VERSION "dbc-export 1 2026.26.6.5"

NS_ :

BS_:

BU_: ADSP APB APP APS APSB BB BMS CC CMP CMPD CP DAS DI DIF DIR DPB EPAS3P EPAS3S EPASTP EPASTS EPBL EPBR ESP EVSE FC GTW HCML HCMR HVP IBST ICR IDB LS OCS1P PARK PCS PCS2 PM PMF PMR PNCD PTC RADC RCM RCM2 RCM3 RCU SCCM SCM SCS SDCR TAS TCU TCU2 TPMS TRCM UI UIS UMC USM V2G VC VCBATT VCBATT0 VCBATT1 VCBATT2 VCCC VCFRONT VCFRONT1 VCFRONT2 VCLEFT VCRIGHT VCSEAT2L VCSEAT2R VCSEC VEH

BO_ 832 VCFRONT_alertMatrix: 8 VCFRONT
 SG_ VCFRONT_matrixIndex M : 0|4@1+ (1,0) [0|15] "" Vector__XXX
 SG_ VCFRONT_a001_WatchdogReset m0 : 4|1@1+ (1,0) [0|1] "" Vector__XXX
 SG_ VCFRONT_a002_PowerLossReset m0 : 5|1@1+ (1,0) [0|1] "" Vector__XXX
 SG_ VCFRONT_a003_SWAssertion m0 : 6|1@1+ (1,0) [0|1] "" Vector__XXX
 SG_ VCFRONT_a004_adaptiveHeadlightsU m0 : 7|1@1+ (1,0) [0|1] "" Vector__XXX
 SG_ VCFRONT_a005_CANTXError m0 : 8|1@1+ (1,0) [0|1] "" Vector__XXX
 SG_ VCFRONT_a006_CANTX_cyclicError m0 : 9|1@1+ (1,0) [0|1] "" Vector__XXX
 SG_ VCFRONT_a008_adaptiveHeadlightsU m0 : 11|1@1+ (1,0) [0|1] "" Vector__XXX
 SG_ VCFRONT_a009_LCCPurgeAttempted m0 : 12|1@1+ (1,0) [0|1] "" Vector__XXX
 SG_ VCFRONT_a010_ExtSupplyVoltError m0 : 13|1@1+ (1,0) [0|1] "" Vector__XXX
 SG_ VCFRONT_a012_CPUReset m0 : 15|1@1+ (1,0) [0|1] "" Vector__XXX
 SG_ VCFRONT_a013_AlertManagerFault m0 : 16|1@1+ (1,0) [0|1] "" Vector__XXX
 SG_ VCFRONT_a015_NVMMError m0 : 18|1@1+ (1,0) [0|1] "" Vector__XXX
 SG_ VCFRONT_a016_NVMMRecordError m0 : 19|1@1+ (1,0) [0|1] "" Vector__XXX
 SG_ VCFRONT_a017_NVMMStatusDbg m0 : 20|1@1+ (1,0) [0|1] "" Vector__XXX
 SG_ VCFRONT_a021_TaskSchedulerError m0 : 24|1@1+ (1,0) [0|1] "" Vector__XXX
 SG_ VCFRONT_a022_TaskInitError m0 : 25|1@1+ (1,0) [0|1] "" Vector__XXX
 SG_ VCFRONT_a029_CoreDump m0 : 32|1@1+ (1,0) [0|1] "" Vector__XXX
 SG_ VCFRONT_a030_ECULogUploadRequest m0 : 33|1@1+ (1,0) [0|1] "" Vector__XXX
 SG_ VCFRONT_a031_UDSActive m0 : 34|1@1+ (1,0) [0|1] "" Vector__XXX
 SG_ VCFRONT_a032_ipcWatchdogExpired m0 : 35|1@1+ (1,0) [0|1] "" Vector__XXX
 SG_ VCFRONT_a033_eccNonCorrectableEr m0 : 36|1@1+ (1,0) [0|1] "" Vector__XXX
 SG_ VCFRONT_a038_ProtFaultInfo m0 : 41|1@1+ (1,0) [0|1] "" Vector__XXX
 SG_ VCFRONT_a039_ProtFaultAddress m0 : 42|1@1+ (1,0) [0|1] "" Vector__XXX
 SG_ VCFRONT_a040_Backtrace m0 : 43|1@1+ (1,0) [0|1] "" Vector__XXX
 SG_ VCFRONT_a041_HighCPULoad m0 : 44|1@1+ (1,0) [0|1] "" Vector__XXX
 SG_ VCFRONT_a042_HighStackUsage m0 : 45|1@1+ (1,0) [0|1] "" Vector__XXX
 SG_ VCFRONT_a043_Task1msError m0 : 46|1@1+ (1,0) [0|1] "" Vector__XXX
 SG_ VCFRONT_a044_Task10msError m0 : 47|1@1+ (1,0) [0|1] "" Vector__XXX
 SG_ VCFRONT_a045_Task100msError m0 : 48|1@1+ (1,0) [0|1] "" Vector__XXX
 SG_ VCFRONT_a046_Task1000msError m0 : 49|1@1+ (1,0) [0|1] "" Vector__XXX
 SG_ VCFRONT_a047_resetReason m0 : 50|1@1+ (1,0) [0|1] "" Vector__XXX
 SG_ VCFRONT_a053_wiperCommErrorUser m0 : 56|1@1+ (1,0) [0|1] "" Vector__XXX
 SG_ VCFRONT_a054_compressorLowFlowUs m0 : 57|1@1+ (1,0) [0|1] "" Vector__XXX
 SG_ VCFRONT_a057_HVP_MIA m0 : 60|1@1+ (1,0) [0|1] "" Vector__XXX
 SG_ VCFRONT_a058_inputRHighSyncDebug m0 : 61|1@1+ (1,0) [0|1] "" Vector__XXX
 SG_ VCFRONT_a059_inputResistanceHigh m0 : 62|1@1+ (1,0) [0|1] "" Vector__XXX
 SG_ VCFRONT_a060_engineeringBuild m0 : 63|1@1+ (1,0) [0|1] "" Vector__XXX
 SG_ VCFRONT_a061_XCPConnected m1 : 4|1@1+ (1,0) [0|1] "" Vector__XXX
 SG_ VCFRONT_a062_XCPWasConnected m1 : 5|1@1+ (1,0) [0|1] "" Vector__XXX
 SG_ VCFRONT_a063_SwitchFault m1 : 6|1@1+ (1,0) [0|1] "" Vector__XXX
 SG_ VCFRONT_a064_busSleepReqTimeout m1 : 7|1@1+ (1,0) [0|1] "" Vector__XXX
 SG_ VCFRONT_a082_VCRIGHT_IPC_MIA m1 : 25|1@1+ (1,0) [0|1] "" Vector__XXX
 SG_ VCFRONT_a083_VCLEFT_IPC_MIA m1 : 26|1@1+ (1,0) [0|1] "" Vector__XXX
 SG_ VCFRONT_a084_TPMS_MIA m1 : 27|1@1+ (1,0) [0|1] "" Vector__XXX
 SG_ VCFRONT_a085_CCCM_MIA m1 : 28|1@1+ (1,0) [0|1] "" Vector__XXX
 SG_ VCFRONT_a086_VCBATT_MIA m1 : 29|1@1+ (1,0) [0|1] "" Vector__XXX
 SG_ VCFRONT_a087_DIREL_MIA m1 : 30|1@1+ (1,0) [0|1] "" Vector__XXX
 SG_ VCFRONT_a088_DIRER_MIA m1 : 31|1@1+ (1,0) [0|1] "" Vector__XXX
 SG_ VCFRONT_a089_IBST_MIA m1 : 32|1@1+ (1,0) [0|1] "" Vector__XXX
 SG_ VCFRONT_a090_APS_MIA m1 : 33|1@1+ (1,0) [0|1] "" Vector__XXX
 SG_ VCFRONT_a091_CMPD_MIA m1 : 34|1@1+ (1,0) [0|1] "" Vector__XXX
 SG_ VCFRONT_a092_VCSEATD_MIA m1 : 35|1@1+ (1,0) [0|1] "" Vector__XXX
 SG_ VCFRONT_a093_VCSEATP_MIA m1 : 36|1@1+ (1,0) [0|1] "" Vector__XXX
 SG_ VCFRONT_a094_EPAS3P_MIA m1 : 37|1@1+ (1,0) [0|1] "" Vector__XXX
 SG_ VCFRONT_a095_CHG_MIA m1 : 38|1@1+ (1,0) [0|1] "" Vector__XXX
 SG_ VCFRONT_a096_OCS1P_MIA m1 : 39|1@1+ (1,0) [0|1] "" Vector__XXX
 SG_ VCFRONT_a097_CMP_MIA m1 : 40|1@1+ (1,0) [0|1] "" Vector__XXX
 SG_ VCFRONT_a098_DIR_MIA m1 : 41|1@1+ (1,0) [0|1] "" Vector__XXX
 SG_ VCFRONT_a099_PARK_MIA m1 : 42|1@1+ (1,0) [0|1] "" Vector__XXX
 SG_ VCFRONT_a100_CANbus_MIA m1 : 43|1@1+ (1,0) [0|1] "" Vector__XXX
 SG_ VCFRONT_a101_PM_MIA m1 : 44|1@1+ (1,0) [0|1] "" Vector__XXX
 SG_ VCFRONT_a102_PTC_MIA m1 : 45|1@1+ (1,0) [0|1] "" Vector__XXX
 SG_ VCFRONT_a103_CP_MIA m1 : 46|1@1+ (1,0) [0|1] "" Vector__XXX
 SG_ VCFRONT_a104_DAS_MIA m1 : 47|1@1+ (1,0) [0|1] "" Vector__XXX
 SG_ VCFRONT_a105_TAS_MIA m1 : 48|1@1+ (1,0) [0|1] "" Vector__XXX
 SG_ VCFRONT_a106_PCS_MIA m1 : 49|1@1+ (1,0) [0|1] "" Vector__XXX
 SG_ VCFRONT_a107_BMS_MIA m1 : 50|1@1+ (1,0) [0|1] "" Vector__XXX
 SG_ VCFRONT_a108_DIF_MIA m1 : 51|1@1+ (1,0) [0|1] "" Vector__XXX
 SG_ VCFRONT_a109_RCM_MIA m1 : 52|1@1+ (1,0) [0|1] "" Vector__XXX
 SG_ VCFRONT_a110_GTW_MIA m1 : 53|1@1+ (1,0) [0|1] "" Vector__XXX
 SG_ VCFRONT_a111_EPBR_MIA m1 : 54|1@1+ (1,0) [0|1] "" Vector__XXX
 SG_ VCFRONT_a112_EPBL_MIA m1 : 55|1@1+ (1,0) [0|1] "" Vector__XXX
 SG_ VCFRONT_a113_UI_MIA m1 : 56|1@1+ (1,0) [0|1] "" Vector__XXX
 SG_ VCFRONT_a114_ESP_MIA m1 : 57|1@1+ (1,0) [0|1] "" Vector__XXX
 SG_ VCFRONT_a115_VCSEC_MIA m1 : 58|1@1+ (1,0) [0|1] "" Vector__XXX
 SG_ VCFRONT_a116_VCRIGHT_MIA m1 : 59|1@1+ (1,0) [0|1] "" Vector__XXX
 SG_ VCFRONT_a117_VCLEFT_MIA m1 : 60|1@1+ (1,0) [0|1] "" Vector__XXX
 SG_ VCFRONT_a118_VCFRONT_MIA m1 : 61|1@1+ (1,0) [0|1] "" Vector__XXX
 SG_ VCFRONT_a119_SCCM_MIA m1 : 62|1@1+ (1,0) [0|1] "" Vector__XXX
 SG_ VCFRONT_a120_DI_DRIVE_MIA m1 : 63|1@1+ (1,0) [0|1] "" Vector__XXX
 SG_ VCFRONT_a121_pumpBatICLatchFault m2 : 4|1@1+ (1,0) [0|1] "" Vector__XXX
 SG_ VCFRONT_a122_pumpBatICWarning m2 : 5|1@1+ (1,0) [0|1] "" Vector__XXX
 SG_ VCFRONT_a123_pumpPtICLatchFault m2 : 6|1@1+ (1,0) [0|1] "" Vector__XXX
 SG_ VCFRONT_a124_pumpPtICWarning m2 : 7|1@1+ (1,0) [0|1] "" Vector__XXX
 SG_ VCFRONT_a125_thmlFanICLatchFault m2 : 8|1@1+ (1,0) [0|1] "" Vector__XXX
 SG_ VCFRONT_a126_thmlFanICWarning m2 : 9|1@1+ (1,0) [0|1] "" Vector__XXX
 SG_ VCFRONT_a127_vcleftEFuseTrip m2 : 10|1@1+ (1,0) [0|1] "" Vector__XXX
 SG_ VCFRONT_a128_vcrightEFuseTrip m2 : 11|1@1+ (1,0) [0|1] "" Vector__XXX
 SG_ VCFRONT_a129_pcsEFuseTrip m2 : 12|1@1+ (1,0) [0|1] "" Vector__XXX
 SG_ VCFRONT_a130_epas3pEFuseTrip m2 : 13|1@1+ (1,0) [0|1] "" Vector__XXX
 SG_ VCFRONT_a131_epas3sEFuseTrip m2 : 14|1@1+ (1,0) [0|1] "" Vector__XXX
 SG_ VCFRONT_a132_iBoosterEFuseTrip m2 : 15|1@1+ (1,0) [0|1] "" Vector__XXX
 SG_ VCFRONT_a133_espEFuseTrip m2 : 16|1@1+ (1,0) [0|1] "" Vector__XXX
 SG_ VCFRONT_a134_fusedHighEFuseTrip m2 : 17|1@1+ (1,0) [0|1] "" Vector__XXX
 SG_ VCFRONT_a135_coolantLevelLow m2 : 18|1@1+ (1,0) [0|1] "" Vector__XXX
 SG_ VCFRONT_a136_refrigDischTempSns m2 : 19|1@1+ (1,0) [0|1] "" Vector__XXX
 SG_ VCFRONT_a137_refrigDischPresSns m2 : 20|1@1+ (1,0) [0|1] "" Vector__XXX
 SG_ VCFRONT_a138_refrigSuctTempSns m2 : 21|1@1+ (1,0) [0|1] "" Vector__XXX
 SG_ VCFRONT_a139_refrigSuctPresSns m2 : 22|1@1+ (1,0) [0|1] "" Vector__XXX
 SG_ VCFRONT_a140_coolantTempPtSns m2 : 23|1@1+ (1,0) [0|1] "" Vector__XXX
 SG_ VCFRONT_a141_coolantTempBatSns m2 : 24|1@1+ (1,0) [0|1] "" Vector__XXX
 SG_ VCFRONT_a142_exvMotorFault m2 : 25|1@1+ (1,0) [0|1] "" Vector__XXX
 SG_ VCFRONT_a143_pumpBatICTransFault m2 : 26|1@1+ (1,0) [0|1] "" Vector__XXX
 SG_ VCFRONT_a144_pumpPtICTransFault m2 : 27|1@1+ (1,0) [0|1] "" Vector__XXX
 SG_ VCFRONT_a145_thmlFanICTransFault m2 : 28|1@1+ (1,0) [0|1] "" Vector__XXX
 SG_ VCFRONT_a146_pumpBatSoftStall m2 : 29|1@1+ (1,0) [0|1] "" Vector__XXX
 SG_ VCFRONT_a147_pumpPtSoftStall m2 : 30|1@1+ (1,0) [0|1] "" Vector__XXX
 SG_ VCFRONT_a148_thmlFanSoftStall m2 : 31|1@1+ (1,0) [0|1] "" Vector__XXX
 SG_ VCFRONT_a149_BLEFrontPowerCycled m2 : 32|1@1+ (1,0) [0|1] "" Vector__XXX
 SG_ VCFRONT_a150_pumpBatLowRPMCBang m2 : 33|1@1+ (1,0) [0|1] "" Vector__XXX
 SG_ VCFRONT_a151_pumpPtLowRPMCBang m2 : 34|1@1+ (1,0) [0|1] "" Vector__XXX
 SG_ VCFRONT_a152_thmlFanLowRPMCBang m2 : 35|1@1+ (1,0) [0|1] "" Vector__XXX
 SG_ VCFRONT_a153_userPresenceDisplay m2 : 36|1@1+ (1,0) [0|1] "" Vector__XXX
 SG_ VCFRONT_a154_prechargeDCRData1 m2 : 37|1@1+ (1,0) [0|1] "" Vector__XXX
 SG_ VCFRONT_a155_prechargeDCRData2 m2 : 38|1@1+ (1,0) [0|1] "" Vector__XXX
 SG_ VCFRONT_a156_louverBlockage m2 : 39|1@1+ (1,0) [0|1] "" Vector__XXX
 SG_ VCFRONT_a157_louverBreakage m2 : 40|1@1+ (1,0) [0|1] "" Vector__XXX
 SG_ VCFRONT_a158_louverDisconnected m2 : 41|1@1+ (1,0) [0|1] "" Vector__XXX
 SG_ VCFRONT_a159_coolantValveFault m2 : 42|1@1+ (1,0) [0|1] "" Vector__XXX
 SG_ VCFRONT_a160_compressorInhibited m2 : 43|1@1+ (1,0) [0|1] "" Vector__XXX
 SG_ VCFRONT_a161_compressorSelfFault m2 : 44|1@1+ (1,0) [0|1] "" Vector__XXX
 SG_ VCFRONT_a162_compressorInhibited m2 : 45|1@1+ (1,0) [0|1] "" Vector__XXX
 SG_ VCFRONT_a163_compressorDisabledF m2 : 46|1@1+ (1,0) [0|1] "" Vector__XXX
 SG_ VCFRONT_a164_eFuseLckoutMissing m2 : 47|1@1+ (1,0) [0|1] "" Vector__XXX
 SG_ VCFRONT_a165_unxpctdEFuseLckout m2 : 48|1@1+ (1,0) [0|1] "" Vector__XXX
 SG_ VCFRONT_a166_rightHCMMIA m2 : 49|1@1+ (1,0) [0|1] "" Vector__XXX
 SG_ VCFRONT_a167_leftHCMMIA m2 : 50|1@1+ (1,0) [0|1] "" Vector__XXX
 SG_ VCFRONT_a168_hcmShortToVBAT m2 : 51|1@1+ (1,0) [0|1] "" Vector__XXX
 SG_ VCFRONT_a169_hcmPhaseEnableFail m2 : 52|1@1+ (1,0) [0|1] "" Vector__XXX
 SG_ VCFRONT_a170_hcmUnderVoltage m2 : 53|1@1+ (1,0) [0|1] "" Vector__XXX
 SG_ VCFRONT_a171_driveBlckdByMsmtch m2 : 54|1@1+ (1,0) [0|1] "" Vector__XXX
 SG_ VCFRONT_a172_wsteHtBlckdByMsmtch m2 : 55|1@1+ (1,0) [0|1] "" Vector__XXX
 SG_ VCFRONT_a173_HVBlckdByMsmtch m2 : 56|1@1+ (1,0) [0|1] "" Vector__XXX
 SG_ VCFRONT_a174_driveNotAuthed m2 : 57|1@1+ (1,0) [0|1] "" Vector__XXX
 SG_ VCFRONT_a175_ambientTempSns m2 : 58|1@1+ (1,0) [0|1] "" Vector__XXX
 SG_ VCFRONT_a176_vehicleInSelfTest m2 : 59|1@1+ (1,0) [0|1] "" Vector__XXX
 SG_ VCFRONT_a177_mcuAudioEFuseFault m2 : 60|1@1+ (1,0) [0|1] "" Vector__XXX
 SG_ VCFRONT_a178_compLiquidPumpOut m2 : 61|1@1+ (1,0) [0|1] "" Vector__XXX
 SG_ VCFRONT_a179_highLVAmpsIntoPCS m2 : 62|1@1+ (1,0) [0|1] "" Vector__XXX
 SG_ VCFRONT_a180_DCDCNotSupportingLV m2 : 63|1@1+ (1,0) [0|1] "" Vector__XXX
 SG_ VCFRONT_a181_homelinkMIA m3 : 4|1@1+ (1,0) [0|1] "" Vector__XXX
 SG_ VCFRONT_a182_replaceLVBattery m3 : 5|1@1+ (1,0) [0|1] "" Vector__XXX
 SG_ VCFRONT_a183_replaceLVBattery2 m3 : 6|1@1+ (1,0) [0|1] "" Vector__XXX
 SG_ VCFRONT_a184_cabinCoolingPerform m3 : 7|1@1+ (1,0) [0|1] "" Vector__XXX
 SG_ VCFRONT_a185_washerFluidLow m3 : 8|1@1+ (1,0) [0|1] "" Vector__XXX
 SG_ VCFRONT_a186_noDriveChgCableCon m3 : 9|1@1+ (1,0) [0|1] "" Vector__XXX
 SG_ VCFRONT_a187_busesNotSleeping m3 : 10|1@1+ (1,0) [0|1] "" Vector__XXX
 SG_ VCFRONT_a188_sleepFailed m3 : 11|1@1+ (1,0) [0|1] "" Vector__XXX
 SG_ VCFRONT_a189_IBSMIA m3 : 12|1@1+ (1,0) [0|1] "" Vector__XXX
 SG_ VCFRONT_a190_linSchedulingInfo m3 : 13|1@1+ (1,0) [0|1] "" Vector__XXX
 SG_ VCFRONT_a191_exitDriveLowLVBusVo m3 : 14|1@1+ (1,0) [0|1] "" Vector__XXX
 SG_ VCFRONT_a192_vehicleLoadShed m3 : 15|1@1+ (1,0) [0|1] "" Vector__XXX
 SG_ VCFRONT_a193_mcuAudioRetry m3 : 16|1@1+ (1,0) [0|1] "" Vector__XXX
 SG_ VCFRONT_a194_iBoosterRetry m3 : 17|1@1+ (1,0) [0|1] "" Vector__XXX
 SG_ VCFRONT_a195_drveBlckdVltgeTooHg m3 : 18|1@1+ (1,0) [0|1] "" Vector__XXX
 SG_ VCFRONT_a196_discnctdLVBattery m3 : 19|1@1+ (1,0) [0|1] "" Vector__XXX
 SG_ VCFRONT_a197_prechargeDCRData3 m3 : 20|1@1+ (1,0) [0|1] "" Vector__XXX
 SG_ VCFRONT_a198_PRVCANOverterminate m3 : 21|1@1+ (1,0) [0|1] "" Vector__XXX
 SG_ VCFRONT_a199_PRVCANUndertrminate m3 : 22|1@1+ (1,0) [0|1] "" Vector__XXX
 SG_ VCFRONT_a200_vcleftSelfTestFail m3 : 23|1@1+ (1,0) [0|1] "" Vector__XXX
 SG_ VCFRONT_a201_vcrightSelfTestFail m3 : 24|1@1+ (1,0) [0|1] "" Vector__XXX
 SG_ VCFRONT_a202_pcsSelfTestFail m3 : 25|1@1+ (1,0) [0|1] "" Vector__XXX
 SG_ VCFRONT_a203_epas3pSelfTestFail m3 : 26|1@1+ (1,0) [0|1] "" Vector__XXX
 SG_ VCFRONT_a204_epas3sSelfTestFail m3 : 27|1@1+ (1,0) [0|1] "" Vector__XXX
 SG_ VCFRONT_a205_iBoosterSelfTestFai m3 : 28|1@1+ (1,0) [0|1] "" Vector__XXX
 SG_ VCFRONT_a206_espSelfTestFail m3 : 29|1@1+ (1,0) [0|1] "" Vector__XXX
 SG_ VCFRONT_a207_vbatFusdSelfTestFai m3 : 30|1@1+ (1,0) [0|1] "" Vector__XXX
 SG_ VCFRONT_a208_brakeFluidLow m3 : 31|1@1+ (1,0) [0|1] "" Vector__XXX
 SG_ VCFRONT_a209_brakeFluidSNA m3 : 32|1@1+ (1,0) [0|1] "" Vector__XXX
 SG_ VCFRONT_a210_coolantValveCalib m3 : 33|1@1+ (1,0) [0|1] "" Vector__XXX
 SG_ VCFRONT_a211_I2CFault m3 : 34|1@1+ (1,0) [0|1] "" Vector__XXX
 SG_ VCFRONT_a212_IBSOverTemp m3 : 35|1@1+ (1,0) [0|1] "" Vector__XXX
 SG_ VCFRONT_a213_LVOvercharge m3 : 36|1@1+ (1,0) [0|1] "" Vector__XXX
 SG_ VCFRONT_a214_ptPumpCompromised m3 : 37|1@1+ (1,0) [0|1] "" Vector__XXX
 SG_ VCFRONT_a215_ptPumpMIA m3 : 38|1@1+ (1,0) [0|1] "" Vector__XXX
 SG_ VCFRONT_a216_powerCutoffImminent m3 : 39|1@1+ (1,0) [0|1] "" Vector__XXX
 SG_ VCFRONT_a217_battPumpCompromised m3 : 40|1@1+ (1,0) [0|1] "" Vector__XXX
 SG_ VCFRONT_a218_socMonitorDetectedT m3 : 41|1@1+ (1,0) [0|1] "" Vector__XXX
 SG_ VCFRONT_a219_LVVoltFloorRchd m3 : 42|1@1+ (1,0) [0|1] "" Vector__XXX
 SG_ VCFRONT_a220_reverseBatteryFault m3 : 43|1@1+ (1,0) [0|1] "" Vector__XXX
 SG_ VCFRONT_a221_leftTurnLightFault m3 : 44|1@1+ (1,0) [0|1] "" Vector__XXX
 SG_ VCFRONT_a222_rightTurnLightFault m3 : 45|1@1+ (1,0) [0|1] "" Vector__XXX
 SG_ VCFRONT_a223_12VTempSensDiscnect m3 : 46|1@1+ (1,0) [0|1] "" Vector__XXX
 SG_ VCFRONT_a224_revBatChrgPmpFault m3 : 47|1@1+ (1,0) [0|1] "" Vector__XXX
 SG_ VCFRONT_a225_driveBlckdByShowroo m3 : 48|1@1+ (1,0) [0|1] "" Vector__XXX
 SG_ VCFRONT_a226_battPumpMIA m3 : 49|1@1+ (1,0) [0|1] "" Vector__XXX
 SG_ VCFRONT_a227_radFanCompromised m3 : 50|1@1+ (1,0) [0|1] "" Vector__XXX
 SG_ VCFRONT_a228_pumpBatFbkSanity m3 : 51|1@1+ (1,0) [0|1] "" Vector__XXX
 SG_ VCFRONT_a229_pumpPtFbkSanity m3 : 52|1@1+ (1,0) [0|1] "" Vector__XXX
 SG_ VCFRONT_a230_thmlFanFbkSanity m3 : 53|1@1+ (1,0) [0|1] "" Vector__XXX
 SG_ VCFRONT_a231_12VTempSensShort m3 : 54|1@1+ (1,0) [0|1] "" Vector__XXX
 SG_ VCFRONT_a232_lowSideControllerHi m3 : 55|1@1+ (1,0) [0|1] "" Vector__XXX
 SG_ VCFRONT_a233_autopilot1EFuseFaul m3 : 56|1@1+ (1,0) [0|1] "" Vector__XXX
 SG_ VCFRONT_a234_autopilot2EFuseFaul m3 : 57|1@1+ (1,0) [0|1] "" Vector__XXX
 SG_ VCFRONT_a235_ptTempSnsIrrational m3 : 58|1@1+ (1,0) [0|1] "" Vector__XXX
 SG_ VCFRONT_a236_batTempSnsIrrationa m3 : 59|1@1+ (1,0) [0|1] "" Vector__XXX
 SG_ VCFRONT_a237_pumpBatChipComms m3 : 60|1@1+ (1,0) [0|1] "" Vector__XXX
 SG_ VCFRONT_a238_pumpPtChipComms m3 : 61|1@1+ (1,0) [0|1] "" Vector__XXX
 SG_ VCFRONT_a239_thmlFanChipComms m3 : 62|1@1+ (1,0) [0|1] "" Vector__XXX
 SG_ VCFRONT_a240_lowSideCompromised m3 : 63|1@1+ (1,0) [0|1] "" Vector__XXX
 SG_ VCFRONT_a241_radFanMIA m4 : 4|1@1+ (1,0) [0|1] "" Vector__XXX
 SG_ VCFRONT_a242_drveBlckdVltgeTooLo m4 : 5|1@1+ (1,0) [0|1] "" Vector__XXX
 SG_ VCFRONT_a243_LVOverchargeInstc m4 : 6|1@1+ (1,0) [0|1] "" Vector__XXX
 SG_ VCFRONT_a244_sleepBypassFault m4 : 7|1@1+ (1,0) [0|1] "" Vector__XXX
 SG_ VCFRONT_a245_pump1EFuseFault m4 : 8|1@1+ (1,0) [0|1] "" Vector__XXX
 SG_ VCFRONT_a246_pump2EFuseFault m4 : 9|1@1+ (1,0) [0|1] "" Vector__XXX
 SG_ VCFRONT_a247_evapSolenoidFault m4 : 10|1@1+ (1,0) [0|1] "" Vector__XXX
 SG_ VCFRONT_a248_voltageOutOfSpec m4 : 11|1@1+ (1,0) [0|1] "" Vector__XXX
 SG_ VCFRONT_a249_coolantValveBadMode m4 : 12|1@1+ (1,0) [0|1] "" Vector__XXX
 SG_ VCFRONT_a250_headlampsNotAimed m4 : 13|1@1+ (1,0) [0|1] "" Vector__XXX
 SG_ VCFRONT_a251_UIWakeupTrigger m4 : 14|1@1+ (1,0) [0|1] "" Vector__XXX
 SG_ VCFRONT_a252_controllerWakeup m4 : 15|1@1+ (1,0) [0|1] "" Vector__XXX
 SG_ VCFRONT_a253_maxChrgeSssionTmeou m4 : 16|1@1+ (1,0) [0|1] "" Vector__XXX
 SG_ VCFRONT_a254_pumpBatStopped m4 : 17|1@1+ (1,0) [0|1] "" Vector__XXX
 SG_ VCFRONT_a255_pumpPtStopped m4 : 18|1@1+ (1,0) [0|1] "" Vector__XXX
 SG_ VCFRONT_a256_compTornShaftSeal m4 : 19|1@1+ (1,0) [0|1] "" Vector__XXX
 SG_ VCFRONT_a257_portExpanderVOR m4 : 20|1@1+ (1,0) [0|1] "" Vector__XXX
 SG_ VCFRONT_a258_resistanceEstimatio m4 : 21|1@1+ (1,0) [0|1] "" Vector__XXX
 SG_ VCFRONT_a259_LVVoltageDropOnHigh m4 : 22|1@1+ (1,0) [0|1] "" Vector__XXX
 SG_ VCFRONT_a260_deadLVBattery m4 : 23|1@1+ (1,0) [0|1] "" Vector__XXX
 SG_ VCFRONT_a261_vcleftVoltageMismat m4 : 24|1@1+ (1,0) [0|1] "" Vector__XXX
 SG_ VCFRONT_a262_vcrightVoltageMisma m4 : 25|1@1+ (1,0) [0|1] "" Vector__XXX
 SG_ VCFRONT_a263_pcsVoltageMismatch m4 : 26|1@1+ (1,0) [0|1] "" Vector__XXX
 SG_ VCFRONT_a264_iBoosterVoltageMism m4 : 27|1@1+ (1,0) [0|1] "" Vector__XXX
 SG_ VCFRONT_a265_ESPVoltageMismatch m4 : 28|1@1+ (1,0) [0|1] "" Vector__XXX
 SG_ VCFRONT_a266_EPAS3pVoltageMismat m4 : 29|1@1+ (1,0) [0|1] "" Vector__XXX
 SG_ VCFRONT_a267_EPAS3sVoltageMismat m4 : 30|1@1+ (1,0) [0|1] "" Vector__XXX
 SG_ VCFRONT_a268_vbatFusedVoltageMis m4 : 31|1@1+ (1,0) [0|1] "" Vector__XXX
 SG_ VCFRONT_a269_drveBlckdVltgeTooLo m4 : 32|1@1+ (1,0) [0|1] "" Vector__XXX
 SG_ VCFRONT_a270_prechargeFailed m4 : 33|1@1+ (1,0) [0|1] "" Vector__XXX
 SG_ VCFRONT_a271_LVBatteryPermSuppor m4 : 34|1@1+ (1,0) [0|1] "" Vector__XXX
 SG_ VCFRONT_a273_wiperFrictionModelF m4 : 36|1@1+ (1,0) [0|1] "" Vector__XXX
 SG_ VCFRONT_a274_failureToPrechargeR m4 : 37|1@1+ (1,0) [0|1] "" Vector__XXX
 SG_ VCFRONT_a275_TLVBMS_BmbCommunica m4 : 38|1@1+ (1,0) [0|1] "" Vector__XXX
 SG_ VCFRONT_a276_TLVBMS_BmbDataInteg m4 : 39|1@1+ (1,0) [0|1] "" Vector__XXX
 SG_ VCFRONT_a277_TLVBMS_BmbStatusReg m4 : 40|1@1+ (1,0) [0|1] "" Vector__XXX
 SG_ VCFRONT_a278_TLVBMS_BmbHwOverCur m4 : 41|1@1+ (1,0) [0|1] "" Vector__XXX
 SG_ VCFRONT_a279_refrigLiquidTempSns m4 : 42|1@1+ (1,0) [0|1] "" Vector__XXX
 SG_ VCFRONT_a280_refrigLiquidPresSns m4 : 43|1@1+ (1,0) [0|1] "" Vector__XXX
 SG_ VCFRONT_a281_alcoholInterlockBlo m4 : 44|1@1+ (1,0) [0|1] "" Vector__XXX
 SG_ VCFRONT_a282_coolantLevelSensorF m4 : 45|1@1+ (1,0) [0|1] "" Vector__XXX
 SG_ VCFRONT_a283_thmlFanLimitedByCur m4 : 46|1@1+ (1,0) [0|1] "" Vector__XXX
 SG_ VCFRONT_a284_chillerExvFault m4 : 47|1@1+ (1,0) [0|1] "" Vector__XXX
 SG_ VCFRONT_a285_evaporatorExvFault m4 : 48|1@1+ (1,0) [0|1] "" Vector__XXX
 SG_ VCFRONT_a286_recircExvFault m4 : 49|1@1+ (1,0) [0|1] "" Vector__XXX
 SG_ VCFRONT_a287_lccExvFault m4 : 50|1@1+ (1,0) [0|1] "" Vector__XXX
 SG_ VCFRONT_a288_ccLeftExvFault m4 : 51|1@1+ (1,0) [0|1] "" Vector__XXX
 SG_ VCFRONT_a289_ccRightExvFault m4 : 52|1@1+ (1,0) [0|1] "" Vector__XXX
 SG_ VCFRONT_a290_leftFogLightFault m4 : 53|1@1+ (1,0) [0|1] "" Vector__XXX
 SG_ VCFRONT_a291_rightFogLightFault m4 : 54|1@1+ (1,0) [0|1] "" Vector__XXX
 SG_ VCFRONT_a292_sideMarkerLightPipe m4 : 55|1@1+ (1,0) [0|1] "" Vector__XXX
 SG_ VCFRONT_a293_interiorFrunkLightF m4 : 56|1@1+ (1,0) [0|1] "" Vector__XXX
 SG_ VCFRONT_a294_leftSideRepeaterLig m4 : 57|1@1+ (1,0) [0|1] "" Vector__XXX
 SG_ VCFRONT_a295_rightSideRepeaterLi m4 : 58|1@1+ (1,0) [0|1] "" Vector__XXX
 SG_ VCFRONT_a296_turnSignalIssue m4 : 59|1@1+ (1,0) [0|1] "" Vector__XXX
 SG_ VCFRONT_a297_TLVBMS_BmbHwOverTem m4 : 60|1@1+ (1,0) [0|1] "" Vector__XXX
 SG_ VCFRONT_a298_radiatorLowAirFlowD m4 : 61|1@1+ (1,0) [0|1] "" Vector__XXX
 SG_ VCFRONT_a299_homelinkConfigurati m4 : 62|1@1+ (1,0) [0|1] "" Vector__XXX
 SG_ VCFRONT_a300_louverActuatorSwapD m4 : 63|1@1+ (1,0) [0|1] "" Vector__XXX
 SG_ VCFRONT_a301_wipersFactoryDisabl m5 : 4|1@1+ (1,0) [0|1] "" Vector__XXX
 SG_ VCFRONT_a302_wiperCommError m5 : 5|1@1+ (1,0) [0|1] "" Vector__XXX
 SG_ VCFRONT_a303_frunkAccessPostActi m5 : 6|1@1+ (1,0) [0|1] "" Vector__XXX
 SG_ VCFRONT_a304_frunkReleaseFailed m5 : 7|1@1+ (1,0) [0|1] "" Vector__XXX
 SG_ VCFRONT_a305_frunkPriOverCurrent m5 : 8|1@1+ (1,0) [0|1] "" Vector__XXX
 SG_ VCFRONT_a306_frunkPriUnderCurren m5 : 9|1@1+ (1,0) [0|1] "" Vector__XXX
 SG_ VCFRONT_a307_frunkSecOverCurrent m5 : 10|1@1+ (1,0) [0|1] "" Vector__XXX
 SG_ VCFRONT_a308_frunkSecUnderCurren m5 : 11|1@1+ (1,0) [0|1] "" Vector__XXX
 SG_ VCFRONT_a309_frunkEmergencyRelea m5 : 12|1@1+ (1,0) [0|1] "" Vector__XXX
 SG_ VCFRONT_a310_vcleftOvertempSlope m5 : 13|1@1+ (1,0) [0|1] "" Vector__XXX
 SG_ VCFRONT_a311_vcrightOvertempSlop m5 : 14|1@1+ (1,0) [0|1] "" Vector__XXX
 SG_ VCFRONT_a312_pcsOvertempSlope m5 : 15|1@1+ (1,0) [0|1] "" Vector__XXX
 SG_ VCFRONT_a313_epas3pOvertempSlope m5 : 16|1@1+ (1,0) [0|1] "" Vector__XXX
 SG_ VCFRONT_a314_epas3sOvertempSlope m5 : 17|1@1+ (1,0) [0|1] "" Vector__XXX
 SG_ VCFRONT_a315_iboosterOvertempSlo m5 : 18|1@1+ (1,0) [0|1] "" Vector__XXX
 SG_ VCFRONT_a316_espOvertempSlope m5 : 19|1@1+ (1,0) [0|1] "" Vector__XXX
 SG_ VCFRONT_a317_vbatFusedOvertempSl m5 : 20|1@1+ (1,0) [0|1] "" Vector__XXX
 SG_ VCFRONT_a318_vcleftOvertempMax m5 : 21|1@1+ (1,0) [0|1] "" Vector__XXX
 SG_ VCFRONT_a319_vcrightOvertempMax m5 : 22|1@1+ (1,0) [0|1] "" Vector__XXX
 SG_ VCFRONT_a320_pcsOvertempMax m5 : 23|1@1+ (1,0) [0|1] "" Vector__XXX
 SG_ VCFRONT_a321_epas3pOvertempMax m5 : 24|1@1+ (1,0) [0|1] "" Vector__XXX
 SG_ VCFRONT_a322_epas3sOvertempMax m5 : 25|1@1+ (1,0) [0|1] "" Vector__XXX
 SG_ VCFRONT_a323_iboosterOvertempMax m5 : 26|1@1+ (1,0) [0|1] "" Vector__XXX
 SG_ VCFRONT_a324_espOvertempMax m5 : 27|1@1+ (1,0) [0|1] "" Vector__XXX
 SG_ VCFRONT_a325_vbatFusedOvertempMa m5 : 28|1@1+ (1,0) [0|1] "" Vector__XXX
 SG_ VCFRONT_a326_vcleftSlowTripOC m5 : 29|1@1+ (1,0) [0|1] "" Vector__XXX
 SG_ VCFRONT_a327_vcrightSlowTripOC m5 : 30|1@1+ (1,0) [0|1] "" Vector__XXX
 SG_ VCFRONT_a328_pcsSlowTripOC m5 : 31|1@1+ (1,0) [0|1] "" Vector__XXX
 SG_ VCFRONT_a329_epas3pSlowTripOC m5 : 32|1@1+ (1,0) [0|1] "" Vector__XXX
 SG_ VCFRONT_a330_epas3sSlowTripOC m5 : 33|1@1+ (1,0) [0|1] "" Vector__XXX
 SG_ VCFRONT_a331_iboosterSlowTripOC m5 : 34|1@1+ (1,0) [0|1] "" Vector__XXX
 SG_ VCFRONT_a332_espSlowTripOC m5 : 35|1@1+ (1,0) [0|1] "" Vector__XXX
 SG_ VCFRONT_a333_vbatFusedSlowTripOC m5 : 36|1@1+ (1,0) [0|1] "" Vector__XXX
 SG_ VCFRONT_a334_vcleftFastTripOCMax m5 : 37|1@1+ (1,0) [0|1] "" Vector__XXX
 SG_ VCFRONT_a335_vcrightFastTripOCMa m5 : 38|1@1+ (1,0) [0|1] "" Vector__XXX
 SG_ VCFRONT_a336_pcsFastTripOCMax m5 : 39|1@1+ (1,0) [0|1] "" Vector__XXX
 SG_ VCFRONT_a337_epas3pFastTripOCMax m5 : 40|1@1+ (1,0) [0|1] "" Vector__XXX
 SG_ VCFRONT_a338_epas3sFastTripOCMax m5 : 41|1@1+ (1,0) [0|1] "" Vector__XXX
 SG_ VCFRONT_a339_iboosterFastTripOCM m5 : 42|1@1+ (1,0) [0|1] "" Vector__XXX
 SG_ VCFRONT_a340_espFastTripOCMax m5 : 43|1@1+ (1,0) [0|1] "" Vector__XXX
 SG_ VCFRONT_a341_vbatFusedFastTripOC m5 : 44|1@1+ (1,0) [0|1] "" Vector__XXX
 SG_ VCFRONT_a342_vcleftFastTripSlope m5 : 45|1@1+ (1,0) [0|1] "" Vector__XXX
 SG_ VCFRONT_a343_vcrightFastTripSlop m5 : 46|1@1+ (1,0) [0|1] "" Vector__XXX
 SG_ VCFRONT_a344_pcsFastTripSlope m5 : 47|1@1+ (1,0) [0|1] "" Vector__XXX
 SG_ VCFRONT_a345_epas3pFastTripSlope m5 : 48|1@1+ (1,0) [0|1] "" Vector__XXX
 SG_ VCFRONT_a346_epas3sFastTripSlope m5 : 49|1@1+ (1,0) [0|1] "" Vector__XXX
 SG_ VCFRONT_a347_iboosterFastTripSlo m5 : 50|1@1+ (1,0) [0|1] "" Vector__XXX
 SG_ VCFRONT_a348_espFastTripSlope m5 : 51|1@1+ (1,0) [0|1] "" Vector__XXX
 SG_ VCFRONT_a349_vbatFusedFastTripSl m5 : 52|1@1+ (1,0) [0|1] "" Vector__XXX
 SG_ VCFRONT_a350_espValveCurrentSens m5 : 53|1@1+ (1,0) [0|1] "" Vector__XXX
 SG_ VCFRONT_a351_emergencyFrunkButto m5 : 54|1@1+ (1,0) [0|1] "" Vector__XXX
 SG_ VCFRONT_a352_audioCurrentSpikeDa m5 : 55|1@1+ (1,0) [0|1] "" Vector__XXX
 SG_ VCFRONT_a353_wiperHeaterUndercur m5 : 56|1@1+ (1,0) [0|1] "" Vector__XXX
 SG_ VCFRONT_a354_windshieldCameraHea m5 : 57|1@1+ (1,0) [0|1] "" Vector__XXX
 SG_ VCFRONT_a355_coolantSysLockout m5 : 58|1@1+ (1,0) [0|1] "" Vector__XXX
 SG_ VCFRONT_a356_refrigSysLockout m5 : 59|1@1+ (1,0) [0|1] "" Vector__XXX
 SG_ VCFRONT_a357_hornUndercurrent m5 : 60|1@1+ (1,0) [0|1] "" Vector__XXX
 SG_ VCFRONT_a358_hornOvercurrent m5 : 61|1@1+ (1,0) [0|1] "" Vector__XXX
 SG_ VCFRONT_a359_postPORExcessiveAh m5 : 62|1@1+ (1,0) [0|1] "" Vector__XXX
 SG_ VCFRONT_a360_ungracefulAccPlusEx m5 : 63|1@1+ (1,0) [0|1] "" Vector__XXX
 SG_ VCFRONT_a361_washerFluidLowMomen m6 : 4|1@1+ (1,0) [0|1] "" Vector__XXX
 SG_ VCFRONT_a362_TLVBMS_AllSocCorrec m6 : 5|1@1+ (1,0) [0|1] "" Vector__XXX
 SG_ VCFRONT_a363_TLVBMS_BleedBasedWe m6 : 6|1@1+ (1,0) [0|1] "" Vector__XXX
 SG_ VCFRONT_a364_heaterTypeEstimatio m6 : 7|1@1+ (1,0) [0|1] "" Vector__XXX
 SG_ VCFRONT_a365_burnInRoutineEntere m6 : 8|1@1+ (1,0) [0|1] "" Vector__XXX
 SG_ VCFRONT_a366_burnInRoutineExited m6 : 9|1@1+ (1,0) [0|1] "" Vector__XXX
 SG_ VCFRONT_a367_dischargeRoutineEnt m6 : 10|1@1+ (1,0) [0|1] "" Vector__XXX
 SG_ VCFRONT_a368_dischargeRoutineExi m6 : 11|1@1+ (1,0) [0|1] "" Vector__XXX
 SG_ VCFRONT_a369_reducedPowerDischar m6 : 12|1@1+ (1,0) [0|1] "" Vector__XXX
 SG_ VCFRONT_a370_noLVSupportSocTooLo m6 : 13|1@1+ (1,0) [0|1] "" Vector__XXX
 SG_ VCFRONT_a371_failureToPrechargeR m6 : 14|1@1+ (1,0) [0|1] "" Vector__XXX
 SG_ VCFRONT_a372_TLVBMS_BmbHwOverVol m6 : 15|1@1+ (1,0) [0|1] "" Vector__XXX
 SG_ VCFRONT_a373_chillerControlFlood m6 : 16|1@1+ (1,0) [0|1] "" Vector__XXX
 SG_ VCFRONT_a374_lccInletSolenoidFau m6 : 17|1@1+ (1,0) [0|1] "" Vector__XXX
 SG_ VCFRONT_a375_refVoltageOutOfSpec m6 : 18|1@1+ (1,0) [0|1] "" Vector__XXX
 SG_ VCFRONT_a376_controllerWakeupDeb m6 : 19|1@1+ (1,0) [0|1] "" Vector__XXX
 SG_ VCFRONT_a377_wiperParkFault m6 : 20|1@1+ (1,0) [0|1] "" Vector__XXX
 SG_ VCFRONT_a378_wiperECUDebug m6 : 21|1@1+ (1,0) [0|1] "" Vector__XXX
 SG_ VCFRONT_a379_shortedCellTestRunD m6 : 22|1@1+ (1,0) [0|1] "" Vector__XXX
 SG_ VCFRONT_a380_chillerExvWarning m6 : 23|1@1+ (1,0) [0|1] "" Vector__XXX
 SG_ VCFRONT_a381_evaporatorExvWarnin m6 : 24|1@1+ (1,0) [0|1] "" Vector__XXX
 SG_ VCFRONT_a382_recircExvWarning m6 : 25|1@1+ (1,0) [0|1] "" Vector__XXX
 SG_ VCFRONT_a383_lccExvWarning m6 : 26|1@1+ (1,0) [0|1] "" Vector__XXX
 SG_ VCFRONT_a384_ccLeftExvWarning m6 : 27|1@1+ (1,0) [0|1] "" Vector__XXX
 SG_ VCFRONT_a385_ccRightExvWarning m6 : 28|1@1+ (1,0) [0|1] "" Vector__XXX
 SG_ VCFRONT_a386_exvMotorWarning m6 : 29|1@1+ (1,0) [0|1] "" Vector__XXX
 SG_ VCFRONT_a387_shortedCellInstc m6 : 30|1@1+ (1,0) [0|1] "" Vector__XXX
 SG_ VCFRONT_a388_shortedCell m6 : 31|1@1+ (1,0) [0|1] "" Vector__XXX
 SG_ VCFRONT_a389_frunkInhibitingRele m6 : 32|1@1+ (1,0) [0|1] "" Vector__XXX
 SG_ VCFRONT_a390_heatPumpModeConverg m6 : 33|1@1+ (1,0) [0|1] "" Vector__XXX
 SG_ VCFRONT_a391_frunkLatchSwitchFau m6 : 34|1@1+ (1,0) [0|1] "" Vector__XXX
 SG_ VCFRONT_a392_TLVBMS_BmbHwUnderVo m6 : 35|1@1+ (1,0) [0|1] "" Vector__XXX
 SG_ VCFRONT_a393_ambientTempNetworkS m6 : 36|1@1+ (1,0) [0|1] "" Vector__XXX
 SG_ VCFRONT_a394_pressureSensorCheck m6 : 37|1@1+ (1,0) [0|1] "" Vector__XXX
 SG_ VCFRONT_a395_pressureSensorCheck m6 : 38|1@1+ (1,0) [0|1] "" Vector__XXX
 SG_ VCFRONT_a396_coolantLevelLowUser m6 : 39|1@1+ (1,0) [0|1] "" Vector__XXX
 SG_ VCFRONT_a397_temperatureSensorCh m6 : 40|1@1+ (1,0) [0|1] "" Vector__XXX
 SG_ VCFRONT_a398_tempSensorCheckInco m6 : 41|1@1+ (1,0) [0|1] "" Vector__XXX
 SG_ VCFRONT_a399_frunkNeverReportedO m6 : 42|1@1+ (1,0) [0|1] "" Vector__XXX
 SG_ VCFRONT_a400_TLVBMS_BmbVrefBad m6 : 43|1@1+ (1,0) [0|1] "" Vector__XXX
 SG_ VCFRONT_a401_deadLVMinimalAhDisc m6 : 44|1@1+ (1,0) [0|1] "" Vector__XXX
 SG_ VCFRONT_a402_LVBatteryCannotSupp m6 : 45|1@1+ (1,0) [0|1] "" Vector__XXX
 SG_ VCFRONT_a403_chargeExitHardCurre m6 : 46|1@1+ (1,0) [0|1] "" Vector__XXX
 SG_ VCFRONT_a404_resistanceEstimatio m6 : 47|1@1+ (1,0) [0|1] "" Vector__XXX
 SG_ VCFRONT_a405_dcrData1 m6 : 48|1@1+ (1,0) [0|1] "" Vector__XXX
 SG_ VCFRONT_a406_dcrData2 m6 : 49|1@1+ (1,0) [0|1] "" Vector__XXX
 SG_ VCFRONT_a407_dcrMilliOhmsAboveTh m6 : 50|1@1+ (1,0) [0|1] "" Vector__XXX
 SG_ VCFRONT_a408_standbyChargeProfil m6 : 51|1@1+ (1,0) [0|1] "" Vector__XXX
 SG_ VCFRONT_a409_invalidConfiguratio m6 : 52|1@1+ (1,0) [0|1] "" Vector__XXX
 SG_ VCFRONT_a410_LVBatteryDataCollec m6 : 53|1@1+ (1,0) [0|1] "" Vector__XXX
 SG_ VCFRONT_a411_LVBatteryDataCollec m6 : 54|1@1+ (1,0) [0|1] "" Vector__XXX
 SG_ VCFRONT_a412_dcrData3 m6 : 55|1@1+ (1,0) [0|1] "" Vector__XXX
 SG_ VCFRONT_a413_TLVBMS_BmbVrefWarni m6 : 56|1@1+ (1,0) [0|1] "" Vector__XXX
 SG_ VCFRONT_a414_prechargeLVLoadRedu m6 : 57|1@1+ (1,0) [0|1] "" Vector__XXX
 SG_ VCFRONT_a415_prechargeLVLoadRedu m6 : 58|1@1+ (1,0) [0|1] "" Vector__XXX
 SG_ VCFRONT_a416_TLVBMS_BrickOverDis m6 : 59|1@1+ (1,0) [0|1] "" Vector__XXX
 SG_ VCFRONT_a417_TLVBMS_BrickOverVol m6 : 60|1@1+ (1,0) [0|1] "" Vector__XXX
 SG_ VCFRONT_a418_TLVBMS_BrickOverVol m6 : 61|1@1+ (1,0) [0|1] "" Vector__XXX
 SG_ VCFRONT_a419_TLVBMS_BrickSocLow m6 : 62|1@1+ (1,0) [0|1] "" Vector__XXX
 SG_ VCFRONT_a420_holidayParty m6 : 63|1@1+ (1,0) [0|1] "" Vector__XXX
 SG_ VCFRONT_a421_leftHeadlampUartCon m7 : 4|1@1+ (1,0) [0|1] "" Vector__XXX
 SG_ VCFRONT_a423_TLVBMS_BrickUnderVo m7 : 6|1@1+ (1,0) [0|1] "" Vector__XXX
 SG_ VCFRONT_a424_TLVBMS_BrickUnderVo m7 : 7|1@1+ (1,0) [0|1] "" Vector__XXX
 SG_ VCFRONT_a425_TLVBMS_BusVoltageTo m7 : 8|1@1+ (1,0) [0|1] "" Vector__XXX
 SG_ VCFRONT_a426_TLVBMS_BusVoltageTo m7 : 9|1@1+ (1,0) [0|1] "" Vector__XXX
 SG_ VCFRONT_a427_TLVBMS_CacChange m7 : 10|1@1+ (1,0) [0|1] "" Vector__XXX
 SG_ VCFRONT_a428_TLVBMS_CacImbalance m7 : 11|1@1+ (1,0) [0|1] "" Vector__XXX
 SG_ VCFRONT_a429_TLVBMS_CapacityTest m7 : 12|1@1+ (1,0) [0|1] "" Vector__XXX
 SG_ VCFRONT_a430_TLVBMS_ChargeCurren m7 : 13|1@1+ (1,0) [0|1] "" Vector__XXX
 SG_ VCFRONT_a431_TLVBMS_ChargeOverCu m7 : 14|1@1+ (1,0) [0|1] "" Vector__XXX
 SG_ VCFRONT_a432_TLVBMS_ChargeRegula m7 : 15|1@1+ (1,0) [0|1] "" Vector__XXX
 SG_ VCFRONT_a433_TLVBMS_ConfigFromBm m7 : 16|1@1+ (1,0) [0|1] "" Vector__XXX
 SG_ VCFRONT_a434_TLVBMS_ConfigInitFa m7 : 17|1@1+ (1,0) [0|1] "" Vector__XXX
 SG_ VCFRONT_a435_TLVBMS_DchgCurrentL m7 : 18|1@1+ (1,0) [0|1] "" Vector__XXX
 SG_ VCFRONT_a436_TLVBMS_DischargeOve m7 : 19|1@1+ (1,0) [0|1] "" Vector__XXX
 SG_ VCFRONT_a437_TLVBMS_NvmRegistrat m7 : 20|1@1+ (1,0) [0|1] "" Vector__XXX
 SG_ VCFRONT_a438_TLVBMS_PackOverTemp m7 : 21|1@1+ (1,0) [0|1] "" Vector__XXX
 SG_ VCFRONT_a439_TLVBMS_PackOverTemp m7 : 22|1@1+ (1,0) [0|1] "" Vector__XXX
 SG_ VCFRONT_a440_TLVBMS_PackSNInvali m7 : 23|1@1+ (1,0) [0|1] "" Vector__XXX
 SG_ VCFRONT_a441_TLVBMS_ResetNeededF m7 : 24|1@1+ (1,0) [0|1] "" Vector__XXX
 SG_ VCFRONT_a442_TLVBMS_SocChange m7 : 25|1@1+ (1,0) [0|1] "" Vector__XXX
 SG_ VCFRONT_a443_TLVBMS_BmbDieOverTe m7 : 26|1@1+ (1,0) [0|1] "" Vector__XXX
 SG_ VCFRONT_a444_drv8703Fault m7 : 27|1@1+ (1,0) [0|1] "" Vector__XXX
 SG_ VCFRONT_a445_drv8703SpiFaultDBG m7 : 28|1@1+ (1,0) [0|1] "" Vector__XXX
 SG_ VCFRONT_a446_cabinHVACUnavailabl m7 : 29|1@1+ (1,0) [0|1] "" Vector__XXX
 SG_ VCFRONT_a447_cabinHVACUnavailabl m7 : 30|1@1+ (1,0) [0|1] "" Vector__XXX
 SG_ VCFRONT_a448_gtwSteeringBtnReset m7 : 31|1@1+ (1,0) [0|1] "" Vector__XXX
 SG_ VCFRONT_a449_hornSwitchStuckOn m7 : 32|1@1+ (1,0) [0|1] "" Vector__XXX
 SG_ VCFRONT_a450_hornSwitchNotPresse m7 : 33|1@1+ (1,0) [0|1] "" Vector__XXX
 SG_ VCFRONT_a451_refrigerantNotCommi m7 : 34|1@1+ (1,0) [0|1] "" Vector__XXX
 SG_ VCFRONT_a452_dischargePresSensIn m7 : 35|1@1+ (1,0) [0|1] "" Vector__XXX
 SG_ VCFRONT_a453_dischargeTempSensIn m7 : 36|1@1+ (1,0) [0|1] "" Vector__XXX
 SG_ VCFRONT_a454_suctionPresSensInte m7 : 37|1@1+ (1,0) [0|1] "" Vector__XXX
 SG_ VCFRONT_a455_suctionTempSensInte m7 : 38|1@1+ (1,0) [0|1] "" Vector__XXX
 SG_ VCFRONT_a456_liquidPresSensInter m7 : 39|1@1+ (1,0) [0|1] "" Vector__XXX
 SG_ VCFRONT_a457_liquidTempSensInter m7 : 40|1@1+ (1,0) [0|1] "" Vector__XXX
 SG_ VCFRONT_a458_grosslyLowRefrigera m7 : 41|1@1+ (1,0) [0|1] "" Vector__XXX
 SG_ VCFRONT_a459_thermalFillAndDrive m7 : 42|1@1+ (1,0) [0|1] "" Vector__XXX
 SG_ VCFRONT_a460_hardIsentropicTdFai m7 : 43|1@1+ (1,0) [0|1] "" Vector__XXX
 SG_ VCFRONT_a461_TLVBMS_SocHighAhErr m7 : 44|1@1+ (1,0) [0|1] "" Vector__XXX
 SG_ VCFRONT_a462_LVBMSFault m7 : 45|1@1+ (1,0) [0|1] "" Vector__XXX
 SG_ VCFRONT_a463_frunkSensorService m7 : 46|1@1+ (1,0) [0|1] "" Vector__XXX
 SG_ VCFRONT_a464_highFlowIndexHighSu m7 : 47|1@1+ (1,0) [0|1] "" Vector__XXX
 SG_ VCFRONT_a465_lowFlowIndexHighSub m7 : 48|1@1+ (1,0) [0|1] "" Vector__XXX
 SG_ VCFRONT_a466_highFlowIndexLowSub m7 : 49|1@1+ (1,0) [0|1] "" Vector__XXX
 SG_ VCFRONT_a467_lowPowerIndexFlagge m7 : 50|1@1+ (1,0) [0|1] "" Vector__XXX
 SG_ VCFRONT_a468_highPowerIndexFlagg m7 : 51|1@1+ (1,0) [0|1] "" Vector__XXX
 SG_ VCFRONT_a469_prvPopDetected m7 : 52|1@1+ (1,0) [0|1] "" Vector__XXX
 SG_ VCFRONT_a470_implausiblePdPlDete m7 : 53|1@1+ (1,0) [0|1] "" Vector__XXX
 SG_ VCFRONT_a471_hcm5Debug m7 : 54|1@1+ (1,0) [0|1] "" Vector__XXX
 SG_ VCFRONT_a472_leftHeadlampRangeUp m7 : 55|1@1+ (1,0) [0|1] "" Vector__XXX
 SG_ VCFRONT_a473_rightHeadlampRangeU m7 : 56|1@1+ (1,0) [0|1] "" Vector__XXX
 SG_ VCFRONT_a474_leftHeadlampInterna m7 : 57|1@1+ (1,0) [0|1] "" Vector__XXX
 SG_ VCFRONT_a475_rightHeadlampIntern m7 : 58|1@1+ (1,0) [0|1] "" Vector__XXX
 SG_ VCFRONT_a476_LVBMSMIA m7 : 59|1@1+ (1,0) [0|1] "" Vector__XXX
 SG_ VCFRONT_a477_LVBatteryUnrecovera m7 : 60|1@1+ (1,0) [0|1] "" Vector__XXX
 SG_ VCFRONT_a478_LVBMS_MOSFET_Open m7 : 61|1@1+ (1,0) [0|1] "" Vector__XXX
 SG_ VCFRONT_a479_LVBMS_ECPA_NotClose m7 : 62|1@1+ (1,0) [0|1] "" Vector__XXX
 SG_ VCFRONT_a480_vnf1048Fault m7 : 63|1@1+ (1,0) [0|1] "" Vector__XXX
 SG_ VCFRONT_a481_vnf1048SelfTestFail m8 : 4|1@1+ (1,0) [0|1] "" Vector__XXX
 SG_ VCFRONT_a482_rightHeadlampMigrat m8 : 5|1@1+ (1,0) [0|1] "" Vector__XXX
 SG_ VCFRONT_a483_leftHeadlampStepper m8 : 6|1@1+ (1,0) [0|1] "" Vector__XXX
 SG_ VCFRONT_a484_headlampLevelingRid m8 : 7|1@1+ (1,0) [0|1] "" Vector__XXX
 SG_ VCFRONT_a485_leftHeadlampMigrati m8 : 8|1@1+ (1,0) [0|1] "" Vector__XXX
 SG_ VCFRONT_a486_mcuGraphicsEFuseFau m8 : 9|1@1+ (1,0) [0|1] "" Vector__XXX
 SG_ VCFRONT_a487_leftHeadlampLastPos m8 : 10|1@1+ (1,0) [0|1] "" Vector__XXX
 SG_ VCFRONT_a488_rightHeadlampSteppe m8 : 11|1@1+ (1,0) [0|1] "" Vector__XXX
 SG_ VCFRONT_a489_ValveStuckFlagged m8 : 12|1@1+ (1,0) [0|1] "" Vector__XXX
 SG_ VCFRONT_a490_coolantPumpsNotIden m8 : 13|1@1+ (1,0) [0|1] "" Vector__XXX
 SG_ VCFRONT_a491_rightHeadlampLastPo m8 : 14|1@1+ (1,0) [0|1] "" Vector__XXX
 SG_ VCFRONT_a492_TLVBMS_SocImbalance m8 : 15|1@1+ (1,0) [0|1] "" Vector__XXX
 SG_ VCFRONT_a493_TLVBMS_SocImbalance m8 : 16|1@1+ (1,0) [0|1] "" Vector__XXX
 SG_ VCFRONT_a494_LVBatteryTempBlocki m8 : 17|1@1+ (1,0) [0|1] "" Vector__XXX
 SG_ VCFRONT_a495_LVBatteryRecoveryBl m8 : 18|1@1+ (1,0) [0|1] "" Vector__XXX
 SG_ VCFRONT_a496_LVBatteryExitDriveW m8 : 19|1@1+ (1,0) [0|1] "" Vector__XXX
 SG_ VCFRONT_a497_LVBatteryWarnDiscon m8 : 20|1@1+ (1,0) [0|1] "" Vector__XXX
 SG_ VCFRONT_a498_TLVBMS_ImpedanceTes m8 : 21|1@1+ (1,0) [0|1] "" Vector__XXX
 SG_ VCFRONT_a499_loadShedPumpFlowReq m8 : 22|1@1+ (1,0) [0|1] "" Vector__XXX
 SG_ VCFRONT_a500_eFuseASICStateMisma m8 : 23|1@1+ (1,0) [0|1] "" Vector__XXX
 SG_ VCFRONT_a501_vnf1048Configuratio m8 : 24|1@1+ (1,0) [0|1] "" Vector__XXX
 SG_ VCFRONT_a502_TLVBMS_WeakShortImp m8 : 25|1@1+ (1,0) [0|1] "" Vector__XXX
 SG_ VCFRONT_a503_TLVBMS_BrickExtende m8 : 26|1@1+ (1,0) [0|1] "" Vector__XXX
 SG_ VCFRONT_a504_airInRefrigerantDet m8 : 27|1@1+ (1,0) [0|1] "" Vector__XXX
 SG_ VCFRONT_a505_BLEFrontUnderVoltag m8 : 28|1@1+ (1,0) [0|1] "" Vector__XXX
 SG_ VCFRONT_a506_invalidRefrigerantS m8 : 29|1@1+ (1,0) [0|1] "" Vector__XXX
 SG_ VCFRONT_a507_leftHeadlampAimingF m8 : 30|1@1+ (1,0) [0|1] "" Vector__XXX
 SG_ VCFRONT_a508_TLVBMS_ImpedanceGro m8 : 31|1@1+ (1,0) [0|1] "" Vector__XXX
 SG_ VCFRONT_a509_vcrightEFuseLoadShe m8 : 32|1@1+ (1,0) [0|1] "" Vector__XXX
 SG_ VCFRONT_a510_LVBatteryRecoveryTi m8 : 33|1@1+ (1,0) [0|1] "" Vector__XXX
 SG_ VCFRONT_a511_DCDCSaturationLoadS m8 : 34|1@1+ (1,0) [0|1] "" Vector__XXX
 SG_ VCFRONT_a512_LVBMSFault_MOS_Open m8 : 35|1@1+ (1,0) [0|1] "" Vector__XXX
 SG_ VCFRONT_a513_LVBMSFault_MOS_Open m8 : 36|1@1+ (1,0) [0|1] "" Vector__XXX
 SG_ VCFRONT_a514_LVBMSFault_MOS_Open m8 : 37|1@1+ (1,0) [0|1] "" Vector__XXX
 SG_ VCFRONT_a515_LVBMSFault_MOS_Open m8 : 38|1@1+ (1,0) [0|1] "" Vector__XXX
 SG_ VCFRONT_a516_hibernationActive m8 : 39|1@1+ (1,0) [0|1] "" Vector__XXX
 SG_ VCFRONT_a517_hibernationRecovery m8 : 40|1@1+ (1,0) [0|1] "" Vector__XXX
 SG_ VCFRONT_a518_LVBMSFault_MOS_Open m8 : 41|1@1+ (1,0) [0|1] "" Vector__XXX
 SG_ VCFRONT_a519_leftHeadlampInterna m8 : 42|1@1+ (1,0) [0|1] "" Vector__XXX
 SG_ VCFRONT_a520_rightHeadlampIntern m8 : 43|1@1+ (1,0) [0|1] "" Vector__XXX
 SG_ VCFRONT_a521_vcleftEFuseLoadShed m8 : 44|1@1+ (1,0) [0|1] "" Vector__XXX
 SG_ VCFRONT_a522_hibernationActiveLo m8 : 45|1@1+ (1,0) [0|1] "" Vector__XXX
 SG_ VCFRONT_a523_eFuseThresholdsInco m8 : 46|1@1+ (1,0) [0|1] "" Vector__XXX
 SG_ VCFRONT_a524_rightHeadlampAiming m8 : 47|1@1+ (1,0) [0|1] "" Vector__XXX
 SG_ VCFRONT_a525_LVBatterySWMisconfi m8 : 48|1@1+ (1,0) [0|1] "" Vector__XXX
 SG_ VCFRONT_a526_pcbaOverTemperature m8 : 49|1@1+ (1,0) [0|1] "" Vector__XXX
 SG_ VCFRONT_a527_LVBatteryCellImbala m8 : 50|1@1+ (1,0) [0|1] "" Vector__XXX
 SG_ VCFRONT_a528_LVBatteryCommsDiscn m8 : 51|1@1+ (1,0) [0|1] "" Vector__XXX
 SG_ VCFRONT_a529_discnctdBatteryStat m8 : 52|1@1+ (1,0) [0|1] "" Vector__XXX
 SG_ VCFRONT_a530_sharpCurrentRise m8 : 53|1@1+ (1,0) [0|1] "" Vector__XXX
 SG_ VCFRONT_a531_lowPowerIndexFlagge m8 : 54|1@1+ (1,0) [0|1] "" Vector__XXX
 SG_ VCFRONT_a532_gtwMIAInDrive m8 : 55|1@1+ (1,0) [0|1] "" Vector__XXX
 SG_ VCFRONT_a533_TLVBMS_MosfetOverTe m8 : 56|1@1+ (1,0) [0|1] "" Vector__XXX
 SG_ VCFRONT_a534_chillerExvCalibInit m8 : 57|1@1+ (1,0) [0|1] "" Vector__XXX
 SG_ VCFRONT_a535_evapExvCalibInitDeb m8 : 58|1@1+ (1,0) [0|1] "" Vector__XXX
 SG_ VCFRONT_a536_recircExvCalibInitD m8 : 59|1@1+ (1,0) [0|1] "" Vector__XXX
 SG_ VCFRONT_a537_lccExvCalibInitDebu m8 : 60|1@1+ (1,0) [0|1] "" Vector__XXX
 SG_ VCFRONT_a538_cclExvCalibInitDebu m8 : 61|1@1+ (1,0) [0|1] "" Vector__XXX
 SG_ VCFRONT_a539_ccrExvCalibInitDebu m8 : 62|1@1+ (1,0) [0|1] "" Vector__XXX
 SG_ VCFRONT_a540_radiatorSteamDetect m8 : 63|1@1+ (1,0) [0|1] "" Vector__XXX
 SG_ VCFRONT_a541_LVBatteryChargeOCLe m9 : 4|1@1+ (1,0) [0|1] "" Vector__XXX
 SG_ VCFRONT_a542_refrigerantReclaim m9 : 5|1@1+ (1,0) [0|1] "" Vector__XXX
 SG_ VCFRONT_a543_compressorLowFlowDe m9 : 6|1@1+ (1,0) [0|1] "" Vector__XXX
 SG_ VCFRONT_a544_LVBatteryCommsBusTu m9 : 7|1@1+ (1,0) [0|1] "" Vector__XXX
 SG_ VCFRONT_a545_LVBatteryTypeUnknow m9 : 8|1@1+ (1,0) [0|1] "" Vector__XXX
 SG_ VCFRONT_a546_leftLowOrHighBeamLi m9 : 9|1@1+ (1,0) [0|1] "" Vector__XXX
 SG_ VCFRONT_a547_postCrashLoadShed m9 : 10|1@1+ (1,0) [0|1] "" Vector__XXX
 SG_ VCFRONT_a548_HVFaultLoadShed m9 : 11|1@1+ (1,0) [0|1] "" Vector__XXX
 SG_ VCFRONT_a549_leftHeadlampInterna m9 : 12|1@1+ (1,0) [0|1] "" Vector__XXX
 SG_ VCFRONT_a550_ambientTempDelta m9 : 13|1@1+ (1,0) [0|1] "" Vector__XXX
 SG_ VCFRONT_a551_leftHeadlampSoftSho m9 : 14|1@1+ (1,0) [0|1] "" Vector__XXX
 SG_ VCFRONT_a552_eFuseSelfTestFailur m9 : 15|1@1+ (1,0) [0|1] "" Vector__XXX
 SG_ VCFRONT_a553_rightHeadlampSoftSh m9 : 16|1@1+ (1,0) [0|1] "" Vector__XXX
 SG_ VCFRONT_a555_LVBatteryCellRebala m9 : 18|1@1+ (1,0) [0|1] "" Vector__XXX
 SG_ VCFRONT_a556_falseTriggerOfDiscn m9 : 19|1@1+ (1,0) [0|1] "" Vector__XXX
 SG_ VCFRONT_a557_rightHeadlampIntern m9 : 20|1@1+ (1,0) [0|1] "" Vector__XXX
 SG_ VCFRONT_a558_rightHeadlampAiming m9 : 21|1@1+ (1,0) [0|1] "" Vector__XXX
 SG_ VCFRONT_a559_LVBatteryLowSOC m9 : 22|1@1+ (1,0) [0|1] "" Vector__XXX
 SG_ VCFRONT_a560_compressorHighSuper m9 : 23|1@1+ (1,0) [0|1] "" Vector__XXX
 SG_ VCFRONT_a561_LVBMSEFuseOvertempe m9 : 24|1@1+ (1,0) [0|1] "" Vector__XXX
 SG_ VCFRONT_a562_LVBMSModuleOvertemp m9 : 25|1@1+ (1,0) [0|1] "" Vector__XXX
 SG_ VCFRONT_a563_chargePortDoorOpenB m9 : 26|1@1+ (1,0) [0|1] "" Vector__XXX
 SG_ VCFRONT_a564_leftHeadlampAimingD m9 : 27|1@1+ (1,0) [0|1] "" Vector__XXX
 SG_ VCFRONT_a565_userPresenceDisplay m9 : 28|1@1+ (1,0) [0|1] "" Vector__XXX
 SG_ VCFRONT_a566_leftFrontTurnLightF m9 : 29|1@1+ (1,0) [0|1] "" Vector__XXX
 SG_ VCFRONT_a567_rightFrontTurnLight m9 : 30|1@1+ (1,0) [0|1] "" Vector__XXX
 SG_ VCFRONT_a568_leftDaytimeRunningL m9 : 31|1@1+ (1,0) [0|1] "" Vector__XXX
 SG_ VCFRONT_a569_rightDaytimeRunning m9 : 32|1@1+ (1,0) [0|1] "" Vector__XXX
 SG_ VCFRONT_a570_headlampsAdaptedToL m9 : 33|1@1+ (1,0) [0|1] "" Vector__XXX
 SG_ VCFRONT_a571_headlampsAdaptedToR m9 : 34|1@1+ (1,0) [0|1] "" Vector__XXX
 SG_ VCFRONT_a572_hvacCompressorEFuse m9 : 35|1@1+ (1,0) [0|1] "" Vector__XXX
 SG_ VCFRONT_a573_radarEFuseTrip m9 : 36|1@1+ (1,0) [0|1] "" Vector__XXX
 SG_ VCFRONT_a574_frontDriveInverterE m9 : 37|1@1+ (1,0) [0|1] "" Vector__XXX
 SG_ VCFRONT_a575_frontOilPumpEFuseTr m9 : 38|1@1+ (1,0) [0|1] "" Vector__XXX
 SG_ VCFRONT_a576_mcuLogicEFuseTrip m9 : 39|1@1+ (1,0) [0|1] "" Vector__XXX
 SG_ VCFRONT_a577_tasEFuseTrip m9 : 40|1@1+ (1,0) [0|1] "" Vector__XXX
 SG_ VCFRONT_a578_vbatFusedLowCurrent m9 : 41|1@1+ (1,0) [0|1] "" Vector__XXX
 SG_ VCFRONT_a579_leftHeadlightEFuseT m9 : 42|1@1+ (1,0) [0|1] "" Vector__XXX
 SG_ VCFRONT_a580_rightHeadlightEFuse m9 : 43|1@1+ (1,0) [0|1] "" Vector__XXX
 SG_ VCFRONT_a581_windshieldWiperEFus m9 : 44|1@1+ (1,0) [0|1] "" Vector__XXX
 SG_ VCFRONT_a582_goodForPCSPowerCycl m9 : 45|1@1+ (1,0) [0|1] "" Vector__XXX
 SG_ VCFRONT_a583_frunkSwitchGroupDis m9 : 46|1@1+ (1,0) [0|1] "" Vector__XXX
 SG_ VCFRONT_a584_frunkSwitchGroupDeb m9 : 47|1@1+ (1,0) [0|1] "" Vector__XXX
 SG_ VCFRONT_a585_bothHeadlampsIntern m9 : 48|1@1+ (1,0) [0|1] "" Vector__XXX
 SG_ VCFRONT_a586_rightLowOrHighBeamL m9 : 49|1@1+ (1,0) [0|1] "" Vector__XXX
 SG_ VCFRONT_a587_externalLVPowerSupp m9 : 50|1@1+ (1,0) [0|1] "" Vector__XXX
 SG_ VCFRONT_a588_vcleftPwrRationalit m9 : 51|1@1+ (1,0) [0|1] "" Vector__XXX
 SG_ VCFRONT_a589_vcleftFastBlowDetec m9 : 52|1@1+ (1,0) [0|1] "" Vector__XXX
 SG_ VCFRONT_a590_vcrightPwrRationali m9 : 53|1@1+ (1,0) [0|1] "" Vector__XXX
 SG_ VCFRONT_a591_vcrightFastBlowDete m9 : 54|1@1+ (1,0) [0|1] "" Vector__XXX
 SG_ VCFRONT_a592_vcleftCurvePowerCut m9 : 55|1@1+ (1,0) [0|1] "" Vector__XXX
 SG_ VCFRONT_a593_vcleftFastBlowPower m9 : 56|1@1+ (1,0) [0|1] "" Vector__XXX
 SG_ VCFRONT_a594_virtualPitchConvers m9 : 57|1@1+ (1,0) [0|1] "" Vector__XXX
 SG_ VCFRONT_a595_voltageSensorMismat m9 : 58|1@1+ (1,0) [0|1] "" Vector__XXX
 SG_ VCFRONT_a596_vcrightCurvePowerCu m9 : 59|1@1+ (1,0) [0|1] "" Vector__XXX
 SG_ VCFRONT_a597_vcrightFastBlowPowe m9 : 60|1@1+ (1,0) [0|1] "" Vector__XXX
 SG_ VCFRONT_a598_eFuseSelfTestFailur m9 : 61|1@1+ (1,0) [0|1] "" Vector__XXX
 SG_ VCFRONT_a599_LVBatteryTypeUnsupp m9 : 62|1@1+ (1,0) [0|1] "" Vector__XXX
 SG_ VCFRONT_a600_currentSensorMismat m9 : 63|1@1+ (1,0) [0|1] "" Vector__XXX
 SG_ VCFRONT_a601_autopilotAirPurgeLi m10 : 4|1@1+ (1,0) [0|1] "" Vector__XXX
 SG_ VCFRONT_a602_unknownTurnIndicato m10 : 5|1@1+ (1,0) [0|1] "" Vector__XXX
 SG_ VCFRONT_a603_unexpectedTurnIndic m10 : 6|1@1+ (1,0) [0|1] "" Vector__XXX
 SG_ VCFRONT_a604_turnIndicatorConfig m10 : 7|1@1+ (1,0) [0|1] "" Vector__XXX
 SG_ VCFRONT_a605_sleepBypassPowerOff m10 : 8|1@1+ (1,0) [0|1] "" Vector__XXX
 SG_ VCFRONT_a606_chillerBattHeatingE m10 : 9|1@1+ (1,0) [0|1] "" Vector__XXX
 SG_ VCFRONT_a607_sleepPowerDebug m10 : 10|1@1+ (1,0) [0|1] "" Vector__XXX
 SG_ VCFRONT_a608_TLVBMS_BleedFetFail m10 : 11|1@1+ (1,0) [0|1] "" Vector__XXX
 SG_ VCFRONT_a609_autopilotDriveNotAu m10 : 12|1@1+ (1,0) [0|1] "" Vector__XXX
 SG_ VCFRONT_a610_frunkOpenFailureMet m10 : 13|1@1+ (1,0) [0|1] "" Vector__XXX
 SG_ VCFRONT_a611_poorRadiatorHeatRej m10 : 14|1@1+ (1,0) [0|1] "" Vector__XXX
 SG_ VCFRONT_a612_LVUnhealthyLoadShed m10 : 15|1@1+ (1,0) [0|1] "" Vector__XXX
 SG_ VCFRONT_a613_selfTestsBlockingDr m10 : 16|1@1+ (1,0) [0|1] "" Vector__XXX
 SG_ VCFRONT_a614_coolantSysDriverles m10 : 17|1@1+ (1,0) [0|1] "" Vector__XXX
 SG_ VCFRONT_a615_TLVBMS_BatteryHeate m10 : 18|1@1+ (1,0) [0|1] "" Vector__XXX
 SG_ VCFRONT_a616_VCSEAT2L_MIA m10 : 19|1@1+ (1,0) [0|1] "" Vector__XXX
 SG_ VCFRONT_a617_VCSEAT2R_MIA m10 : 20|1@1+ (1,0) [0|1] "" Vector__XXX
 SG_ VCFRONT_a618_cabinCoolingCapacit m10 : 21|1@1+ (1,0) [0|1] "" Vector__XXX
 SG_ VCFRONT_a619_frunkSwitchReleaseT m10 : 22|1@1+ (1,0) [0|1] "" Vector__XXX
 SG_ VCFRONT_a620_pumpAirLock m10 : 23|1@1+ (1,0) [0|1] "" Vector__XXX
 SG_ VCFRONT_a621_coolantAirPurgeInco m10 : 24|1@1+ (1,0) [0|1] "" Vector__XXX
 SG_ VCFRONT_a622_pumpDetectsLowCoola m10 : 25|1@1+ (1,0) [0|1] "" Vector__XXX
 SG_ VCFRONT_a623_LVUnhealthy m10 : 26|1@1+ (1,0) [0|1] "" Vector__XXX
 SG_ VCFRONT_a624_rightHeadlampIntern m10 : 27|1@1+ (1,0) [0|1] "" Vector__XXX
 SG_ VCFRONT_a625_leftHeadlampInterna m10 : 28|1@1+ (1,0) [0|1] "" Vector__XXX
 SG_ VCFRONT_a626_LVBatteryResistance m10 : 29|1@1+ (1,0) [0|1] "" Vector__XXX
 SG_ VCFRONT_a627_LVBatteryUnrecovera m10 : 30|1@1+ (1,0) [0|1] "" Vector__XXX
 SG_ VCFRONT_a628_TLVBMS_BmbThermisto m10 : 31|1@1+ (1,0) [0|1] "" Vector__XXX
 SG_ VCFRONT_a629_TLVBMS_PackTemperat m10 : 32|1@1+ (1,0) [0|1] "" Vector__XXX
 SG_ VCFRONT_a630_leftHeadlampFactory m10 : 33|1@1+ (1,0) [0|1] "" Vector__XXX
 SG_ VCFRONT_a631_rightHeadlampFactor m10 : 34|1@1+ (1,0) [0|1] "" Vector__XXX
 SG_ VCFRONT_a634_indeterminateSwitch m10 : 37|1@1+ (1,0) [0|1] "" Vector__XXX
 SG_ VCFRONT_a635_rtosSleepFailed m10 : 38|1@1+ (1,0) [0|1] "" Vector__XXX
 SG_ VCFRONT_d636_ptCoolantPumpDetect m10 : 39|1@1+ (1,0) [0|1] "" Vector__XXX
 SG_ VCFRONT_d637_battCoolantPumpDete m10 : 40|1@1+ (1,0) [0|1] "" Vector__XXX
 SG_ VCFRONT_d638_ptCoolantTempSensor m10 : 41|1@1+ (1,0) [0|1] "" Vector__XXX
 SG_ VCFRONT_d639_batteryCoolantTempS m10 : 42|1@1+ (1,0) [0|1] "" Vector__XXX
 SG_ VCFRONT_d640_firmwareVersionMism m10 : 43|1@1+ (1,0) [0|1] "" Vector__XXX
 SG_ VCFRONT_d641_ptCoolantPumpCircui m10 : 44|1@1+ (1,0) [0|1] "" Vector__XXX
 SG_ VCFRONT_d642_batteryCoolantPumpC m10 : 45|1@1+ (1,0) [0|1] "" Vector__XXX
 SG_ VCFRONT_a643_rightHeadlampUartCo m10 : 46|1@1+ (1,0) [0|1] "" Vector__XXX
 SG_ VCFRONT_a644_washPumpHealthCalcu m10 : 47|1@1+ (1,0) [0|1] "" Vector__XXX
 SG_ VCFRONT_a645_washPumpHealthCalcu m10 : 48|1@1+ (1,0) [0|1] "" Vector__XXX
 SG_ VCFRONT_a646_washPumpHealthCalcu m10 : 49|1@1+ (1,0) [0|1] "" Vector__XXX
 SG_ VCFRONT_d647_louverCommLost m10 : 50|1@1+ (1,0) [0|1] "" Vector__XXX
 SG_ VCFRONT_d648_louverBlocked m10 : 51|1@1+ (1,0) [0|1] "" Vector__XXX
 SG_ VCFRONT_a649_persistAccPortPower m10 : 52|1@1+ (1,0) [0|1] "" Vector__XXX
 SG_ VCFRONT_d650_lowCoolantLevel m10 : 53|1@1+ (1,0) [0|1] "" Vector__XXX
 SG_ VCFRONT_d651_ptCoolantPumpStall m10 : 54|1@1+ (1,0) [0|1] "" Vector__XXX
 SG_ VCFRONT_d652_ptCoolantPumpCircui m10 : 55|1@1+ (1,0) [0|1] "" Vector__XXX
 SG_ VCFRONT_d653_ptCoolantPumpCommLo m10 : 56|1@1+ (1,0) [0|1] "" Vector__XXX
 SG_ VCFRONT_d654_batteryCoolantPumpS m10 : 57|1@1+ (1,0) [0|1] "" Vector__XXX
 SG_ VCFRONT_d655_batteryCoolantPumpC m10 : 58|1@1+ (1,0) [0|1] "" Vector__XXX
 SG_ VCFRONT_d656_batteryCoolantPumpC m10 : 59|1@1+ (1,0) [0|1] "" Vector__XXX
 SG_ VCFRONT_d657_radiatorFanOperatio m10 : 60|1@1+ (1,0) [0|1] "" Vector__XXX
 SG_ VCFRONT_d658_radiatorFanCircuitI m10 : 61|1@1+ (1,0) [0|1] "" Vector__XXX
 SG_ VCFRONT_d659_radiatorFanCommLost m10 : 62|1@1+ (1,0) [0|1] "" Vector__XXX
 SG_ VCFRONT_d660_coolantValveCircuit m10 : 63|1@1+ (1,0) [0|1] "" Vector__XXX
 SG_ VCFRONT_a661_mculessLeftHeadlamp m11 : 4|1@1+ (1,0) [0|1] "" Vector__XXX
 SG_ VCFRONT_a662_mculessRightHeadlam m11 : 5|1@1+ (1,0) [0|1] "" Vector__XXX
 SG_ VCFRONT_a663_leftHeadlampUartWat m11 : 6|1@1+ (1,0) [0|1] "" Vector__XXX
 SG_ VCFRONT_a664_rightHeadlampUartWa m11 : 7|1@1+ (1,0) [0|1] "" Vector__XXX
 SG_ VCFRONT_a665_leftHeadlampRetryIn m11 : 8|1@1+ (1,0) [0|1] "" Vector__XXX
 SG_ VCFRONT_a666_rightHeadlampRetryI m11 : 9|1@1+ (1,0) [0|1] "" Vector__XXX
 SG_ VCFRONT_a667_leftHeadlampRegionO m11 : 10|1@1+ (1,0) [0|1] "" Vector__XXX
 SG_ VCFRONT_a668_rightHeadlampRegion m11 : 11|1@1+ (1,0) [0|1] "" Vector__XXX
 SG_ VCFRONT_a669_thermalHVPowerBudge m11 : 12|1@1+ (1,0) [0|1] "" Vector__XXX
 SG_ VCFRONT_a670_TLVBMS_EfuseStateIr m11 : 13|1@1+ (1,0) [0|1] "" Vector__XXX
 SG_ VCFRONT_a671_powerConsumptionInf m11 : 14|1@1+ (1,0) [0|1] "" Vector__XXX
 SG_ VCFRONT_a672_LVBatteryVitals m11 : 15|1@1+ (1,0) [0|1] "" Vector__XXX
 SG_ VCFRONT_d674_portExpanderService m11 : 17|1@1+ (1,0) [0|1] "" Vector__XXX
 SG_ VCFRONT_a675_doorWakeToOpenDBG m11 : 18|1@1+ (1,0) [0|1] "" Vector__XXX
 SG_ VCFRONT_a697_leftHeadlampNotAime m11 : 40|1@1+ (1,0) [0|1] "" Vector__XXX
 SG_ VCFRONT_a698_rightHeadlampNotAim m11 : 41|1@1+ (1,0) [0|1] "" Vector__XXX
 SG_ VCFRONT_a702_dynamicHeadlightLev m11 : 45|1@1+ (1,0) [0|1] "" Vector__XXX

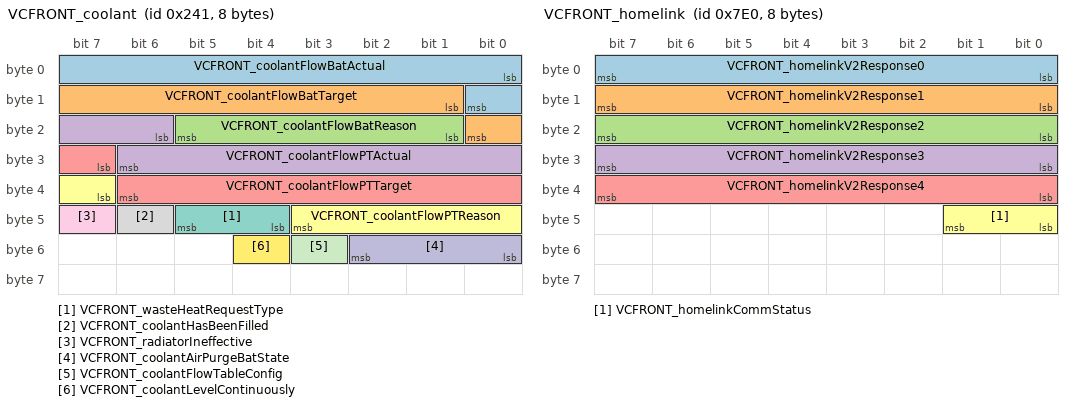
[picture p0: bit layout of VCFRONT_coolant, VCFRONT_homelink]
BO_ 577 VCFRONT_coolant: 8 VCFRONT
 SG_ VCFRONT_coolantFlowBatActual : 0|9@1+ (0.1,0) [0|40] "LPM" Vector__XXX
 SG_ VCFRONT_coolantFlowBatTarget : 9|8@1+ (0.2,0) [0|40] "LPM" Vector__XXX
 SG_ VCFRONT_coolantFlowBatReason : 17|5@1+ (1,0) [0|31] "" Vector__XXX
 SG_ VCFRONT_coolantFlowPTActual : 22|9@1+ (0.1,0) [0|40] "LPM" Vector__XXX
 SG_ VCFRONT_coolantFlowPTTarget : 31|8@1+ (0.2,0) [0|40] "LPM" Vector__XXX
 SG_ VCFRONT_coolantFlowPTReason : 39|5@1+ (1,0) [0|31] "" Vector__XXX
 SG_ VCFRONT_wasteHeatRequestType : 44|2@1+ (1,0) [0|3] "" Vector__XXX
 SG_ VCFRONT_coolantHasBeenFilled : 46|1@1+ (1,0) [0|1] "" Vector__XXX
 SG_ VCFRONT_radiatorIneffective : 47|1@1+ (1,0) [0|1] "" Vector__XXX
 SG_ VCFRONT_coolantAirPurgeBatState : 48|3@1+ (1,0) [0|7] "" Vector__XXX
 SG_ VCFRONT_coolantFlowTableConfig : 51|1@1+ (1,0) [0|1] "" Vector__XXX
 SG_ VCFRONT_coolantLevelContinuously : 52|1@1+ (1,0) [0|1] "" Vector__XXX

BO_ 753 VCFRONT_eFuseDebugStatus: 8 VCFRONT
 SG_ VCFRONT_eFuseDebugStatusIndex M : 0|5@1+ (1,0) [0|31] "" Vector__XXX
 SG_ VCFRONT_leftControllerState m1 : 8|2@1+ (1,0) [0|3] "" Vector__XXX
 SG_ VCFRONT_leftControllerFault m1 : 10|1@1+ (1,0) [0|1] "" Vector__XXX
 SG_ VCFRONT_vcleftSelfTestResult m1 : 11|4@1+ (1,0) [0|15] "" Vector__XXX
 SG_ VCFRONT_leftControllerTemp m1 : 15|11@1+ (0.125,-40) [-40|150] "degC" Vector__XXX
 SG_ VCFRONT_leftControllerEFuseVNFSt m1 : 26|3@1+ (1,0) [0|7] "" Vector__XXX
 SG_ VCFRONT_leftControllerEFuseOutpu m1 : 29|1@1+ (1,0) [0|1] "" Vector__XXX
 SG_ VCFRONT_leftControllerEFuse_0002 m1 : 30|1@1+ (1,0) [0|1] "" Vector__XXX
 SG_ VCFRONT_leftControllerVoltage m1 : 31|14@1+ (0.1,0) [0|1638.3] "V" Vector__XXX
 SG_ VCFRONT_leftControllerEFuseBypas m1 : 45|1@1+ (1,0) [0|1] "" Vector__XXX
 SG_ VCFRONT_leftControllerEFuse_0001 m1 : 46|1@1+ (1,0) [0|1] "" Vector__XXX
 SG_ VCFRONT_leftControllerCurrent m1 : 47|14@1+ (0.1,0) [0|1638.3] "A" Vector__XXX
 SG_ VCFRONT_leftControllerEFuseVNFSe m1 : 61|2@1+ (1,0) [0|3] "" Vector__XXX
 SG_ VCFRONT_PCSState m2 : 8|2@1+ (1,0) [0|3] "" Vector__XXX
 SG_ VCFRONT_PCSFault m2 : 10|1@1+ (1,0) [0|1] "" Vector__XXX
 SG_ VCFRONT_pcsSelfTestResult m2 : 11|4@1+ (1,0) [0|15] "" Vector__XXX
 SG_ VCFRONT_PCSTemp m2 : 15|11@1+ (0.125,-40) [-40|150] "degC" Vector__XXX
 SG_ VCFRONT_PCSEFuseVNFState m2 : 26|3@1+ (1,0) [0|7] "" Vector__XXX
 SG_ VCFRONT_PCSEFuseOutput m2 : 29|1@1+ (1,0) [0|1] "" Vector__XXX
 SG_ VCFRONT_PCSEFuseOutputDesired m2 : 30|1@1+ (1,0) [0|1] "" Vector__XXX
 SG_ VCFRONT_PCSVoltage m2 : 31|14@1+ (0.1,0) [0|1638.3] "V" Vector__XXX
 SG_ VCFRONT_PCSEFuseBypass m2 : 45|1@1+ (1,0) [0|1] "" Vector__XXX
 SG_ VCFRONT_PCSEFuseBypassDesired m2 : 46|1@1+ (1,0) [0|1] "" Vector__XXX
 SG_ VCFRONT_PCSEFuseVNFSelfTestStatu m2 : 61|2@1+ (1,0) [0|3] "" Vector__XXX
 SG_ VCFRONT_iBoosterState m3 : 8|2@1+ (1,0) [0|3] "" Vector__XXX
 SG_ VCFRONT_iBoosterFault m3 : 10|1@1+ (1,0) [0|1] "" Vector__XXX
 SG_ VCFRONT_iBoosterSelfTestResult m3 : 11|4@1+ (1,0) [0|15] "" Vector__XXX
 SG_ VCFRONT_iBoosterTemp m3 : 15|11@1+ (0.125,-40) [-40|150] "degC" Vector__XXX
 SG_ VCFRONT_iBoosterEFuseVNFState m3 : 26|3@1+ (1,0) [0|7] "" Vector__XXX
 SG_ VCFRONT_iBoosterEFuseOutput m3 : 29|1@1+ (1,0) [0|1] "" Vector__XXX
 SG_ VCFRONT_iBoosterEFuseOutputDesir m3 : 30|1@1+ (1,0) [0|1] "" Vector__XXX
 SG_ VCFRONT_iBoosterVoltage m3 : 31|9@1+ (0.1,0) [0|51.1] "V" Vector__XXX
 SG_ VCFRONT_iBoosterHardshortThresho m3 : 40|4@1+ (1,0) [0|15] "" Vector__XXX
 SG_ VCFRONT_iBoosterEFuseBypass m3 : 45|1@1+ (1,0) [0|1] "" Vector__XXX
 SG_ VCFRONT_iBoosterEFuseBypassDesir m3 : 46|1@1+ (1,0) [0|1] "" Vector__XXX
 SG_ VCFRONT_iBoosterCurrent m3 : 47|14@1+ (0.1,0) [0|1638.3] "A" Vector__XXX
 SG_ VCFRONT_iBoosterEFuseVNFSelfTest m3 : 61|2@1+ (1,0) [0|3] "" Vector__XXX
 SG_ VCFRONT_EPAS3PState m4 : 8|2@1+ (1,0) [0|3] "" Vector__XXX
 SG_ VCFRONT_EPAS3PFault m4 : 10|1@1+ (1,0) [0|1] "" Vector__XXX
 SG_ VCFRONT_EPAS3PSelfTestResult m4 : 11|4@1+ (1,0) [0|15] "" Vector__XXX
 SG_ VCFRONT_EPAS3PTemp m4 : 15|11@1+ (0.125,-40) [-40|150] "degC" Vector__XXX
 SG_ VCFRONT_EPAS3PEFuseVNFState m4 : 26|3@1+ (1,0) [0|7] "" Vector__XXX
 SG_ VCFRONT_EPAS3PEFuseOutput m4 : 29|1@1+ (1,0) [0|1] "" Vector__XXX
 SG_ VCFRONT_EPAS3PEFuseOutputDesired m4 : 30|1@1+ (1,0) [0|1] "" Vector__XXX
 SG_ VCFRONT_EPAS3PVoltage m4 : 31|9@1+ (0.1,0) [0|51.1] "V" Vector__XXX
 SG_ VCFRONT_EPAS3PEFuseHardshortThre m4 : 40|4@1+ (1,0) [0|15] "" Vector__XXX
 SG_ VCFRONT_EPAS3PEFuseBypass m4 : 45|1@1+ (1,0) [0|1] "" Vector__XXX
 SG_ VCFRONT_EPAS3PEFuseBypassDesired m4 : 46|1@1+ (1,0) [0|1] "" Vector__XXX
 SG_ VCFRONT_EPAS3PCurrent m4 : 47|14@1+ (0.1,0) [0|1638.3] "A" Vector__XXX
 SG_ VCFRONT_EPAS3PEFuseVNFSelfTestSt m4 : 61|2@1+ (1,0) [0|3] "" Vector__XXX
 SG_ VCFRONT_EPAS3SState m5 : 8|2@1+ (1,0) [0|3] "" Vector__XXX
 SG_ VCFRONT_EPAS3SFault m5 : 10|1@1+ (1,0) [0|1] "" Vector__XXX
 SG_ VCFRONT_EPAS3SSelfTestResult m5 : 11|4@1+ (1,0) [0|15] "" Vector__XXX
 SG_ VCFRONT_EPAS3STemp m5 : 15|11@1+ (0.125,-40) [-40|150] "degC" Vector__XXX
 SG_ VCFRONT_EPAS3SEFuseVNFState m5 : 26|3@1+ (1,0) [0|7] "" Vector__XXX
 SG_ VCFRONT_EPAS3SEFuseOutput m5 : 29|1@1+ (1,0) [0|1] "" Vector__XXX
 SG_ VCFRONT_EPAS3SEFuseOutputDesired m5 : 30|1@1+ (1,0) [0|1] "" Vector__XXX
 SG_ VCFRONT_EPAS3SVoltage m5 : 31|14@1+ (0.1,0) [0|1638.3] "V" Vector__XXX
 SG_ VCFRONT_EPAS3SEFuseBypass m5 : 45|1@1+ (1,0) [0|1] "" Vector__XXX
 SG_ VCFRONT_EPAS3SEFuseBypassDesired m5 : 46|1@1+ (1,0) [0|1] "" Vector__XXX
 SG_ VCFRONT_EPAS3SCurrent m5 : 47|14@1+ (0.1,0) [0|1638.3] "A" Vector__XXX
 SG_ VCFRONT_EPAS3SEFuseVNFSelfTestSt m5 : 61|2@1+ (1,0) [0|3] "" Vector__XXX
 SG_ VCFRONT_ESPMotorState m6 : 8|2@1+ (1,0) [0|3] "" Vector__XXX
 SG_ VCFRONT_ESPMotorFault m6 : 10|1@1+ (1,0) [0|1] "" Vector__XXX
 SG_ VCFRONT_ESPMotorSelfTestResult m6 : 11|4@1+ (1,0) [0|15] "" Vector__XXX
 SG_ VCFRONT_ESPMotorTemp m6 : 15|11@1+ (0.125,-40) [-40|150] "degC" Vector__XXX
 SG_ VCFRONT_ESPMotorEFuseVNFState m6 : 26|3@1+ (1,0) [0|7] "" Vector__XXX
 SG_ VCFRONT_ESPMotorEFuseOutput m6 : 29|1@1+ (1,0) [0|1] "" Vector__XXX
 SG_ VCFRONT_ESPMotorEFuseOutputDesir m6 : 30|1@1+ (1,0) [0|1] "" Vector__XXX
 SG_ VCFRONT_ESPMotorVoltage m6 : 31|14@1+ (0.1,0) [0|1638.3] "V" Vector__XXX
 SG_ VCFRONT_ESPMotorEFuseBypass m6 : 45|1@1+ (1,0) [0|1] "" Vector__XXX
 SG_ VCFRONT_ESPMotorEFuseBypassDesir m6 : 46|1@1+ (1,0) [0|1] "" Vector__XXX
 SG_ VCFRONT_ESPMotorCurrent m6 : 47|14@1+ (0.1,0) [0|1638.3] "A" Vector__XXX
 SG_ VCFRONT_ESPMotorEFuseVNFSelfTest m6 : 61|2@1+ (1,0) [0|3] "" Vector__XXX
 SG_ VCFRONT_ESPValveState m7 : 8|2@1+ (1,0) [0|3] "" Vector__XXX
 SG_ VCFRONT_ESPValveFault m7 : 10|1@1+ (1,0) [0|1] "" Vector__XXX
 SG_ VCFRONT_ESPValveTemp m7 : 12|11@1+ (0.125,-40) [-40|150] "degC" Vector__XXX
 SG_ VCFRONT_ESPValveVoltage m7 : 28|16@1+ (0.1,0) [0|6553.5] "V" Vector__XXX
 SG_ VCFRONT_ESPValveCurrent m7 : 44|16@1+ (0.01,0) [0|655.35] "A" Vector__XXX
 SG_ VCFRONT_autopilot2State m9 : 8|2@1+ (1,0) [0|3] "" Vector__XXX
 SG_ VCFRONT_autopilot2Fault m9 : 10|1@1+ (1,0) [0|1] "" Vector__XXX
 SG_ VCFRONT_autopilot2Temp m9 : 11|11@1+ (0.125,-40) [-40|150] "degC" Vector__XXX
 SG_ VCFRONT_autopilot2Voltage m9 : 27|16@1+ (0.1,0) [0|6553.5] "V" Vector__XXX
 SG_ VCFRONT_autopilot2Current m9 : 43|10@1+ (0.044,0) [0|45.012] "A" Vector__XXX
 SG_ VCFRONT_sleepBypassState m10 : 8|1@1+ (1,0) [0|1] "" Vector__XXX
 SG_ VCFRONT_sleepBypassFault m10 : 9|1@1+ (1,0) [0|1] "" Vector__XXX
 SG_ VCFRONT_sleepBypassVoltage m10 : 10|16@1+ (0.1,0) [0|6553.5] "V" Vector__XXX
 SG_ VCFRONT_sleepBypassCurrent m10 : 26|16@1+ (0.1,0) [0|6553.5] "A" Vector__XXX
 SG_ VCFRONT_vbatFusedHighState m13 : 8|1@1+ (1,0) [0|1] "" Vector__XXX
 SG_ VCFRONT_vbatFusedHighFault m13 : 9|1@1+ (1,0) [0|1] "" Vector__XXX
 SG_ VCFRONT_vbatFusedSelfTestResult m13 : 10|4@1+ (1,0) [0|15] "" Vector__XXX
 SG_ VCFRONT_vbatFusedHighTemp m13 : 14|11@1+ (0.125,-40) [-40|150] "degC" Vector__XXX
 SG_ VCFRONT_vbatFusedHighVoltage m13 : 30|16@1+ (0.1,0) [0|6553.5] "V" Vector__XXX
 SG_ VCFRONT_vbatFusedHighCurrent m13 : 46|16@1+ (0.1,0) [0|6553.5] "A" Vector__XXX
 SG_ VCFRONT_chargedIBSAmpHours m17 : 8|16@1+ (1,0) [0|65535] "Ah" Vector__XXX
 SG_ VCFRONT_dischargedIBSAmpHours m17 : 24|16@1+ (1,0) [0|65535] "Ah" Vector__XXX
 SG_ VCFRONT_IBSUnfilteredTemperature m17 : 40|16@1- (0.01,0) [-327.67|327.67] "degC" Vector__XXX

BO_ 2016 VCFRONT_homelink: 8 VCFRONT
 SG_ VCFRONT_homelinkV2Response0 : 0|8@1+ (1,0) [0|255] "" Vector__XXX
 SG_ VCFRONT_homelinkV2Response1 : 8|8@1+ (1,0) [0|255] "" Vector__XXX
 SG_ VCFRONT_homelinkV2Response2 : 16|8@1+ (1,0) [0|255] "" Vector__XXX
 SG_ VCFRONT_homelinkV2Response3 : 24|8@1+ (1,0) [0|255] "" Vector__XXX
 SG_ VCFRONT_homelinkV2Response4 : 32|8@1+ (1,0) [0|255] "" Vector__XXX
 SG_ VCFRONT_homelinkCommStatus : 40|2@1+ (1,0) [0|3] "" Vector__XXX

BO_ 769 VCFRONT_info: 8 VCFRONT
 SG_ VCFRONT_infoIndex M : 0|8@1+ (1,0) [0|255] "" Vector__XXX
 SG_ VCFRONT_infoBuildType m10 : 8|3@1+ (1,0) [0|7] "" Vector__XXX
 SG_ VCFRONT_infoBuildConfigId m10 : 16|16@1+ (1,0) [0|65535] "" Vector__XXX
 SG_ VCFRONT_infoHardwareId m10 : 32|16@1+ (1,0) [0|65535] "" Vector__XXX
 SG_ VCFRONT_infoComponentId m10 : 48|16@1+ (1,0) [0|65535] "" Vector__XXX
 SG_ VCFRONT_infoPcbaId m11 : 8|8@1+ (1,0) [0|255] "" Vector__XXX
 SG_ VCFRONT_infoAssemblyId m11 : 16|8@1+ (1,0) [0|255] "" Vector__XXX
 SG_ VCFRONT_infoUsageId m11 : 24|16@1+ (1,0) [0|65535] "" Vector__XXX
 SG_ VCFRONT_infoSubUsageId m11 : 40|16@1+ (1,0) [0|65535] "" Vector__XXX
 SG_ VCFRONT_infoAppCrc m13 : 8|32@1+ (1,0) [0|4294967295] "" Vector__XXX
 SG_ VC_infoHCMLAppCRC m16 : 32|32@1+ (1,0) [0|4294967295] "" Vector__XXX
 SG_ VCFRONT_infoAppGitHash m17 : 8|56@1+ (1,0) [0|7.20575940379e+16] "" Vector__XXX
 SG_ VCFRONT_infoBootGitHash m18 : 8|56@1+ (1,0) [0|7.20575940379e+16] "" Vector__XXX
 SG_ VCFRONT_infoPlatformType m19 : 8|8@1+ (1,0) [0|255] "" Vector__XXX
 SG_ VCFRONT_infoBootUdsProtoVersion m20 : 8|16@1+ (1,0) [0|65535] "" Vector__XXX
 SG_ VCFRONT_infoBootCrc m20 : 24|32@1+ (1,0) [0|4294967295] "" Vector__XXX
 SG_ VC_infoHCMRAppCRC m23 : 32|32@1+ (1,0) [0|4294967295] "" Vector__XXX
 SG_ VC_infoWiperAppCRC m31 : 32|32@1+ (1,0) [0|4294967295] "" Vector__XXX

BO_ 1014 VCFRONT_lightStatus: 8 VCFRONT
 SG_ VCFRONT_lowBeamLeftStatus : 0|2@1+ (1,0) [0|3] "" Vector__XXX
 SG_ VCFRONT_lowBeamRightStatus : 2|2@1+ (1,0) [0|3] "" Vector__XXX
 SG_ VCFRONT_highBeamLeftStatus : 4|2@1+ (1,0) [0|3] "" Vector__XXX
 SG_ VCFRONT_highBeamRightStatus : 6|2@1+ (1,0) [0|3] "" Vector__XXX
 SG_ VCFRONT_DRLLeftStatus : 8|2@1+ (1,0) [0|3] "" Vector__XXX
 SG_ VCFRONT_DRLRightStatus : 10|2@1+ (1,0) [0|3] "" Vector__XXX
 SG_ VCFRONT_fogLeftStatus : 12|2@1+ (1,0) [0|3] "" Vector__XXX
 SG_ VCFRONT_fogRightStatus : 14|2@1+ (1,0) [0|3] "" Vector__XXX
 SG_ VCFRONT_sideMarkersStatus : 16|2@1+ (1,0) [0|3] "" Vector__XXX
 SG_ VCFRONT_sideRepeaterLeftStatus : 18|2@1+ (1,0) [0|3] "" Vector__XXX
 SG_ VCFRONT_sideRepeaterRightStatus : 20|2@1+ (1,0) [0|3] "" Vector__XXX
 SG_ VCFRONT_turnSignalLeftStatus : 22|2@1+ (1,0) [0|3] "" Vector__XXX
 SG_ VCFRONT_turnSignalRightStatus : 24|2@1+ (1,0) [0|3] "" Vector__XXX
 SG_ VCFRONT_parkLeftStatus : 26|2@1+ (1,0) [0|3] "" Vector__XXX
 SG_ VCFRONT_parkRightStatus : 28|2@1+ (1,0) [0|3] "" Vector__XXX
 SG_ VCFRONT_lowBeamLeftReadyForAimin : 30|1@1+ (1,0) [0|1] "" Vector__XXX
 SG_ VCFRONT_lowBeamRightReadyForAimi : 31|1@1+ (1,0) [0|1] "" Vector__XXX
 SG_ VCFRONT_lowBeamsOnForDRL : 32|1@1+ (1,0) [0|1] "" Vector__XXX
 SG_ VC_rightHeadlampHealth : 33|3@1+ (1,0) [0|7] "" Vector__XXX
 SG_ VC_leftHeadlampHealth : 36|3@1+ (1,0) [0|7] "" Vector__XXX
 SG_ VCFRONT_lightStatusMuxIndex M : 39|3@1+ (1,0) [0|7] "" Vector__XXX
 SG_ VCFRONT_isAdaptiveHighBeamAvaila m1 : 42|1@1+ (1,0) [0|1] "" Vector__XXX
 SG_ VCFRONT_isAdaptiveHighBeamFaulte m1 : 43|1@1+ (1,0) [0|1] "" Vector__XXX
 SG_ VCFRONT_isBendLightingAvailable m1 : 44|1@1+ (1,0) [0|1] "" Vector__XXX
 SG_ VCFRONT_advancedDrivingBeamStatu m1 : 45|2@1+ (1,0) [0|3] "" Vector__XXX
 SG_ VCFRONT_headlampBendAngle m1 : 47|8@1- (0.1,0) [-12.7|12.7] "deg" Vector__XXX
 SG_ VCFRONT_headlampRoadClass m1 : 55|2@1+ (1,0) [0|3] "" Vector__XXX

CM_ BO_ 832 "Front body controller message: alert matrix";
CM_ SG_ 832 VCFRONT_matrixIndex "Front body controller: matrix index";
CM_ SG_ 832 VCFRONT_a001_WatchdogReset "Front body controller: a001 watchdog reset";
CM_ SG_ 832 VCFRONT_a002_PowerLossReset "Front body controller: a002 power loss reset";
CM_ SG_ 832 VCFRONT_a003_SWAssertion "Front body controller: a003 SW assertion";
CM_ SG_ 832 VCFRONT_a004_adaptiveHeadlightsU "Front body controller: a004 adaptive headlights unavailable";
CM_ SG_ 832 VCFRONT_a005_CANTXError "Front body controller: a005 CANTX error";
CM_ SG_ 832 VCFRONT_a006_CANTX_cyclicError "Front body controller: a006 CANTX cyclic error";
CM_ SG_ 832 VCFRONT_a008_adaptiveHeadlightsU "Front body controller: a008 adaptive headlights unavailable stalk";
CM_ SG_ 832 VCFRONT_a009_LCCPurgeAttempted "Front body controller: a009 LCC purge attempted";
CM_ SG_ 832 VCFRONT_a010_ExtSupplyVoltError "Front body controller: a010 ext supply volt error";
CM_ SG_ 832 VCFRONT_a012_CPUReset "Front body controller: a012 CPU reset";
CM_ SG_ 832 VCFRONT_a013_AlertManagerFault "Front body controller: a013 alert manager fault";
CM_ SG_ 832 VCFRONT_a015_NVMMError "Front body controller: a015 NVMM error";
CM_ SG_ 832 VCFRONT_a016_NVMMRecordError "Front body controller: a016 NVMM record error";
CM_ SG_ 832 VCFRONT_a017_NVMMStatusDbg "Front body controller: a017 NVMM status dbg";
CM_ SG_ 832 VCFRONT_a021_TaskSchedulerError "Front body controller: a021 task scheduler error";
CM_ SG_ 832 VCFRONT_a022_TaskInitError "Front body controller: a022 task init error";
CM_ SG_ 832 VCFRONT_a029_CoreDump "Front body controller: a029 core dump";
CM_ SG_ 832 VCFRONT_a030_ECULogUploadRequest "Front body controller: a030 ECU log upload request";
CM_ SG_ 832 VCFRONT_a031_UDSActive "Front body controller: a031 UDS active";
CM_ SG_ 832 VCFRONT_a032_ipcWatchdogExpired "Front body controller: a032 ipc watchdog expired";
CM_ SG_ 832 VCFRONT_a033_eccNonCorrectableEr "Front body controller: a033 ecc non correctable error";
CM_ SG_ 832 VCFRONT_a038_ProtFaultInfo "Front body controller: a038 prot fault info";
CM_ SG_ 832 VCFRONT_a039_ProtFaultAddress "Front body controller: a039 prot fault address";
CM_ SG_ 832 VCFRONT_a040_Backtrace "Front body controller: a040 backtrace";
CM_ SG_ 832 VCFRONT_a041_HighCPULoad "Front body controller: a041 high CPU load";
CM_ SG_ 832 VCFRONT_a042_HighStackUsage "Front body controller: a042 high stack usage";
CM_ SG_ 832 VCFRONT_a043_Task1msError "Front body controller: a043 task1ms error";
CM_ SG_ 832 VCFRONT_a044_Task10msError "Front body controller: a044 task10ms error";
CM_ SG_ 832 VCFRONT_a045_Task100msError "Front body controller: a045 task100ms error";
CM_ SG_ 832 VCFRONT_a046_Task1000msError "Front body controller: a046 task1000ms error";
CM_ SG_ 832 VCFRONT_a047_resetReason "Front body controller: a047 reset reason";
CM_ SG_ 832 VCFRONT_a053_wiperCommErrorUser "Front body controller: a053 wiper comm error user";
CM_ SG_ 832 VCFRONT_a054_compressorLowFlowUs "Front body controller: a054 compressor low flow user facing";
CM_ SG_ 832 VCFRONT_a057_HVP_MIA "Front body controller: a057 HVP MIA";
CM_ SG_ 832 VCFRONT_a058_inputRHighSyncDebug "Front body controller: a058 input r high sync debug";
CM_ SG_ 832 VCFRONT_a059_inputResistanceHigh "Front body controller: a059 input resistance high";
CM_ SG_ 832 VCFRONT_a060_engineeringBuild "Front body controller: a060 engineering build";
CM_ SG_ 832 VCFRONT_a061_XCPConnected "Front body controller: a061 XCP connected";
CM_ SG_ 832 VCFRONT_a062_XCPWasConnected "Front body controller: a062 XCP was connected";
CM_ SG_ 832 VCFRONT_a063_SwitchFault "Front body controller: a063 switch fault";
CM_ SG_ 832 VCFRONT_a064_busSleepReqTimeout "Front body controller: a064 bus sleep req timeout";
CM_ SG_ 832 VCFRONT_a082_VCRIGHT_IPC_MIA "Front body controller: a082 VCRIGHT IPC MIA";
CM_ SG_ 832 VCFRONT_a083_VCLEFT_IPC_MIA "Front body controller: a083 VCLEFT IPC MIA";
CM_ SG_ 832 VCFRONT_a084_TPMS_MIA "Front body controller: a084 TPMS MIA";
CM_ SG_ 832 VCFRONT_a085_CCCM_MIA "Front body controller: a085 CCCM MIA";
CM_ SG_ 832 VCFRONT_a086_VCBATT_MIA "Front body controller: a086 VCBATT MIA";
CM_ SG_ 832 VCFRONT_a087_DIREL_MIA "Front body controller: a087 DIREL MIA";
CM_ SG_ 832 VCFRONT_a088_DIRER_MIA "Front body controller: a088 DIRER MIA";
CM_ SG_ 832 VCFRONT_a089_IBST_MIA "Front body controller: a089 IBST MIA";
CM_ SG_ 832 VCFRONT_a090_APS_MIA "Front body controller: a090 APS MIA";
CM_ SG_ 832 VCFRONT_a091_CMPD_MIA "Front body controller: a091 CMPD MIA";
CM_ SG_ 832 VCFRONT_a092_VCSEATD_MIA "Front body controller: a092 VCSEATD MIA";
CM_ SG_ 832 VCFRONT_a093_VCSEATP_MIA "Front body controller: a093 VCSEATP MIA";
CM_ SG_ 832 VCFRONT_a094_EPAS3P_MIA "Front body controller: a094 EPAS3 p MIA";
CM_ SG_ 832 VCFRONT_a095_CHG_MIA "Front body controller: a095 CHG MIA";
CM_ SG_ 832 VCFRONT_a096_OCS1P_MIA "Front body controller: a096 OCS1 p MIA";
CM_ SG_ 832 VCFRONT_a097_CMP_MIA "Front body controller: a097 CMP MIA";
CM_ SG_ 832 VCFRONT_a098_DIR_MIA "Front body controller: a098 DIR MIA";
CM_ SG_ 832 VCFRONT_a099_PARK_MIA "Front body controller: a099 PARK MIA";
CM_ SG_ 832 VCFRONT_a100_CANbus_MIA "Front body controller: a100 CA nbus MIA";
CM_ SG_ 832 VCFRONT_a101_PM_MIA "Front body controller: a101 PM MIA";
CM_ SG_ 832 VCFRONT_a102_PTC_MIA "Front body controller: a102 PTC MIA";
CM_ SG_ 832 VCFRONT_a103_CP_MIA "Front body controller: a103 CP MIA";
CM_ SG_ 832 VCFRONT_a104_DAS_MIA "Front body controller: a104 DAS MIA";
CM_ SG_ 832 VCFRONT_a105_TAS_MIA "Front body controller: a105 TAS MIA";
CM_ SG_ 832 VCFRONT_a106_PCS_MIA "Front body controller: a106 PCS MIA";
CM_ SG_ 832 VCFRONT_a107_BMS_MIA "Front body controller: a107 BMS MIA";
CM_ SG_ 832 VCFRONT_a108_DIF_MIA "Front body controller: a108 DIF MIA";
CM_ SG_ 832 VCFRONT_a109_RCM_MIA "Front body controller: a109 RCM MIA";
CM_ SG_ 832 VCFRONT_a110_GTW_MIA "Front body controller: a110 GTW MIA";
CM_ SG_ 832 VCFRONT_a111_EPBR_MIA "Front body controller: a111 EPBR MIA";
CM_ SG_ 832 VCFRONT_a112_EPBL_MIA "Front body controller: a112 EPBL MIA";
CM_ SG_ 832 VCFRONT_a113_UI_MIA "Front body controller: a113 UI MIA";
CM_ SG_ 832 VCFRONT_a114_ESP_MIA "Front body controller: a114 ESP MIA";
CM_ SG_ 832 VCFRONT_a115_VCSEC_MIA "Front body controller: a115 VCSEC MIA";
CM_ SG_ 832 VCFRONT_a116_VCRIGHT_MIA "Front body controller: a116 VCRIGHT MIA";
CM_ SG_ 832 VCFRONT_a117_VCLEFT_MIA "Front body controller: a117 VCLEFT MIA";
CM_ SG_ 832 VCFRONT_a118_VCFRONT_MIA "Front body controller: a118 VCFRONT MIA";
CM_ SG_ 832 VCFRONT_a119_SCCM_MIA "Front body controller: a119 SCCM MIA";
CM_ SG_ 832 VCFRONT_a120_DI_DRIVE_MIA "Front body controller: a120 DI DRIVE MIA";
CM_ SG_ 832 VCFRONT_a121_pumpBatICLatchFault "Front body controller: a121 pump bat IC latch fault";
CM_ SG_ 832 VCFRONT_a122_pumpBatICWarning "Front body controller: a122 pump bat IC warning";
CM_ SG_ 832 VCFRONT_a123_pumpPtICLatchFault "Front body controller: a123 pump pt IC latch fault";
CM_ SG_ 832 VCFRONT_a124_pumpPtICWarning "Front body controller: a124 pump pt IC warning";
CM_ SG_ 832 VCFRONT_a125_thmlFanICLatchFault "Front body controller: a125 thml fan IC latch fault";
CM_ SG_ 832 VCFRONT_a126_thmlFanICWarning "Front body controller: a126 thml fan IC warning";
CM_ SG_ 832 VCFRONT_a127_vcleftEFuseTrip "Front body controller: a127 vcleft e fuse trip";
CM_ SG_ 832 VCFRONT_a128_vcrightEFuseTrip "Front body controller: a128 vcright e fuse trip";
CM_ SG_ 832 VCFRONT_a129_pcsEFuseTrip "Front body controller: a129 pcs e fuse trip";
CM_ SG_ 832 VCFRONT_a130_epas3pEFuseTrip "Front body controller: a130 epas3p e fuse trip";
CM_ SG_ 832 VCFRONT_a131_epas3sEFuseTrip "Front body controller: a131 epas3s e fuse trip";
CM_ SG_ 832 VCFRONT_a132_iBoosterEFuseTrip "Front body controller: a132 i booster e fuse trip";
CM_ SG_ 832 VCFRONT_a133_espEFuseTrip "Front body controller: a133 esp e fuse trip";
CM_ SG_ 832 VCFRONT_a134_fusedHighEFuseTrip "Front body controller: a134 fused high e fuse trip";
CM_ SG_ 832 VCFRONT_a135_coolantLevelLow "Front body controller: a135 coolant level low";
CM_ SG_ 832 VCFRONT_a136_refrigDischTempSns "Front body controller: a136 refrig disch temp sns";
CM_ SG_ 832 VCFRONT_a137_refrigDischPresSns "Front body controller: a137 refrig disch pres sns";
CM_ SG_ 832 VCFRONT_a138_refrigSuctTempSns "Front body controller: a138 refrig suct temp sns";
CM_ SG_ 832 VCFRONT_a139_refrigSuctPresSns "Front body controller: a139 refrig suct pres sns";
CM_ SG_ 832 VCFRONT_a140_coolantTempPtSns "Front body controller: a140 coolant temp pt sns";
CM_ SG_ 832 VCFRONT_a141_coolantTempBatSns "Front body controller: a141 coolant temp bat sns";
CM_ SG_ 832 VCFRONT_a142_exvMotorFault "Front body controller: a142 exv motor fault";
CM_ SG_ 832 VCFRONT_a143_pumpBatICTransFault "Front body controller: a143 pump bat IC trans fault";
CM_ SG_ 832 VCFRONT_a144_pumpPtICTransFault "Front body controller: a144 pump pt IC trans fault";
CM_ SG_ 832 VCFRONT_a145_thmlFanICTransFault "Front body controller: a145 thml fan IC trans fault";
CM_ SG_ 832 VCFRONT_a146_pumpBatSoftStall "Front body controller: a146 pump bat soft stall";
CM_ SG_ 832 VCFRONT_a147_pumpPtSoftStall "Front body controller: a147 pump pt soft stall";
CM_ SG_ 832 VCFRONT_a148_thmlFanSoftStall "Front body controller: a148 thml fan soft stall";
CM_ SG_ 832 VCFRONT_a149_BLEFrontPowerCycled "Front body controller: a149 BLE front power cycled";
CM_ SG_ 832 VCFRONT_a150_pumpBatLowRPMCBang "Front body controller: a150 pump bat low RPMC bang";
CM_ SG_ 832 VCFRONT_a151_pumpPtLowRPMCBang "Front body controller: a151 pump pt low RPMC bang";
CM_ SG_ 832 VCFRONT_a152_thmlFanLowRPMCBang "Front body controller: a152 thml fan low RPMC bang";
CM_ SG_ 832 VCFRONT_a153_userPresenceDisplay "Front body controller: a153 user presence display mismatch clrd";
CM_ SG_ 832 VCFRONT_a154_prechargeDCRData1 "Front body controller: a154 precharge DCR data1";
CM_ SG_ 832 VCFRONT_a155_prechargeDCRData2 "Front body controller: a155 precharge DCR data2";
CM_ SG_ 832 VCFRONT_a156_louverBlockage "Front body controller: a156 louver blockage";
CM_ SG_ 832 VCFRONT_a157_louverBreakage "Front body controller: a157 louver breakage";
CM_ SG_ 832 VCFRONT_a158_louverDisconnected "Front body controller: a158 louver disconnected";
CM_ SG_ 832 VCFRONT_a159_coolantValveFault "Front body controller: a159 coolant valve fault";
CM_ SG_ 832 VCFRONT_a160_compressorInhibited "Front body controller: a160 compressor inhibited";
CM_ SG_ 832 VCFRONT_a161_compressorSelfFault "Front body controller: a161 compressor self fault";
CM_ SG_ 832 VCFRONT_a162_compressorInhibited "Front body controller: a162 compressor inhibited context";
CM_ SG_ 832 VCFRONT_a163_compressorDisabledF "Front body controller: a163 compressor disabled FSR";
CM_ SG_ 832 VCFRONT_a164_eFuseLckoutMissing "Front body controller: a164 e fuse lckout missing";
CM_ SG_ 832 VCFRONT_a165_unxpctdEFuseLckout "Front body controller: a165 unxpctd e fuse lckout";
CM_ SG_ 832 VCFRONT_a166_rightHCMMIA "Front body controller: a166 right HCMMIA";
CM_ SG_ 832 VCFRONT_a167_leftHCMMIA "Front body controller: a167 left HCMMIA";
CM_ SG_ 832 VCFRONT_a168_hcmShortToVBAT "Front body controller: a168 hcm short to VBAT";
CM_ SG_ 832 VCFRONT_a169_hcmPhaseEnableFail "Front body controller: a169 hcm phase enable fail";
CM_ SG_ 832 VCFRONT_a170_hcmUnderVoltage "Front body controller: a170 hcm under voltage";
CM_ SG_ 832 VCFRONT_a171_driveBlckdByMsmtch "Front body controller: a171 drive blckd by msmtch";
CM_ SG_ 832 VCFRONT_a172_wsteHtBlckdByMsmtch "Front body controller: a172 wste ht blckd by msmtch";
CM_ SG_ 832 VCFRONT_a173_HVBlckdByMsmtch "Front body controller: a173 HV blckd by msmtch";
CM_ SG_ 832 VCFRONT_a174_driveNotAuthed "Front body controller: a174 drive not authed";
CM_ SG_ 832 VCFRONT_a175_ambientTempSns "Front body controller: a175 ambient temp sns";
CM_ SG_ 832 VCFRONT_a176_vehicleInSelfTest "Front body controller: a176 vehicle in self test";
CM_ SG_ 832 VCFRONT_a177_mcuAudioEFuseFault "Front body controller: a177 mcu audio e fuse fault";
CM_ SG_ 832 VCFRONT_a178_compLiquidPumpOut "Front body controller: a178 comp liquid pump out";
CM_ SG_ 832 VCFRONT_a179_highLVAmpsIntoPCS "Front body controller: a179 high LV amps into PCS";
CM_ SG_ 832 VCFRONT_a180_DCDCNotSupportingLV "Front body controller: a180 DCDC not supporting LV bus";
CM_ SG_ 832 VCFRONT_a181_homelinkMIA "Front body controller: a181 homelink MIA";
CM_ SG_ 832 VCFRONT_a182_replaceLVBattery "Front body controller: a182 replace LV battery";
CM_ SG_ 832 VCFRONT_a183_replaceLVBattery2 "Front body controller: a183 replace LV battery2";
CM_ SG_ 832 VCFRONT_a184_cabinCoolingPerform "Front body controller: a184 cabin cooling performance abnormal";
CM_ SG_ 832 VCFRONT_a185_washerFluidLow "Front body controller: a185 washer fluid low";
CM_ SG_ 832 VCFRONT_a186_noDriveChgCableCon "Front body controller: a186 no drive chg cable con";
CM_ SG_ 832 VCFRONT_a187_busesNotSleeping "Front body controller: a187 buses not sleeping";
CM_ SG_ 832 VCFRONT_a188_sleepFailed "Front body controller: a188 sleep failed";
CM_ SG_ 832 VCFRONT_a189_IBSMIA "Front body controller: a189 IBSMIA";
CM_ SG_ 832 VCFRONT_a190_linSchedulingInfo "Front body controller: a190 lin scheduling info";
CM_ SG_ 832 VCFRONT_a191_exitDriveLowLVBusVo "Front body controller: a191 exit drive low LV bus voltage";
CM_ SG_ 832 VCFRONT_a192_vehicleLoadShed "Front body controller: a192 vehicle load shed";
CM_ SG_ 832 VCFRONT_a193_mcuAudioRetry "Front body controller: a193 mcu audio retry";
CM_ SG_ 832 VCFRONT_a194_iBoosterRetry "Front body controller: a194 i booster retry";
CM_ SG_ 832 VCFRONT_a195_drveBlckdVltgeTooHg "Front body controller: a195 drve blckd vltge too hgh";
CM_ SG_ 832 VCFRONT_a196_discnctdLVBattery "Front body controller: a196 discnctd LV battery";
CM_ SG_ 832 VCFRONT_a197_prechargeDCRData3 "Front body controller: a197 precharge DCR data3";
CM_ SG_ 832 VCFRONT_a198_PRVCANOverterminate "Front body controller: a198 PRVCAN overterminate";
CM_ SG_ 832 VCFRONT_a199_PRVCANUndertrminate "Front body controller: a199 PRVCAN undertrminate";
CM_ SG_ 832 VCFRONT_a200_vcleftSelfTestFail "Front body controller: a200 vcleft self test fail";
CM_ SG_ 832 VCFRONT_a201_vcrightSelfTestFail "Front body controller: a201 vcright self test fail";
CM_ SG_ 832 VCFRONT_a202_pcsSelfTestFail "Front body controller: a202 pcs self test fail";
CM_ SG_ 832 VCFRONT_a203_epas3pSelfTestFail "Front body controller: a203 epas3p self test fail";
CM_ SG_ 832 VCFRONT_a204_epas3sSelfTestFail "Front body controller: a204 epas3s self test fail";
CM_ SG_ 832 VCFRONT_a205_iBoosterSelfTestFai "Front body controller: a205 i booster self test fail";
CM_ SG_ 832 VCFRONT_a206_espSelfTestFail "Front body controller: a206 esp self test fail";
CM_ SG_ 832 VCFRONT_a207_vbatFusdSelfTestFai "Front body controller: a207 vbat fusd self test fail";
CM_ SG_ 832 VCFRONT_a208_brakeFluidLow "Front body controller: a208 brake fluid low";
CM_ SG_ 832 VCFRONT_a209_brakeFluidSNA "Front body controller: a209 brake fluid SNA";
CM_ SG_ 832 VCFRONT_a210_coolantValveCalib "Front body controller: a210 coolant valve calib";
CM_ SG_ 832 VCFRONT_a211_I2CFault "Front body controller: a211 I2 c fault";
CM_ SG_ 832 VCFRONT_a212_IBSOverTemp "Front body controller: a212 IBS over temp";
CM_ SG_ 832 VCFRONT_a213_LVOvercharge "Front body controller: a213 LV overcharge";
CM_ SG_ 832 VCFRONT_a214_ptPumpCompromised "Front body controller: a214 pt pump compromised";
CM_ SG_ 832 VCFRONT_a215_ptPumpMIA "Front body controller: a215 pt pump MIA";
CM_ SG_ 832 VCFRONT_a216_powerCutoffImminent "Front body controller: a216 power cutoff imminent";
CM_ SG_ 832 VCFRONT_a217_battPumpCompromised "Front body controller: a217 batt pump compromised";
CM_ SG_ 832 VCFRONT_a218_socMonitorDetectedT "Front body controller: a218 soc monitor detected threshold soc";
CM_ SG_ 832 VCFRONT_a219_LVVoltFloorRchd "Front body controller: a219 LV volt floor rchd";
CM_ SG_ 832 VCFRONT_a220_reverseBatteryFault "Front body controller: a220 reverse battery fault";
CM_ SG_ 832 VCFRONT_a221_leftTurnLightFault "Front body controller: a221 left turn light fault";
CM_ SG_ 832 VCFRONT_a222_rightTurnLightFault "Front body controller: a222 right turn light fault";
CM_ SG_ 832 VCFRONT_a223_12VTempSensDiscnect "Front body controller: a223 12 v temp sens discnect";
CM_ SG_ 832 VCFRONT_a224_revBatChrgPmpFault "Front body controller: a224 rev bat chrg pmp fault";
CM_ SG_ 832 VCFRONT_a225_driveBlckdByShowroo "Front body controller: a225 drive blckd by showroom";
CM_ SG_ 832 VCFRONT_a226_battPumpMIA "Front body controller: a226 batt pump MIA";
CM_ SG_ 832 VCFRONT_a227_radFanCompromised "Front body controller: a227 rad fan compromised";
CM_ SG_ 832 VCFRONT_a228_pumpBatFbkSanity "Front body controller: a228 pump bat fbk sanity";
CM_ SG_ 832 VCFRONT_a229_pumpPtFbkSanity "Front body controller: a229 pump pt fbk sanity";
CM_ SG_ 832 VCFRONT_a230_thmlFanFbkSanity "Front body controller: a230 thml fan fbk sanity";
CM_ SG_ 832 VCFRONT_a231_12VTempSensShort "Front body controller: a231 12 v temp sens short";
CM_ SG_ 832 VCFRONT_a232_lowSideControllerHi "Front body controller: a232 low side controller high fdbk";
CM_ SG_ 832 VCFRONT_a233_autopilot1EFuseFaul "Front body controller: a233 autopilot1 e fuse fault";
CM_ SG_ 832 VCFRONT_a234_autopilot2EFuseFaul "Front body controller: a234 autopilot2 e fuse fault";
CM_ SG_ 832 VCFRONT_a235_ptTempSnsIrrational "Front body controller: a235 pt temp sns irrational";
CM_ SG_ 832 VCFRONT_a236_batTempSnsIrrationa "Front body controller: a236 bat temp sns irrational";
CM_ SG_ 832 VCFRONT_a237_pumpBatChipComms "Front body controller: a237 pump bat chip comms";
CM_ SG_ 832 VCFRONT_a238_pumpPtChipComms "Front body controller: a238 pump pt chip comms";
CM_ SG_ 832 VCFRONT_a239_thmlFanChipComms "Front body controller: a239 thml fan chip comms";
CM_ SG_ 832 VCFRONT_a240_lowSideCompromised "Front body controller: a240 low side compromised";
CM_ SG_ 832 VCFRONT_a241_radFanMIA "Front body controller: a241 rad fan MIA";
CM_ SG_ 832 VCFRONT_a242_drveBlckdVltgeTooLo "Front body controller: a242 drve blckd vltge too low";
CM_ SG_ 832 VCFRONT_a243_LVOverchargeInstc "Front body controller: a243 LV overcharge instc";
CM_ SG_ 832 VCFRONT_a244_sleepBypassFault "Front body controller: a244 sleep bypass fault";
CM_ SG_ 832 VCFRONT_a245_pump1EFuseFault "Front body controller: a245 pump1 e fuse fault";
CM_ SG_ 832 VCFRONT_a246_pump2EFuseFault "Front body controller: a246 pump2 e fuse fault";
CM_ SG_ 832 VCFRONT_a247_evapSolenoidFault "Front body controller: a247 evap solenoid fault";
CM_ SG_ 832 VCFRONT_a248_voltageOutOfSpec "Front body controller: a248 voltage out of spec";
CM_ SG_ 832 VCFRONT_a249_coolantValveBadMode "Front body controller: a249 coolant valve bad mode";
CM_ SG_ 832 VCFRONT_a250_headlampsNotAimed "Front body controller: a250 headlamps not aimed";
CM_ SG_ 832 VCFRONT_a251_UIWakeupTrigger "Front body controller: a251 UI wakeup trigger";
CM_ SG_ 832 VCFRONT_a252_controllerWakeup "Front body controller: a252 controller wakeup";
CM_ SG_ 832 VCFRONT_a253_maxChrgeSssionTmeou "Front body controller: a253 max chrge sssion tmeout";
CM_ SG_ 832 VCFRONT_a254_pumpBatStopped "Front body controller: a254 pump bat stopped";
CM_ SG_ 832 VCFRONT_a255_pumpPtStopped "Front body controller: a255 pump pt stopped";
CM_ SG_ 832 VCFRONT_a256_compTornShaftSeal "Front body controller: a256 comp torn shaft seal";
CM_ SG_ 832 VCFRONT_a257_portExpanderVOR "Front body controller: a257 port expander VOR";
CM_ SG_ 832 VCFRONT_a258_resistanceEstimatio "Front body controller: a258 resistance estimation run";
CM_ SG_ 832 VCFRONT_a259_LVVoltageDropOnHigh "Front body controller: a259 LV voltage drop on high load current";
CM_ SG_ 832 VCFRONT_a260_deadLVBattery "Front body controller: a260 dead LV battery";
CM_ SG_ 832 VCFRONT_a261_vcleftVoltageMismat "Front body controller: a261 vcleft voltage mismatch";
CM_ SG_ 832 VCFRONT_a262_vcrightVoltageMisma "Front body controller: a262 vcright voltage mismatch";
CM_ SG_ 832 VCFRONT_a263_pcsVoltageMismatch "Front body controller: a263 pcs voltage mismatch";
CM_ SG_ 832 VCFRONT_a264_iBoosterVoltageMism "Front body controller: a264 i booster voltage mismatch";
CM_ SG_ 832 VCFRONT_a265_ESPVoltageMismatch "Front body controller: a265 ESP voltage mismatch";
CM_ SG_ 832 VCFRONT_a266_EPAS3pVoltageMismat "Front body controller: a266 epas3p voltage mismatch";
CM_ SG_ 832 VCFRONT_a267_EPAS3sVoltageMismat "Front body controller: a267 epas3s voltage mismatch";
CM_ SG_ 832 VCFRONT_a268_vbatFusedVoltageMis "Front body controller: a268 vbat fused voltage mismatch";
CM_ SG_ 832 VCFRONT_a269_drveBlckdVltgeTooLo "Front body controller: a269 drve blckd vltge too low2";
CM_ SG_ 832 VCFRONT_a270_prechargeFailed "Front body controller: a270 precharge failed";
CM_ SG_ 832 VCFRONT_a271_LVBatteryPermSuppor "Front body controller: a271 LV battery perm supported";
CM_ SG_ 832 VCFRONT_a273_wiperFrictionModelF "Front body controller: a273 wiper friction model fault";
CM_ SG_ 832 VCFRONT_a274_failureToPrechargeR "Front body controller: a274 failure to precharge risk2";
CM_ SG_ 832 VCFRONT_a275_TLVBMS_BmbCommunica "Front body controller: a275 TLVBMS bmb communication";
CM_ SG_ 832 VCFRONT_a276_TLVBMS_BmbDataInteg "Front body controller: a276 TLVBMS bmb data integrity loss";
CM_ SG_ 832 VCFRONT_a277_TLVBMS_BmbStatusReg "Front body controller: a277 TLVBMS bmb status reg error";
CM_ SG_ 832 VCFRONT_a278_TLVBMS_BmbHwOverCur "Front body controller: a278 TLVBMS bmb hw over current fault";
CM_ SG_ 832 VCFRONT_a279_refrigLiquidTempSns "Front body controller: a279 refrig liquid temp sns";
CM_ SG_ 832 VCFRONT_a280_refrigLiquidPresSns "Front body controller: a280 refrig liquid pres sns";
CM_ SG_ 832 VCFRONT_a281_alcoholInterlockBlo "Front body controller: a281 alcohol interlock blocking drive";
CM_ SG_ 832 VCFRONT_a282_coolantLevelSensorF "Front body controller: a282 coolant level sensor fault";
CM_ SG_ 832 VCFRONT_a283_thmlFanLimitedByCur "Front body controller: a283 thml fan limited by current";
CM_ SG_ 832 VCFRONT_a284_chillerExvFault "Front body controller: a284 chiller exv fault";
CM_ SG_ 832 VCFRONT_a285_evaporatorExvFault "Front body controller: a285 evaporator exv fault";
CM_ SG_ 832 VCFRONT_a286_recircExvFault "Front body controller: a286 recirc exv fault";
CM_ SG_ 832 VCFRONT_a287_lccExvFault "Front body controller: a287 lcc exv fault";
CM_ SG_ 832 VCFRONT_a288_ccLeftExvFault "Front body controller: a288 cc left exv fault";
CM_ SG_ 832 VCFRONT_a289_ccRightExvFault "Front body controller: a289 cc right exv fault";
CM_ SG_ 832 VCFRONT_a290_leftFogLightFault "Front body controller: a290 left fog light fault";
CM_ SG_ 832 VCFRONT_a291_rightFogLightFault "Front body controller: a291 right fog light fault";
CM_ SG_ 832 VCFRONT_a292_sideMarkerLightPipe "Front body controller: a292 side marker light pipe fault";
CM_ SG_ 832 VCFRONT_a293_interiorFrunkLightF "Front body controller: a293 interior frunk light fault";
CM_ SG_ 832 VCFRONT_a294_leftSideRepeaterLig "Front body controller: a294 left side repeater light fault";
CM_ SG_ 832 VCFRONT_a295_rightSideRepeaterLi "Front body controller: a295 right side repeater light fault";
CM_ SG_ 832 VCFRONT_a296_turnSignalIssue "Front body controller: a296 turn signal issue";
CM_ SG_ 832 VCFRONT_a297_TLVBMS_BmbHwOverTem "Front body controller: a297 TLVBMS bmb hw over temperature fault";
CM_ SG_ 832 VCFRONT_a298_radiatorLowAirFlowD "Front body controller: a298 radiator low air flow detected";
CM_ SG_ 832 VCFRONT_a299_homelinkConfigurati "Front body controller: a299 homelink configuration failed";
CM_ SG_ 832 VCFRONT_a300_louverActuatorSwapD "Front body controller: a300 louver actuator swap detected";
CM_ SG_ 832 VCFRONT_a301_wipersFactoryDisabl "Front body controller: a301 wipers factory disabled";
CM_ SG_ 832 VCFRONT_a302_wiperCommError "Front body controller: a302 wiper comm error";
CM_ SG_ 832 VCFRONT_a303_frunkAccessPostActi "Front body controller: a303 frunk access post active";
CM_ SG_ 832 VCFRONT_a304_frunkReleaseFailed "Front body controller: a304 frunk release failed";
CM_ SG_ 832 VCFRONT_a305_frunkPriOverCurrent "Front body controller: a305 frunk pri over current";
CM_ SG_ 832 VCFRONT_a306_frunkPriUnderCurren "Front body controller: a306 frunk pri under current";
CM_ SG_ 832 VCFRONT_a307_frunkSecOverCurrent "Front body controller: a307 frunk sec over current";
CM_ SG_ 832 VCFRONT_a308_frunkSecUnderCurren "Front body controller: a308 frunk sec under current";
CM_ SG_ 832 VCFRONT_a309_frunkEmergencyRelea "Front body controller: a309 frunk emergency release pressed";
CM_ SG_ 832 VCFRONT_a310_vcleftOvertempSlope "Front body controller: a310 vcleft overtemp slope";
CM_ SG_ 832 VCFRONT_a311_vcrightOvertempSlop "Front body controller: a311 vcright overtemp slope";
CM_ SG_ 832 VCFRONT_a312_pcsOvertempSlope "Front body controller: a312 pcs overtemp slope";
CM_ SG_ 832 VCFRONT_a313_epas3pOvertempSlope "Front body controller: a313 epas3p overtemp slope";
CM_ SG_ 832 VCFRONT_a314_epas3sOvertempSlope "Front body controller: a314 epas3s overtemp slope";
CM_ SG_ 832 VCFRONT_a315_iboosterOvertempSlo "Front body controller: a315 ibooster overtemp slope";
CM_ SG_ 832 VCFRONT_a316_espOvertempSlope "Front body controller: a316 esp overtemp slope";
CM_ SG_ 832 VCFRONT_a317_vbatFusedOvertempSl "Front body controller: a317 vbat fused overtemp slope";
CM_ SG_ 832 VCFRONT_a318_vcleftOvertempMax "Front body controller: a318 vcleft overtemp max";
CM_ SG_ 832 VCFRONT_a319_vcrightOvertempMax "Front body controller: a319 vcright overtemp max";
CM_ SG_ 832 VCFRONT_a320_pcsOvertempMax "Front body controller: a320 pcs overtemp max";
CM_ SG_ 832 VCFRONT_a321_epas3pOvertempMax "Front body controller: a321 epas3p overtemp max";
CM_ SG_ 832 VCFRONT_a322_epas3sOvertempMax "Front body controller: a322 epas3s overtemp max";
CM_ SG_ 832 VCFRONT_a323_iboosterOvertempMax "Front body controller: a323 ibooster overtemp max";
CM_ SG_ 832 VCFRONT_a324_espOvertempMax "Front body controller: a324 esp overtemp max";
CM_ SG_ 832 VCFRONT_a325_vbatFusedOvertempMa "Front body controller: a325 vbat fused overtemp max";
CM_ SG_ 832 VCFRONT_a326_vcleftSlowTripOC "Front body controller: a326 vcleft slow trip OC";
CM_ SG_ 832 VCFRONT_a327_vcrightSlowTripOC "Front body controller: a327 vcright slow trip OC";
CM_ SG_ 832 VCFRONT_a328_pcsSlowTripOC "Front body controller: a328 pcs slow trip OC";
CM_ SG_ 832 VCFRONT_a329_epas3pSlowTripOC "Front body controller: a329 epas3p slow trip OC";
CM_ SG_ 832 VCFRONT_a330_epas3sSlowTripOC "Front body controller: a330 epas3s slow trip OC";
CM_ SG_ 832 VCFRONT_a331_iboosterSlowTripOC "Front body controller: a331 ibooster slow trip OC";
CM_ SG_ 832 VCFRONT_a332_espSlowTripOC "Front body controller: a332 esp slow trip OC";
CM_ SG_ 832 VCFRONT_a333_vbatFusedSlowTripOC "Front body controller: a333 vbat fused slow trip OC";
CM_ SG_ 832 VCFRONT_a334_vcleftFastTripOCMax "Front body controller: a334 vcleft fast trip OC max";
CM_ SG_ 832 VCFRONT_a335_vcrightFastTripOCMa "Front body controller: a335 vcright fast trip OC max";
CM_ SG_ 832 VCFRONT_a336_pcsFastTripOCMax "Front body controller: a336 pcs fast trip OC max";
CM_ SG_ 832 VCFRONT_a337_epas3pFastTripOCMax "Front body controller: a337 epas3p fast trip OC max";
CM_ SG_ 832 VCFRONT_a338_epas3sFastTripOCMax "Front body controller: a338 epas3s fast trip OC max";
CM_ SG_ 832 VCFRONT_a339_iboosterFastTripOCM "Front body controller: a339 ibooster fast trip OC max";
CM_ SG_ 832 VCFRONT_a340_espFastTripOCMax "Front body controller: a340 esp fast trip OC max";
CM_ SG_ 832 VCFRONT_a341_vbatFusedFastTripOC "Front body controller: a341 vbat fused fast trip OC max";
CM_ SG_ 832 VCFRONT_a342_vcleftFastTripSlope "Front body controller: a342 vcleft fast trip slope";
CM_ SG_ 832 VCFRONT_a343_vcrightFastTripSlop "Front body controller: a343 vcright fast trip slope";
CM_ SG_ 832 VCFRONT_a344_pcsFastTripSlope "Front body controller: a344 pcs fast trip slope";
CM_ SG_ 832 VCFRONT_a345_epas3pFastTripSlope "Front body controller: a345 epas3p fast trip slope";
CM_ SG_ 832 VCFRONT_a346_epas3sFastTripSlope "Front body controller: a346 epas3s fast trip slope";
CM_ SG_ 832 VCFRONT_a347_iboosterFastTripSlo "Front body controller: a347 ibooster fast trip slope";
CM_ SG_ 832 VCFRONT_a348_espFastTripSlope "Front body controller: a348 esp fast trip slope";
CM_ SG_ 832 VCFRONT_a349_vbatFusedFastTripSl "Front body controller: a349 vbat fused fast trip slope";
CM_ SG_ 832 VCFRONT_a350_espValveCurrentSens "Front body controller: a350 esp valve current sense saturated";
CM_ SG_ 832 VCFRONT_a351_emergencyFrunkButto "Front body controller: a351 emergency frunk button press ignored";
CM_ SG_ 832 VCFRONT_a352_audioCurrentSpikeDa "Front body controller: a352 audio current spike data";
CM_ SG_ 832 VCFRONT_a353_wiperHeaterUndercur "Front body controller: a353 wiper heater undercurrent";
CM_ SG_ 832 VCFRONT_a354_windshieldCameraHea "Front body controller: a354 windshield camera heater undercurrent";
CM_ SG_ 832 VCFRONT_a355_coolantSysLockout "Front body controller: a355 coolant sys lockout";
CM_ SG_ 832 VCFRONT_a356_refrigSysLockout "Front body controller: a356 refrig sys lockout";
CM_ SG_ 832 VCFRONT_a357_hornUndercurrent "Front body controller: a357 horn undercurrent";
CM_ SG_ 832 VCFRONT_a358_hornOvercurrent "Front body controller: a358 horn overcurrent";
CM_ SG_ 832 VCFRONT_a359_postPORExcessiveAh "Front body controller: a359 post POR excessive ah";
CM_ SG_ 832 VCFRONT_a360_ungracefulAccPlusEx "Front body controller: a360 ungraceful acc plus exit";
CM_ SG_ 832 VCFRONT_a361_washerFluidLowMomen "Front body controller: a361 washer fluid low momentary";
CM_ SG_ 832 VCFRONT_a362_TLVBMS_AllSocCorrec "Front body controller: a362 TLVBMS all soc correction timeout";
CM_ SG_ 832 VCFRONT_a363_TLVBMS_BleedBasedWe "Front body controller: a363 TLVBMS bleed based weak short";
CM_ SG_ 832 VCFRONT_a364_heaterTypeEstimatio "Front body controller: a364 heater type estimation changed";
CM_ SG_ 832 VCFRONT_a365_burnInRoutineEntere "Front body controller: a365 burn in routine entered";
CM_ SG_ 832 VCFRONT_a366_burnInRoutineExited "Front body controller: a366 burn in routine exited";
CM_ SG_ 832 VCFRONT_a367_dischargeRoutineEnt "Front body controller: a367 discharge routine entered";
CM_ SG_ 832 VCFRONT_a368_dischargeRoutineExi "Front body controller: a368 discharge routine exited";
CM_ SG_ 832 VCFRONT_a369_reducedPowerDischar "Front body controller: a369 reduced power discharge";
CM_ SG_ 832 VCFRONT_a370_noLVSupportSocTooLo "Front body controller: a370 no LV support soc too low";
CM_ SG_ 832 VCFRONT_a371_failureToPrechargeR "Front body controller: a371 failure to precharge risk";
CM_ SG_ 832 VCFRONT_a372_TLVBMS_BmbHwOverVol "Front body controller: a372 TLVBMS bmb hw over voltage fault";
CM_ SG_ 832 VCFRONT_a373_chillerControlFlood "Front body controller: a373 chiller control flooding";
CM_ SG_ 832 VCFRONT_a374_lccInletSolenoidFau "Front body controller: a374 lcc inlet solenoid fault";
CM_ SG_ 832 VCFRONT_a375_refVoltageOutOfSpec "Front body controller: a375 ref voltage out of spec";
CM_ SG_ 832 VCFRONT_a376_controllerWakeupDeb "Front body controller: a376 controller wakeup debug";
CM_ SG_ 832 VCFRONT_a377_wiperParkFault "Front body controller: a377 wiper park fault";
CM_ SG_ 832 VCFRONT_a378_wiperECUDebug "Front body controller: a378 wiper ECU debug";
CM_ SG_ 832 VCFRONT_a379_shortedCellTestRunD "Front body controller: a379 shorted cell test run debug";
CM_ SG_ 832 VCFRONT_a380_chillerExvWarning "Front body controller: a380 chiller exv warning";
CM_ SG_ 832 VCFRONT_a381_evaporatorExvWarnin "Front body controller: a381 evaporator exv warning";
CM_ SG_ 832 VCFRONT_a382_recircExvWarning "Front body controller: a382 recirc exv warning";
CM_ SG_ 832 VCFRONT_a383_lccExvWarning "Front body controller: a383 lcc exv warning";
CM_ SG_ 832 VCFRONT_a384_ccLeftExvWarning "Front body controller: a384 cc left exv warning";
CM_ SG_ 832 VCFRONT_a385_ccRightExvWarning "Front body controller: a385 cc right exv warning";
CM_ SG_ 832 VCFRONT_a386_exvMotorWarning "Front body controller: a386 exv motor warning";
CM_ SG_ 832 VCFRONT_a387_shortedCellInstc "Front body controller: a387 shorted cell instc";
CM_ SG_ 832 VCFRONT_a388_shortedCell "Front body controller: a388 shorted cell";
CM_ SG_ 832 VCFRONT_a389_frunkInhibitingRele "Front body controller: a389 frunk inhibiting release at speed";
CM_ SG_ 832 VCFRONT_a390_heatPumpModeConverg "Front body controller: a390 heat pump mode convergence";
CM_ SG_ 832 VCFRONT_a391_frunkLatchSwitchFau "Front body controller: a391 frunk latch switch fault";
CM_ SG_ 832 VCFRONT_a392_TLVBMS_BmbHwUnderVo "Front body controller: a392 TLVBMS bmb hw under voltage fault";
CM_ SG_ 832 VCFRONT_a393_ambientTempNetworkS "Front body controller: a393 ambient temp network sna";
CM_ SG_ 832 VCFRONT_a394_pressureSensorCheck "Front body controller: a394 pressure sensor check fault";
CM_ SG_ 832 VCFRONT_a395_pressureSensorCheck "Front body controller: a395 pressure sensor check inconclusive";
CM_ SG_ 832 VCFRONT_a396_coolantLevelLowUser "Front body controller: a396 coolant level low user facing";
CM_ SG_ 832 VCFRONT_a397_temperatureSensorCh "Front body controller: a397 temperature sensor check fault";
CM_ SG_ 832 VCFRONT_a398_tempSensorCheckInco "Front body controller: a398 temp sensor check inconclusive";
CM_ SG_ 832 VCFRONT_a399_frunkNeverReportedO "Front body controller: a399 frunk never reported open";
CM_ SG_ 832 VCFRONT_a400_TLVBMS_BmbVrefBad "Front body controller: a400 TLVBMS bmb vref bad";
CM_ SG_ 832 VCFRONT_a401_deadLVMinimalAhDisc "Front body controller: a401 dead LV minimal ah discharged";
CM_ SG_ 832 VCFRONT_a402_LVBatteryCannotSupp "Front body controller: a402 LV battery cannot support vehicle";
CM_ SG_ 832 VCFRONT_a403_chargeExitHardCurre "Front body controller: a403 charge exit hard current limit";
CM_ SG_ 832 VCFRONT_a404_resistanceEstimatio "Front body controller: a404 resistance estimation hard failure";
CM_ SG_ 832 VCFRONT_a405_dcrData1 "Front body controller: a405 dcr data1";
CM_ SG_ 832 VCFRONT_a406_dcrData2 "Front body controller: a406 dcr data2";
CM_ SG_ 832 VCFRONT_a407_dcrMilliOhmsAboveTh "Front body controller: a407 dcr milli ohms above threshold";
CM_ SG_ 832 VCFRONT_a408_standbyChargeProfil "Front body controller: a408 standby charge profile hard exit";
CM_ SG_ 832 VCFRONT_a409_invalidConfiguratio "Front body controller: a409 invalid configuration";
CM_ SG_ 832 VCFRONT_a410_LVBatteryDataCollec "Front body controller: a410 LV battery data collection1";
CM_ SG_ 832 VCFRONT_a411_LVBatteryDataCollec "Front body controller: a411 LV battery data collection2";
CM_ SG_ 832 VCFRONT_a412_dcrData3 "Front body controller: a412 dcr data3";
CM_ SG_ 832 VCFRONT_a413_TLVBMS_BmbVrefWarni "Front body controller: a413 TLVBMS bmb vref warning";
CM_ SG_ 832 VCFRONT_a414_prechargeLVLoadRedu "Front body controller: a414 precharge LV load reduction";
CM_ SG_ 832 VCFRONT_a415_prechargeLVLoadRedu "Front body controller: a415 precharge LV load reduction2";
CM_ SG_ 832 VCFRONT_a416_TLVBMS_BrickOverDis "Front body controller: a416 TLVBMS brick over discharged";
CM_ SG_ 832 VCFRONT_a417_TLVBMS_BrickOverVol "Front body controller: a417 TLVBMS brick over voltage fault";
CM_ SG_ 832 VCFRONT_a418_TLVBMS_BrickOverVol "Front body controller: a418 TLVBMS brick over voltage warning";
CM_ SG_ 832 VCFRONT_a419_TLVBMS_BrickSocLow "Front body controller: a419 TLVBMS brick soc low";
CM_ SG_ 832 VCFRONT_a420_holidayParty "Front body controller: a420 holiday party";
CM_ SG_ 832 VCFRONT_a421_leftHeadlampUartCon "Front body controller: a421 left headlamp uart condition";
CM_ SG_ 832 VCFRONT_a423_TLVBMS_BrickUnderVo "Front body controller: a423 TLVBMS brick under voltage fault";
CM_ SG_ 832 VCFRONT_a424_TLVBMS_BrickUnderVo "Front body controller: a424 TLVBMS brick under voltage ocv";
CM_ SG_ 832 VCFRONT_a425_TLVBMS_BusVoltageTo "Front body controller: a425 TLVBMS bus voltage too high";
CM_ SG_ 832 VCFRONT_a426_TLVBMS_BusVoltageTo "Front body controller: a426 TLVBMS bus voltage too low";
CM_ SG_ 832 VCFRONT_a427_TLVBMS_CacChange "Front body controller: a427 TLVBMS cac change";
CM_ SG_ 832 VCFRONT_a428_TLVBMS_CacImbalance "Front body controller: a428 TLVBMS cac imbalance";
CM_ SG_ 832 VCFRONT_a429_TLVBMS_CapacityTest "Front body controller: a429 TLVBMS capacity test results";
CM_ SG_ 832 VCFRONT_a430_TLVBMS_ChargeCurren "Front body controller: a430 TLVBMS charge current limit exceeded";
CM_ SG_ 832 VCFRONT_a431_TLVBMS_ChargeOverCu "Front body controller: a431 TLVBMS charge over current";
CM_ SG_ 832 VCFRONT_a432_TLVBMS_ChargeRegula "Front body controller: a432 TLVBMS charge regulation fault";
CM_ SG_ 832 VCFRONT_a433_TLVBMS_ConfigFromBm "Front body controller: a433 TLVBMS config from bmb mod id failed";
CM_ SG_ 832 VCFRONT_a434_TLVBMS_ConfigInitFa "Front body controller: a434 TLVBMS config init failed";
CM_ SG_ 832 VCFRONT_a435_TLVBMS_DchgCurrentL "Front body controller: a435 TLVBMS dchg current limit exceeded";
CM_ SG_ 832 VCFRONT_a436_TLVBMS_DischargeOve "Front body controller: a436 TLVBMS discharge over current";
CM_ SG_ 832 VCFRONT_a437_TLVBMS_NvmRegistrat "Front body controller: a437 TLVBMS nvm registration error";
CM_ SG_ 832 VCFRONT_a438_TLVBMS_PackOverTemp "Front body controller: a438 TLVBMS pack over temperature fault";
CM_ SG_ 832 VCFRONT_a439_TLVBMS_PackOverTemp "Front body controller: a439 TLVBMS pack over temperature warning";
CM_ SG_ 832 VCFRONT_a440_TLVBMS_PackSNInvali "Front body controller: a440 TLVBMS pack SN invalid for nvm";
CM_ SG_ 832 VCFRONT_a441_TLVBMS_ResetNeededF "Front body controller: a441 TLVBMS reset needed for nvm pack swap";
CM_ SG_ 832 VCFRONT_a442_TLVBMS_SocChange "Front body controller: a442 TLVBMS soc change";
CM_ SG_ 832 VCFRONT_a443_TLVBMS_BmbDieOverTe "Front body controller: a443 TLVBMS bmb die over temperature";
CM_ SG_ 832 VCFRONT_a444_drv8703Fault "Front body controller: a444 drv8703 fault";
CM_ SG_ 832 VCFRONT_a445_drv8703SpiFaultDBG "Front body controller: a445 drv8703 spi fault DBG";
CM_ SG_ 832 VCFRONT_a446_cabinHVACUnavailabl "Front body controller: a446 cabin HVAC unavailable context";
CM_ SG_ 832 VCFRONT_a447_cabinHVACUnavailabl "Front body controller: a447 cabin HVAC unavailable";
CM_ SG_ 832 VCFRONT_a448_gtwSteeringBtnReset "Front body controller: a448 gtw steering btn reset";
CM_ SG_ 832 VCFRONT_a449_hornSwitchStuckOn "Front body controller: a449 horn switch stuck on";
CM_ SG_ 832 VCFRONT_a450_hornSwitchNotPresse "Front body controller: a450 horn switch not pressed factory";
CM_ SG_ 832 VCFRONT_a451_refrigerantNotCommi "Front body controller: a451 refrigerant not commissioned";
CM_ SG_ 832 VCFRONT_a452_dischargePresSensIn "Front body controller: a452 discharge pres sens intermittent";
CM_ SG_ 832 VCFRONT_a453_dischargeTempSensIn "Front body controller: a453 discharge temp sens intermittent";
CM_ SG_ 832 VCFRONT_a454_suctionPresSensInte "Front body controller: a454 suction pres sens intermittent";
CM_ SG_ 832 VCFRONT_a455_suctionTempSensInte "Front body controller: a455 suction temp sens intermittent";
CM_ SG_ 832 VCFRONT_a456_liquidPresSensInter "Front body controller: a456 liquid pres sens intermittent";
CM_ SG_ 832 VCFRONT_a457_liquidTempSensInter "Front body controller: a457 liquid temp sens intermittent";
CM_ SG_ 832 VCFRONT_a458_grosslyLowRefrigera "Front body controller: a458 grossly low refrigerant";
CM_ SG_ 832 VCFRONT_a459_thermalFillAndDrive "Front body controller: a459 thermal fill and drive";
CM_ SG_ 832 VCFRONT_a460_hardIsentropicTdFai "Front body controller: a460 hard isentropic td failed";
CM_ SG_ 832 VCFRONT_a461_TLVBMS_SocHighAhErr "Front body controller: a461 TLVBMS soc high ah error";
CM_ SG_ 832 VCFRONT_a462_LVBMSFault "Front body controller: a462 LVBMS fault";
CM_ SG_ 832 VCFRONT_a463_frunkSensorService "Front body controller: a463 frunk sensor service";
CM_ SG_ 832 VCFRONT_a464_highFlowIndexHighSu "Front body controller: a464 high flow index high subcool flagged";
CM_ SG_ 832 VCFRONT_a465_lowFlowIndexHighSub "Front body controller: a465 low flow index high subcool flagged";
CM_ SG_ 832 VCFRONT_a466_highFlowIndexLowSub "Front body controller: a466 high flow index low subcool flagged";
CM_ SG_ 832 VCFRONT_a467_lowPowerIndexFlagge "Front body controller: a467 low power index flagged";
CM_ SG_ 832 VCFRONT_a468_highPowerIndexFlagg "Front body controller: a468 high power index flagged";
CM_ SG_ 832 VCFRONT_a469_prvPopDetected "Front body controller: a469 prv pop detected";
CM_ SG_ 832 VCFRONT_a470_implausiblePdPlDete "Front body controller: a470 implausible pd pl detected";
CM_ SG_ 832 VCFRONT_a471_hcm5Debug "Front body controller: a471 hcm5 debug";
CM_ SG_ 832 VCFRONT_a472_leftHeadlampRangeUp "Front body controller: a472 left headlamp range update";
CM_ SG_ 832 VCFRONT_a473_rightHeadlampRangeU "Front body controller: a473 right headlamp range update";
CM_ SG_ 832 VCFRONT_a474_leftHeadlampInterna "Front body controller: a474 left headlamp internal error";
CM_ SG_ 832 VCFRONT_a475_rightHeadlampIntern "Front body controller: a475 right headlamp internal error";
CM_ SG_ 832 VCFRONT_a476_LVBMSMIA "Front body controller: a476 LVBMSMIA";
CM_ SG_ 832 VCFRONT_a477_LVBatteryUnrecovera "Front body controller: a477 LV battery unrecoverable by vehicle";
CM_ SG_ 832 VCFRONT_a478_LVBMS_MOSFET_Open "Front body controller: a478 LVBMS MOSFET open";
CM_ SG_ 832 VCFRONT_a479_LVBMS_ECPA_NotClose "Front body controller: a479 LVBMS ECPA not closed";
CM_ SG_ 832 VCFRONT_a480_vnf1048Fault "Front body controller: a480 vnf1048 fault";
CM_ SG_ 832 VCFRONT_a481_vnf1048SelfTestFail "Front body controller: a481 vnf1048 self test failure";
CM_ SG_ 832 VCFRONT_a482_rightHeadlampMigrat "Front body controller: a482 right headlamp migration debug";
CM_ SG_ 832 VCFRONT_a483_leftHeadlampStepper "Front body controller: a483 left headlamp stepper motor fault";
CM_ SG_ 832 VCFRONT_a484_headlampLevelingRid "Front body controller: a484 headlamp leveling ride height debug";
CM_ SG_ 832 VCFRONT_a485_leftHeadlampMigrati "Front body controller: a485 left headlamp migration debug";
CM_ SG_ 832 VCFRONT_a486_mcuGraphicsEFuseFau "Front body controller: a486 mcu graphics e fuse fault";
CM_ SG_ 832 VCFRONT_a487_leftHeadlampLastPos "Front body controller: a487 left headlamp last position update";
CM_ SG_ 832 VCFRONT_a488_rightHeadlampSteppe "Front body controller: a488 right headlamp stepper motor fault";
CM_ SG_ 832 VCFRONT_a489_ValveStuckFlagged "Front body controller: a489 valve stuck flagged";
CM_ SG_ 832 VCFRONT_a490_coolantPumpsNotIden "Front body controller: a490 coolant pumps not identified";
CM_ SG_ 832 VCFRONT_a491_rightHeadlampLastPo "Front body controller: a491 right headlamp last position update";
CM_ SG_ 832 VCFRONT_a492_TLVBMS_SocImbalance "Front body controller: a492 TLVBMS soc imbalance";
CM_ SG_ 832 VCFRONT_a493_TLVBMS_SocImbalance "Front body controller: a493 TLVBMS soc imbalance warning";
CM_ SG_ 832 VCFRONT_a494_LVBatteryTempBlocki "Front body controller: a494 LV battery temp blocking OTA";
CM_ SG_ 832 VCFRONT_a495_LVBatteryRecoveryBl "Front body controller: a495 LV battery recovery blocked";
CM_ SG_ 832 VCFRONT_a496_LVBatteryExitDriveW "Front body controller: a496 LV battery exit drive warning";
CM_ SG_ 832 VCFRONT_a497_LVBatteryWarnDiscon "Front body controller: a497 LV battery warn disconnect";
CM_ SG_ 832 VCFRONT_a498_TLVBMS_ImpedanceTes "Front body controller: a498 TLVBMS impedance test results";
CM_ SG_ 832 VCFRONT_a499_loadShedPumpFlowReq "Front body controller: a499 load shed pump flow request";
CM_ SG_ 832 VCFRONT_a500_eFuseASICStateMisma "Front body controller: a500 e fuse ASIC state mismatch";
CM_ SG_ 832 VCFRONT_a501_vnf1048Configuratio "Front body controller: a501 vnf1048 configuration mismatch";
CM_ SG_ 832 VCFRONT_a502_TLVBMS_WeakShortImp "Front body controller: a502 TLVBMS weak short impedance";
CM_ SG_ 832 VCFRONT_a503_TLVBMS_BrickExtende "Front body controller: a503 TLVBMS brick extended ov fault";
CM_ SG_ 832 VCFRONT_a504_airInRefrigerantDet "Front body controller: a504 air in refrigerant detected";
CM_ SG_ 832 VCFRONT_a505_BLEFrontUnderVoltag "Front body controller: a505 BLE front under voltage";
CM_ SG_ 832 VCFRONT_a506_invalidRefrigerantS "Front body controller: a506 invalid refrigerant system config";
CM_ SG_ 832 VCFRONT_a507_leftHeadlampAimingF "Front body controller: a507 left headlamp aiming fault";
CM_ SG_ 832 VCFRONT_a508_TLVBMS_ImpedanceGro "Front body controller: a508 TLVBMS impedance growth";
CM_ SG_ 832 VCFRONT_a509_vcrightEFuseLoadShe "Front body controller: a509 vcright e fuse load shed";
CM_ SG_ 832 VCFRONT_a510_LVBatteryRecoveryTi "Front body controller: a510 LV battery recovery timeout";
CM_ SG_ 832 VCFRONT_a511_DCDCSaturationLoadS "Front body controller: a511 DCDC saturation load shed";
CM_ SG_ 832 VCFRONT_a512_LVBMSFault_MOS_Open "Front body controller: a512 LVBMS fault MOS open hardware OC";
CM_ SG_ 832 VCFRONT_a513_LVBMSFault_MOS_Open "Front body controller: a513 LVBMS fault MOS open chg OC";
CM_ SG_ 832 VCFRONT_a514_LVBMSFault_MOS_Open "Front body controller: a514 LVBMS fault MOS open cell UV";
CM_ SG_ 832 VCFRONT_a515_LVBMSFault_MOS_Open "Front body controller: a515 LVBMS fault MOS open cell OV";
CM_ SG_ 832 VCFRONT_a516_hibernationActive "Front body controller: a516 hibernation active";
CM_ SG_ 832 VCFRONT_a517_hibernationRecovery "Front body controller: a517 hibernation recovery";
CM_ SG_ 832 VCFRONT_a518_LVBMSFault_MOS_Open "Front body controller: a518 LVBMS fault MOS open pack OV";
CM_ SG_ 832 VCFRONT_a519_leftHeadlampInterna "Front body controller: a519 left headlamp internal error V2";
CM_ SG_ 832 VCFRONT_a520_rightHeadlampIntern "Front body controller: a520 right headlamp internal error V2";
CM_ SG_ 832 VCFRONT_a521_vcleftEFuseLoadShed "Front body controller: a521 vcleft e fuse load shed";
CM_ SG_ 832 VCFRONT_a522_hibernationActiveLo "Front body controller: a522 hibernation active log capture";
CM_ SG_ 832 VCFRONT_a523_eFuseThresholdsInco "Front body controller: a523 e fuse thresholds incorrect";
CM_ SG_ 832 VCFRONT_a524_rightHeadlampAiming "Front body controller: a524 right headlamp aiming fault";
CM_ SG_ 832 VCFRONT_a525_LVBatterySWMisconfi "Front body controller: a525 LV battery SW misconfiguration";
CM_ SG_ 832 VCFRONT_a526_pcbaOverTemperature "Front body controller: a526 pcba over temperature";
CM_ SG_ 832 VCFRONT_a527_LVBatteryCellImbala "Front body controller: a527 LV battery cell imbalance";
CM_ SG_ 832 VCFRONT_a528_LVBatteryCommsDiscn "Front body controller: a528 LV battery comms discnctd";
CM_ SG_ 832 VCFRONT_a529_discnctdBatteryStat "Front body controller: a529 discnctd battery state unknown";
CM_ SG_ 832 VCFRONT_a530_sharpCurrentRise "Front body controller: a530 sharp current rise";
CM_ SG_ 832 VCFRONT_a531_lowPowerIndexFlagge "Front body controller: a531 low power index flagged user facing";
CM_ SG_ 832 VCFRONT_a532_gtwMIAInDrive "Front body controller: a532 gtw MIA in drive";
CM_ SG_ 832 VCFRONT_a533_TLVBMS_MosfetOverTe "Front body controller: a533 TLVBMS mosfet over temperature fault";
CM_ SG_ 832 VCFRONT_a534_chillerExvCalibInit "Front body controller: a534 chiller exv calib init debug";
CM_ SG_ 832 VCFRONT_a535_evapExvCalibInitDeb "Front body controller: a535 evap exv calib init debug";
CM_ SG_ 832 VCFRONT_a536_recircExvCalibInitD "Front body controller: a536 recirc exv calib init debug";
CM_ SG_ 832 VCFRONT_a537_lccExvCalibInitDebu "Front body controller: a537 lcc exv calib init debug";
CM_ SG_ 832 VCFRONT_a538_cclExvCalibInitDebu "Front body controller: a538 ccl exv calib init debug";
CM_ SG_ 832 VCFRONT_a539_ccrExvCalibInitDebu "Front body controller: a539 ccr exv calib init debug";
CM_ SG_ 832 VCFRONT_a540_radiatorSteamDetect "Front body controller: a540 radiator steam detected";
CM_ SG_ 832 VCFRONT_a541_LVBatteryChargeOCLe "Front body controller: a541 LV battery charge OC level1";
CM_ SG_ 832 VCFRONT_a542_refrigerantReclaim "Front body controller: a542 refrigerant reclaim";
CM_ SG_ 832 VCFRONT_a543_compressorLowFlowDe "Front body controller: a543 compressor low flow delivery detected";
CM_ SG_ 832 VCFRONT_a544_LVBatteryCommsBusTu "Front body controller: a544 LV battery comms bus turned off";
CM_ SG_ 832 VCFRONT_a545_LVBatteryTypeUnknow "Front body controller: a545 LV battery type unknown";
CM_ SG_ 832 VCFRONT_a546_leftLowOrHighBeamLi "Front body controller: a546 left low or high beam light condition";
CM_ SG_ 832 VCFRONT_a547_postCrashLoadShed "Front body controller: a547 post crash load shed";
CM_ SG_ 832 VCFRONT_a548_HVFaultLoadShed "Front body controller: a548 HV fault load shed";
CM_ SG_ 832 VCFRONT_a549_leftHeadlampInterna "Front body controller: a549 left headlamp internal error V3";
CM_ SG_ 832 VCFRONT_a550_ambientTempDelta "Front body controller: a550 ambient temp delta";
CM_ SG_ 832 VCFRONT_a551_leftHeadlampSoftSho "Front body controller: a551 left headlamp soft short";
CM_ SG_ 832 VCFRONT_a552_eFuseSelfTestFailur "Front body controller: a552 e fuse self test failure";
CM_ SG_ 832 VCFRONT_a553_rightHeadlampSoftSh "Front body controller: a553 right headlamp soft short";
CM_ SG_ 832 VCFRONT_a555_LVBatteryCellRebala "Front body controller: a555 LV battery cell rebalancing";
CM_ SG_ 832 VCFRONT_a556_falseTriggerOfDiscn "Front body controller: a556 false trigger of discnctd battery test";
CM_ SG_ 832 VCFRONT_a557_rightHeadlampIntern "Front body controller: a557 right headlamp internal error V3";
CM_ SG_ 832 VCFRONT_a558_rightHeadlampAiming "Front body controller: a558 right headlamp aiming debug";
CM_ SG_ 832 VCFRONT_a559_LVBatteryLowSOC "Front body controller: a559 LV battery low SOC";
CM_ SG_ 832 VCFRONT_a560_compressorHighSuper "Front body controller: a560 compressor high superheat";
CM_ SG_ 832 VCFRONT_a561_LVBMSEFuseOvertempe "Front body controller: a561 LVBMSE fuse overtemperature";
CM_ SG_ 832 VCFRONT_a562_LVBMSModuleOvertemp "Front body controller: a562 LVBMS module overtemperature";
CM_ SG_ 832 VCFRONT_a563_chargePortDoorOpenB "Front body controller: a563 charge port door open blocked by brake";
CM_ SG_ 832 VCFRONT_a564_leftHeadlampAimingD "Front body controller: a564 left headlamp aiming debug";
CM_ SG_ 832 VCFRONT_a565_userPresenceDisplay "Front body controller: a565 user presence display state mismatch";
CM_ SG_ 832 VCFRONT_a566_leftFrontTurnLightF "Front body controller: a566 left front turn light fault";
CM_ SG_ 832 VCFRONT_a567_rightFrontTurnLight "Front body controller: a567 right front turn light fault";
CM_ SG_ 832 VCFRONT_a568_leftDaytimeRunningL "Front body controller: a568 left daytime running light fault";
CM_ SG_ 832 VCFRONT_a569_rightDaytimeRunning "Front body controller: a569 right daytime running light fault";
CM_ SG_ 832 VCFRONT_a570_headlampsAdaptedToL "Front body controller: a570 headlamps adapted to left hand traffic";
CM_ SG_ 832 VCFRONT_a571_headlampsAdaptedToR "Front body controller: a571 headlamps adapted to right hand traffic";
CM_ SG_ 832 VCFRONT_a572_hvacCompressorEFuse "Front body controller: a572 hvac compressor e fuse trip";
CM_ SG_ 832 VCFRONT_a573_radarEFuseTrip "Front body controller: a573 radar e fuse trip";
CM_ SG_ 832 VCFRONT_a574_frontDriveInverterE "Front body controller: a574 front drive inverter e fuse trip";
CM_ SG_ 832 VCFRONT_a575_frontOilPumpEFuseTr "Front body controller: a575 front oil pump e fuse trip";
CM_ SG_ 832 VCFRONT_a576_mcuLogicEFuseTrip "Front body controller: a576 mcu logic e fuse trip";
CM_ SG_ 832 VCFRONT_a577_tasEFuseTrip "Front body controller: a577 tas e fuse trip";
CM_ SG_ 832 VCFRONT_a578_vbatFusedLowCurrent "Front body controller: a578 vbat fused low current feed e fuse trip";
CM_ SG_ 832 VCFRONT_a579_leftHeadlightEFuseT "Front body controller: a579 left headlight e fuse trip";
CM_ SG_ 832 VCFRONT_a580_rightHeadlightEFuse "Front body controller: a580 right headlight e fuse trip";
CM_ SG_ 832 VCFRONT_a581_windshieldWiperEFus "Front body controller: a581 windshield wiper e fuse trip";
CM_ SG_ 832 VCFRONT_a582_goodForPCSPowerCycl "Front body controller: a582 good for PCS power cycle";
CM_ SG_ 832 VCFRONT_a583_frunkSwitchGroupDis "Front body controller: a583 frunk switch group disagreement debug";
CM_ SG_ 832 VCFRONT_a584_frunkSwitchGroupDeb "Front body controller: a584 frunk switch group debug";
CM_ SG_ 832 VCFRONT_a585_bothHeadlampsIntern "Front body controller: a585 both headlamps internal error";
CM_ SG_ 832 VCFRONT_a586_rightLowOrHighBeamL "Front body controller: a586 right low or high beam light condition";
CM_ SG_ 832 VCFRONT_a587_externalLVPowerSupp "Front body controller: a587 external LV power supply";
CM_ SG_ 832 VCFRONT_a588_vcleftPwrRationalit "Front body controller: a588 vcleft pwr rationality curve";
CM_ SG_ 832 VCFRONT_a589_vcleftFastBlowDetec "Front body controller: a589 vcleft fast blow detection";
CM_ SG_ 832 VCFRONT_a590_vcrightPwrRationali "Front body controller: a590 vcright pwr rationality curve";
CM_ SG_ 832 VCFRONT_a591_vcrightFastBlowDete "Front body controller: a591 vcright fast blow detection";
CM_ SG_ 832 VCFRONT_a592_vcleftCurvePowerCut "Front body controller: a592 vcleft curve power cutoff";
CM_ SG_ 832 VCFRONT_a593_vcleftFastBlowPower "Front body controller: a593 vcleft fast blow power cutoff";
CM_ SG_ 832 VCFRONT_a594_virtualPitchConvers "Front body controller: a594 virtual pitch conversion debug";
CM_ SG_ 832 VCFRONT_a595_voltageSensorMismat "Front body controller: a595 voltage sensor mismatch";
CM_ SG_ 832 VCFRONT_a596_vcrightCurvePowerCu "Front body controller: a596 vcright curve power cutoff";
CM_ SG_ 832 VCFRONT_a597_vcrightFastBlowPowe "Front body controller: a597 vcright fast blow power cutoff";
CM_ SG_ 832 VCFRONT_a598_eFuseSelfTestFailur "Front body controller: a598 e fuse self test failure service";
CM_ SG_ 832 VCFRONT_a599_LVBatteryTypeUnsupp "Front body controller: a599 LV battery type unsupported";
CM_ SG_ 832 VCFRONT_a600_currentSensorMismat "Front body controller: a600 current sensor mismatch";
CM_ SG_ 832 VCFRONT_a601_autopilotAirPurgeLi "Front body controller: a601 autopilot air purge limit reached";
CM_ SG_ 832 VCFRONT_a602_unknownTurnIndicato "Front body controller: a602 unknown turn indicator config";
CM_ SG_ 832 VCFRONT_a603_unexpectedTurnIndic "Front body controller: a603 unexpected turn indicator config change";
CM_ SG_ 832 VCFRONT_a604_turnIndicatorConfig "Front body controller: a604 turn indicator config input mismatch";
CM_ SG_ 832 VCFRONT_a605_sleepBypassPowerOff "Front body controller: a605 sleep bypass power off";
CM_ SG_ 832 VCFRONT_a606_chillerBattHeatingE "Front body controller: a606 chiller batt heating exit";
CM_ SG_ 832 VCFRONT_a607_sleepPowerDebug "Front body controller: a607 sleep power debug";
CM_ SG_ 832 VCFRONT_a608_TLVBMS_BleedFetFail "Front body controller: a608 TLVBMS bleed fet failure";
CM_ SG_ 832 VCFRONT_a609_autopilotDriveNotAu "Front body controller: a609 autopilot drive not authed";
CM_ SG_ 832 VCFRONT_a610_frunkOpenFailureMet "Front body controller: a610 frunk open failure metric set";
CM_ SG_ 832 VCFRONT_a611_poorRadiatorHeatRej "Front body controller: a611 poor radiator heat rejection";
CM_ SG_ 832 VCFRONT_a612_LVUnhealthyLoadShed "Front body controller: a612 LV unhealthy load shed";
CM_ SG_ 832 VCFRONT_a613_selfTestsBlockingDr "Front body controller: a613 self tests blocking drive";
CM_ SG_ 832 VCFRONT_a614_coolantSysDriverles "Front body controller: a614 coolant sys driverless self test";
CM_ SG_ 832 VCFRONT_a615_TLVBMS_BatteryHeate "Front body controller: a615 TLVBMS battery heater fault";
CM_ SG_ 832 VCFRONT_a616_VCSEAT2L_MIA "Front body controller: a616 VCSEAT2 l MIA";
CM_ SG_ 832 VCFRONT_a617_VCSEAT2R_MIA "Front body controller: a617 VCSEAT2 r MIA";
CM_ SG_ 832 VCFRONT_a618_cabinCoolingCapacit "Front body controller: a618 cabin cooling capacity limited";
CM_ SG_ 832 VCFRONT_a619_frunkSwitchReleaseT "Front body controller: a619 frunk switch release time DBG";
CM_ SG_ 832 VCFRONT_a620_pumpAirLock "Front body controller: a620 pump air lock";
CM_ SG_ 832 VCFRONT_a621_coolantAirPurgeInco "Front body controller: a621 coolant air purge incomplete";
CM_ SG_ 832 VCFRONT_a622_pumpDetectsLowCoola "Front body controller: a622 pump detects low coolant flow";
CM_ SG_ 832 VCFRONT_a623_LVUnhealthy "Front body controller: a623 LV unhealthy";
CM_ SG_ 832 VCFRONT_a624_rightHeadlampIntern "Front body controller: a624 right headlamp internal error V4";
CM_ SG_ 832 VCFRONT_a625_leftHeadlampInterna "Front body controller: a625 left headlamp internal error V4";
CM_ SG_ 832 VCFRONT_a626_LVBatteryResistance "Front body controller: a626 LV battery resistance increase";
CM_ SG_ 832 VCFRONT_a627_LVBatteryUnrecovera "Front body controller: a627 LV battery unrecoverable by any device";
CM_ SG_ 832 VCFRONT_a628_TLVBMS_BmbThermisto "Front body controller: a628 TLVBMS bmb thermistor fault";
CM_ SG_ 832 VCFRONT_a629_TLVBMS_PackTemperat "Front body controller: a629 TLVBMS pack temperature irrational";
CM_ SG_ 832 VCFRONT_a630_leftHeadlampFactory "Front body controller: a630 left headlamp factory fault";
CM_ SG_ 832 VCFRONT_a631_rightHeadlampFactor "Front body controller: a631 right headlamp factory fault";
CM_ SG_ 832 VCFRONT_a634_indeterminateSwitch "Front body controller: a634 indeterminate switch transition detected dbg";
CM_ SG_ 832 VCFRONT_a635_rtosSleepFailed "Front body controller: a635 rtos sleep failed";
CM_ SG_ 832 VCFRONT_d636_ptCoolantPumpDetect "Front body controller: d636 pt coolant pump detects air in system";
CM_ SG_ 832 VCFRONT_d637_battCoolantPumpDete "Front body controller: d637 batt coolant pump detects air in system";
CM_ SG_ 832 VCFRONT_d638_ptCoolantTempSensor "Front body controller: d638 pt coolant temp sensor issue";
CM_ SG_ 832 VCFRONT_d639_batteryCoolantTempS "Front body controller: d639 battery coolant temp sensor issue";
CM_ SG_ 832 VCFRONT_d640_firmwareVersionMism "Front body controller: d640 firmware version mismatch";
CM_ SG_ 832 VCFRONT_d641_ptCoolantPumpCircui "Front body controller: d641 pt coolant pump circuit open";
CM_ SG_ 832 VCFRONT_d642_batteryCoolantPumpC "Front body controller: d642 battery coolant pump circuit open";
CM_ SG_ 832 VCFRONT_a643_rightHeadlampUartCo "Front body controller: a643 right headlamp uart condition";
CM_ SG_ 832 VCFRONT_a644_washPumpHealthCalcu "Front body controller: a644 wash pump health calculation dbg0";
CM_ SG_ 832 VCFRONT_a645_washPumpHealthCalcu "Front body controller: a645 wash pump health calculation dbg1";
CM_ SG_ 832 VCFRONT_a646_washPumpHealthCalcu "Front body controller: a646 wash pump health calculation dbg2";
CM_ SG_ 832 VCFRONT_d647_louverCommLost "Front body controller: d647 louver comm lost";
CM_ SG_ 832 VCFRONT_d648_louverBlocked "Front body controller: d648 louver blocked";
CM_ SG_ 832 VCFRONT_a649_persistAccPortPower "Front body controller: a649 persist acc port power req overridden";
CM_ SG_ 832 VCFRONT_d650_lowCoolantLevel "Front body controller: d650 low coolant level";
CM_ SG_ 832 VCFRONT_d651_ptCoolantPumpStall "Front body controller: d651 pt coolant pump stall";
CM_ SG_ 832 VCFRONT_d652_ptCoolantPumpCircui "Front body controller: d652 pt coolant pump circuit issue";
CM_ SG_ 832 VCFRONT_d653_ptCoolantPumpCommLo "Front body controller: d653 pt coolant pump comm lost";
CM_ SG_ 832 VCFRONT_d654_batteryCoolantPumpS "Front body controller: d654 battery coolant pump stall";
CM_ SG_ 832 VCFRONT_d655_batteryCoolantPumpC "Front body controller: d655 battery coolant pump circuit issue";
CM_ SG_ 832 VCFRONT_d656_batteryCoolantPumpC "Front body controller: d656 battery coolant pump comm lost";
CM_ SG_ 832 VCFRONT_d657_radiatorFanOperatio "Front body controller: d657 radiator fan operation issue";
CM_ SG_ 832 VCFRONT_d658_radiatorFanCircuitI "Front body controller: d658 radiator fan circuit issue";
CM_ SG_ 832 VCFRONT_d659_radiatorFanCommLost "Front body controller: d659 radiator fan comm lost";
CM_ SG_ 832 VCFRONT_d660_coolantValveCircuit "Front body controller: d660 coolant valve circuit issue";
CM_ SG_ 832 VCFRONT_a661_mculessLeftHeadlamp "Front body controller: a661 mculess left headlamp current alert dbg";
CM_ SG_ 832 VCFRONT_a662_mculessRightHeadlam "Front body controller: a662 mculess right headlamp current alert dbg";
CM_ SG_ 832 VCFRONT_a663_leftHeadlampUartWat "Front body controller: a663 left headlamp uart water mark warning";
CM_ SG_ 832 VCFRONT_a664_rightHeadlampUartWa "Front body controller: a664 right headlamp uart water mark warning";
CM_ SG_ 832 VCFRONT_a665_leftHeadlampRetryIn "Front body controller: a665 left headlamp retry info";
CM_ SG_ 832 VCFRONT_a666_rightHeadlampRetryI "Front body controller: a666 right headlamp retry info";
CM_ SG_ 832 VCFRONT_a667_leftHeadlampRegionO "Front body controller: a667 left headlamp region or side mismatch";
CM_ SG_ 832 VCFRONT_a668_rightHeadlampRegion "Front body controller: a668 right headlamp region or side mismatch";
CM_ SG_ 832 VCFRONT_a669_thermalHVPowerBudge "Front body controller: a669 thermal HV power budget active";
CM_ SG_ 832 VCFRONT_a670_TLVBMS_EfuseStateIr "Front body controller: a670 TLVBMS efuse state irrational";
CM_ SG_ 832 VCFRONT_a671_powerConsumptionInf "Front body controller: a671 power consumption info";
CM_ SG_ 832 VCFRONT_a672_LVBatteryVitals "Front body controller: a672 LV battery vitals";
CM_ SG_ 832 VCFRONT_d674_portExpanderService "Front body controller: d674 port expander service required";
CM_ SG_ 832 VCFRONT_a675_doorWakeToOpenDBG "Front body controller: a675 door wake to open DBG";
CM_ SG_ 832 VCFRONT_a697_leftHeadlampNotAime "Front body controller: a697 left headlamp not aimed";
CM_ SG_ 832 VCFRONT_a698_rightHeadlampNotAim "Front body controller: a698 right headlamp not aimed";
CM_ SG_ 832 VCFRONT_a702_dynamicHeadlightLev "Front body controller: a702 dynamic headlight leveling unavailable";
CM_ BO_ 577 "Front body controller message: coolant";
CM_ SG_ 577 VCFRONT_coolantFlowBatActual "Front body controller: coolant flow bat actual";
CM_ SG_ 577 VCFRONT_coolantFlowBatTarget "Front body controller: coolant flow bat target";
CM_ SG_ 577 VCFRONT_coolantFlowBatReason "Front body controller: coolant flow bat reason";
CM_ SG_ 577 VCFRONT_coolantFlowPTActual "Front body controller: coolant flow PT actual";
CM_ SG_ 577 VCFRONT_coolantFlowPTTarget "Front body controller: coolant flow PT target";
CM_ SG_ 577 VCFRONT_coolantFlowPTReason "Front body controller: coolant flow PT reason";
CM_ SG_ 577 VCFRONT_wasteHeatRequestType "Front body controller: waste heat request type";
CM_ SG_ 577 VCFRONT_coolantHasBeenFilled "Front body controller: coolant has been filled";
CM_ SG_ 577 VCFRONT_radiatorIneffective "Indication that the efficiency of the radiator is reduced";
CM_ SG_ 577 VCFRONT_coolantAirPurgeBatState "Front body controller: coolant air purge bat state";
CM_ SG_ 577 VCFRONT_coolantFlowTableConfig "Front body controller: coolant flow table config";
CM_ SG_ 577 VCFRONT_coolantLevelContinuously "Front body controller: coolant level continuously low";
CM_ BO_ 753 "Front body controller message: e fuse debug status";
CM_ SG_ 753 VCFRONT_eFuseDebugStatusIndex "Front body controller: e fuse debug status index";
CM_ SG_ 753 VCFRONT_leftControllerState "Front body controller: left controller state";
CM_ SG_ 753 VCFRONT_leftControllerFault "Front body controller: left controller fault";
CM_ SG_ 753 VCFRONT_vcleftSelfTestResult "Reports the result of the most recent self-test of the Vehicle Controller Left (VCLEFT) eFuse.";
CM_ SG_ 753 VCFRONT_leftControllerTemp "Front body controller: left controller temp";
CM_ SG_ 753 VCFRONT_leftControllerEFuseVNFSt "State of the leftController eFuse";
CM_ SG_ 753 VCFRONT_leftControllerEFuseOutpu "Output state of the leftController efuse";
CM_ SG_ 753 VCFRONT_leftControllerEFuse_0002 "Output of the leftController efuse";
CM_ SG_ 753 VCFRONT_leftControllerVoltage "Front body controller: left controller voltage";
CM_ SG_ 753 VCFRONT_leftControllerEFuseBypas "Bypass output state of the leftController efuse";
CM_ SG_ 753 VCFRONT_leftControllerEFuse_0001 "Bypass output of the leftController efuse";
CM_ SG_ 753 VCFRONT_leftControllerCurrent "Front body controller: left controller current";
CM_ SG_ 753 VCFRONT_leftControllerEFuseVNFSe "Front body controller: left controller e fuse VNF self test status";
CM_ SG_ 753 VCFRONT_PCSState "Front body controller: PCS state";
CM_ SG_ 753 VCFRONT_PCSFault "Front body controller: PCS fault";
CM_ SG_ 753 VCFRONT_pcsSelfTestResult "Reports the result of the most recent self-test of the Power Conversion System (PCS) eFuse.";
CM_ SG_ 753 VCFRONT_PCSTemp "Front body controller: PCS temp";
CM_ SG_ 753 VCFRONT_PCSEFuseVNFState "State of the PCS eFuse";
CM_ SG_ 753 VCFRONT_PCSEFuseOutput "Output state of the PCS efuse";
CM_ SG_ 753 VCFRONT_PCSEFuseOutputDesired "Output of the PCS efuse";
CM_ SG_ 753 VCFRONT_PCSVoltage "Voltage of the power conversion system circuit";
CM_ SG_ 753 VCFRONT_PCSEFuseBypass "Bypass output state of the PCS efuse";
CM_ SG_ 753 VCFRONT_PCSEFuseBypassDesired "Bypass output of the PCS efuse";
CM_ SG_ 753 VCFRONT_PCSEFuseVNFSelfTestStatu "Front body controller: PCSE fuse VNF self test status";
CM_ SG_ 753 VCFRONT_iBoosterState "Front body controller: i booster state";
CM_ SG_ 753 VCFRONT_iBoosterFault "Front body controller: i booster fault";
CM_ SG_ 753 VCFRONT_iBoosterSelfTestResult "Reports the result of the most recent self-test of the iBooster eFuse.";
CM_ SG_ 753 VCFRONT_iBoosterTemp "Front body controller: i booster temp";
CM_ SG_ 753 VCFRONT_iBoosterEFuseVNFState "State of the IBooster eFuse";
CM_ SG_ 753 VCFRONT_iBoosterEFuseOutput "Output state of the IBooster efuse";
CM_ SG_ 753 VCFRONT_iBoosterEFuseOutputDesir "Output of the IBooster efuse";
CM_ SG_ 753 VCFRONT_iBoosterVoltage "Front body controller: i booster voltage";
CM_ SG_ 753 VCFRONT_iBoosterHardshortThresho "Front body controller: i booster hardshort threshold dbg";
CM_ SG_ 753 VCFRONT_iBoosterEFuseBypass "Bypass output state of the IBooster efuse";
CM_ SG_ 753 VCFRONT_iBoosterEFuseBypassDesir "Bypass output of the IBooster efuse";
CM_ SG_ 753 VCFRONT_iBoosterCurrent "Front body controller: i booster current";
CM_ SG_ 753 VCFRONT_iBoosterEFuseVNFSelfTest "Front body controller: i booster e fuse VNF self test status";
CM_ SG_ 753 VCFRONT_EPAS3PState "State of the primary power steering circuit";
CM_ SG_ 753 VCFRONT_EPAS3PFault "Front body controller: EPAS3 p fault";
CM_ SG_ 753 VCFRONT_EPAS3PSelfTestResult "Reports the result of the most recent self-test of the Electric Power Assisted Steering Primary (EPAS3P) eFuse.";
CM_ SG_ 753 VCFRONT_EPAS3PTemp "Front body controller: EPAS3 p temp";
CM_ SG_ 753 VCFRONT_EPAS3PEFuseVNFState "State of the EPAS3P eFuse";
CM_ SG_ 753 VCFRONT_EPAS3PEFuseOutput "Output state of the EPAS3P efuse";
CM_ SG_ 753 VCFRONT_EPAS3PEFuseOutputDesired "Output of the EPAS3P efuse";
CM_ SG_ 753 VCFRONT_EPAS3PVoltage "Voltage of the primary power steering circuit";
CM_ SG_ 753 VCFRONT_EPAS3PEFuseHardshortThre "Front body controller: EPAS3 PE fuse hardshort threshold dbg";
CM_ SG_ 753 VCFRONT_EPAS3PEFuseBypass "Bypass output state of the EPAS3P efuse";
CM_ SG_ 753 VCFRONT_EPAS3PEFuseBypassDesired "Bypass output of the EPAS3P efuse";
CM_ SG_ 753 VCFRONT_EPAS3PCurrent "Electrical current of the primary power steering circuit";
CM_ SG_ 753 VCFRONT_EPAS3PEFuseVNFSelfTestSt "Front body controller: EPAS3 PE fuse VNF self test status";
CM_ SG_ 753 VCFRONT_EPAS3SState "State of the secondary power steering circuit";
CM_ SG_ 753 VCFRONT_EPAS3SFault "Front body controller: EPAS3 s fault";
CM_ SG_ 753 VCFRONT_EPAS3SSelfTestResult "Reports the result of the most recent self-test of the Electric Power Assisted Steering Secondary (EPAS3S) eFuse.";
CM_ SG_ 753 VCFRONT_EPAS3STemp "Front body controller: EPAS3 s temp";
CM_ SG_ 753 VCFRONT_EPAS3SEFuseVNFState "State of the EPAS3S eFuse";
CM_ SG_ 753 VCFRONT_EPAS3SEFuseOutput "Output state of the EPAS3S efuse";
CM_ SG_ 753 VCFRONT_EPAS3SEFuseOutputDesired "Output of the EPAS3S efuse";
CM_ SG_ 753 VCFRONT_EPAS3SVoltage "Voltage of the secondary power steering circuit";
CM_ SG_ 753 VCFRONT_EPAS3SEFuseBypass "Bypass output state of the EPAS3S efuse";
CM_ SG_ 753 VCFRONT_EPAS3SEFuseBypassDesired "Bypass output of the EPAS3S efuse";
CM_ SG_ 753 VCFRONT_EPAS3SCurrent "Electrical current of the secondary power steering circuit";
CM_ SG_ 753 VCFRONT_EPAS3SEFuseVNFSelfTestSt "Front body controller: EPAS3 SE fuse VNF self test status";
CM_ SG_ 753 VCFRONT_ESPMotorState "Front body controller: ESP motor state";
CM_ SG_ 753 VCFRONT_ESPMotorFault "Front body controller: ESP motor fault";
CM_ SG_ 753 VCFRONT_ESPMotorSelfTestResult "Reports the result of the most recent self-test of the Electronic Stability Program Motor (ESP Motor) eFuse.";
CM_ SG_ 753 VCFRONT_ESPMotorTemp "Front body controller: ESP motor temp";
CM_ SG_ 753 VCFRONT_ESPMotorEFuseVNFState "State of the ESPMotor eFuse";
CM_ SG_ 753 VCFRONT_ESPMotorEFuseOutput "Output state of the ESPMotor efuse";
CM_ SG_ 753 VCFRONT_ESPMotorEFuseOutputDesir "Output of the ESPMotor efuse";
CM_ SG_ 753 VCFRONT_ESPMotorVoltage "Front body controller: ESP motor voltage";
CM_ SG_ 753 VCFRONT_ESPMotorEFuseBypass "Bypass output state of the ESPMotor efuse";
CM_ SG_ 753 VCFRONT_ESPMotorEFuseBypassDesir "Bypass output of the ESPMotor efuse";
CM_ SG_ 753 VCFRONT_ESPMotorCurrent "Front body controller: ESP motor current";
CM_ SG_ 753 VCFRONT_ESPMotorEFuseVNFSelfTest "Front body controller: ESP motor e fuse VNF self test status";
CM_ SG_ 753 VCFRONT_ESPValveState "State of the stability controller motor circuit";
CM_ SG_ 753 VCFRONT_ESPValveFault "Front body controller: ESP valve fault";
CM_ SG_ 753 VCFRONT_ESPValveTemp "Front body controller: ESP valve temp";
CM_ SG_ 753 VCFRONT_ESPValveVoltage "Front body controller: ESP valve voltage";
CM_ SG_ 753 VCFRONT_ESPValveCurrent "Electrical current of the stability controller motor circuit";
CM_ SG_ 753 VCFRONT_autopilot2State "Front body controller: autopilot2 state";
CM_ SG_ 753 VCFRONT_autopilot2Fault "Front body controller: autopilot2 fault";
CM_ SG_ 753 VCFRONT_autopilot2Temp "Front body controller: autopilot2 temp";
CM_ SG_ 753 VCFRONT_autopilot2Voltage "Front body controller: autopilot2 voltage";
CM_ SG_ 753 VCFRONT_autopilot2Current "Front body controller: autopilot2 current";
CM_ SG_ 753 VCFRONT_sleepBypassState "State of the sleep bypass circuit";
CM_ SG_ 753 VCFRONT_sleepBypassFault "Front body controller: sleep bypass fault";
CM_ SG_ 753 VCFRONT_sleepBypassVoltage "Front body controller: sleep bypass voltage";
CM_ SG_ 753 VCFRONT_sleepBypassCurrent "Front body controller: sleep bypass current";
CM_ SG_ 753 VCFRONT_vbatFusedHighState "Front body controller: vbat fused high state";
CM_ SG_ 753 VCFRONT_vbatFusedHighFault "Front body controller: vbat fused high fault";
CM_ SG_ 753 VCFRONT_vbatFusedSelfTestResult "Front body controller: vbat fused self test result";
CM_ SG_ 753 VCFRONT_vbatFusedHighTemp "Front body controller: vbat fused high temp";
CM_ SG_ 753 VCFRONT_vbatFusedHighVoltage "Front body controller: vbat fused high voltage";
CM_ SG_ 753 VCFRONT_vbatFusedHighCurrent "Front body controller: vbat fused high current";
CM_ SG_ 753 VCFRONT_chargedIBSAmpHours "Front body controller: charged IBS amp hours";
CM_ SG_ 753 VCFRONT_dischargedIBSAmpHours "Front body controller: discharged IBS amp hours";
CM_ SG_ 753 VCFRONT_IBSUnfilteredTemperature "Front body controller: IBS unfiltered temperature";
CM_ BO_ 2016 "Front body controller message: homelink";
CM_ SG_ 2016 VCFRONT_homelinkV2Response0 "Front body controller: homelink V2 response0";
CM_ SG_ 2016 VCFRONT_homelinkV2Response1 "Front body controller: homelink V2 response1";
CM_ SG_ 2016 VCFRONT_homelinkV2Response2 "Front body controller: homelink V2 response2";
CM_ SG_ 2016 VCFRONT_homelinkV2Response3 "Front body controller: homelink V2 response3";
CM_ SG_ 2016 VCFRONT_homelinkV2Response4 "Front body controller: homelink V2 response4";
CM_ SG_ 2016 VCFRONT_homelinkCommStatus "Homelink communication status";
CM_ BO_ 769 "Front body controller message: info";
CM_ SG_ 769 VCFRONT_infoIndex "Front body controller: info index";
CM_ SG_ 769 VCFRONT_infoBuildType "Front body controller: info build type";
CM_ SG_ 769 VCFRONT_infoBuildConfigId "Front body controller: info build config id";
CM_ SG_ 769 VCFRONT_infoHardwareId "Front body controller: info hardware id";
CM_ SG_ 769 VCFRONT_infoComponentId "Front body controller: info component id";
CM_ SG_ 769 VCFRONT_infoPcbaId "Front body controller: info pcba id";
CM_ SG_ 769 VCFRONT_infoAssemblyId "Front body controller: info assembly id";
CM_ SG_ 769 VCFRONT_infoUsageId "Front body controller: info usage id";
CM_ SG_ 769 VCFRONT_infoSubUsageId "Front body controller: info sub usage id";
CM_ SG_ 769 VCFRONT_infoAppCrc "Front body controller: info app crc";
CM_ SG_ 769 VC_infoHCMLAppCRC "Front body controller: info HCML app CRC";
CM_ SG_ 769 VCFRONT_infoAppGitHash "Front body controller: info app git hash";
CM_ SG_ 769 VCFRONT_infoBootGitHash "Front body controller: info boot git hash";
CM_ SG_ 769 VCFRONT_infoPlatformType "Front body controller: info platform type";
CM_ SG_ 769 VCFRONT_infoBootUdsProtoVersion "Front body controller: info boot uds proto version";
CM_ SG_ 769 VCFRONT_infoBootCrc "Front body controller: info boot crc";
CM_ SG_ 769 VC_infoHCMRAppCRC "Front body controller: info HCMR app CRC";
CM_ SG_ 769 VC_infoWiperAppCRC "Front body controller: info wiper app CRC";
CM_ BO_ 1014 "Front body controller message: light status";
CM_ SG_ 1014 VCFRONT_lowBeamLeftStatus "State of the left headlamp low beam light source";
CM_ SG_ 1014 VCFRONT_lowBeamRightStatus "State of the right headlamp low beam light source";
CM_ SG_ 1014 VCFRONT_highBeamLeftStatus "State of the left headlamp high beam light source";
CM_ SG_ 1014 VCFRONT_highBeamRightStatus "State of the right headlamp high beam light source";
CM_ SG_ 1014 VCFRONT_DRLLeftStatus "Status of the left daytime running light source";
CM_ SG_ 1014 VCFRONT_DRLRightStatus "Status of the right daytime running light source";
CM_ SG_ 1014 VCFRONT_fogLeftStatus "State of the left front fog light source";
CM_ SG_ 1014 VCFRONT_fogRightStatus "State of the right front fog light source";
CM_ SG_ 1014 VCFRONT_sideMarkersStatus "State of the side marker / auxiliary park light sources (left and right are on a shared HSD)";
CM_ SG_ 1014 VCFRONT_sideRepeaterLeftStatus "State of the left side repeater light source";
CM_ SG_ 1014 VCFRONT_sideRepeaterRightStatus "State of the right side repeater light source";
CM_ SG_ 1014 VCFRONT_turnSignalLeftStatus "State of the left front turn signal light source";
CM_ SG_ 1014 VCFRONT_turnSignalRightStatus "State of the right front turn signal light source";
CM_ SG_ 1014 VCFRONT_parkLeftStatus "State of the left position/park light source";
CM_ SG_ 1014 VCFRONT_parkRightStatus "State of the right position/park light source";
CM_ SG_ 1014 VCFRONT_lowBeamLeftReadyForAimin "Front body controller: low beam left ready for aiming";
CM_ SG_ 1014 VCFRONT_lowBeamRightReadyForAimi "Front body controller: low beam right ready for aiming";
CM_ SG_ 1014 VCFRONT_lowBeamsOnForDRL "Shows if the low beam light source is being used to fulfil the daytime running light function (for Canada)";
CM_ SG_ 1014 VC_rightHeadlampHealth "Signal to report whether the right headlamp is powered and communicating";
CM_ SG_ 1014 VC_leftHeadlampHealth "Signal to report whether the left headlamp is powered and communicating";
CM_ SG_ 1014 VCFRONT_lightStatusMuxIndex "Front body controller: light status mux index";
CM_ SG_ 1014 VCFRONT_isAdaptiveHighBeamAvaila "Indication that the conditions (country code, hardware config, etc.) are acceptable to use the advanced driving beam feature.";
CM_ SG_ 1014 VCFRONT_isAdaptiveHighBeamFaulte "Detects if adaptive high beam functionality is unavailable or not operating as expected due to other dependencies.";
CM_ SG_ 1014 VCFRONT_isBendLightingAvailable "Detects if region and hardware conditions currently allow operation of the bend lighting feature.";
CM_ SG_ 1014 VCFRONT_advancedDrivingBeamStatu "Reports the current advanced driving beam system state.";
CM_ SG_ 1014 VCFRONT_headlampBendAngle "Measures the adaptive headlight bend angle.";
CM_ SG_ 1014 VCFRONT_headlampRoadClass "Reports the road class informing the use of dynamic low beams.";
BA_DEF_ BO_ "GenMsgCycleTime" INT 0 3600000;
BA_DEF_ BO_ "GenMsgSendType" ENUM "Cyclic","NotUsed","NotUsed","NotUsed","NotUsed","NotUsed","NotUsed","IfActive","NoMsgSendType","NotUsed";
BA_DEF_ BO_ "VFrameFormat" ENUM "StandardCAN","ExtendedCAN","reserved","J1939PG","reserved","reserved","reserved","reserved","reserved","reserved","reserved","reserved","reserved","reserved","StandardCAN_FD","ExtendedCAN_FD";
BA_DEF_ BO_ "CANFD_BRS" ENUM "0","1";
BA_DEF_ SG_ "SystemSignalLongSymbol" STRING;
BA_DEF_ SG_ "Confidence" ENUM "layout-only","plausible","validated";
BA_DEF_DEF_ "GenMsgCycleTime" 0;
BA_DEF_DEF_ "GenMsgSendType" "NoMsgSendType";
BA_DEF_DEF_ "VFrameFormat" "StandardCAN";
BA_DEF_DEF_ "CANFD_BRS" "1";
BA_DEF_DEF_ "SystemSignalLongSymbol" "";
BA_DEF_DEF_ "Confidence" "layout-only";
BA_ "SystemSignalLongSymbol" SG_ 832 VCFRONT_a004_adaptiveHeadlightsU "VCFRONT_a004_adaptiveHeadlightsUnavailable";
BA_ "SystemSignalLongSymbol" SG_ 832 VCFRONT_a008_adaptiveHeadlightsU "VCFRONT_a008_adaptiveHeadlightsUnavailableStalk";
BA_ "SystemSignalLongSymbol" SG_ 832 VCFRONT_a033_eccNonCorrectableEr "VCFRONT_a033_eccNonCorrectableError";
BA_ "SystemSignalLongSymbol" SG_ 832 VCFRONT_a054_compressorLowFlowUs "VCFRONT_a054_compressorLowFlowUserFacing";
BA_ "SystemSignalLongSymbol" SG_ 832 VCFRONT_a153_userPresenceDisplay "VCFRONT_a153_userPresenceDisplayMismatchClrd";
BA_ "SystemSignalLongSymbol" SG_ 832 VCFRONT_a162_compressorInhibited "VCFRONT_a162_compressorInhibitedContext";
BA_ "SystemSignalLongSymbol" SG_ 832 VCFRONT_a163_compressorDisabledF "VCFRONT_a163_compressorDisabledFSR";
BA_ "SystemSignalLongSymbol" SG_ 832 VCFRONT_a180_DCDCNotSupportingLV "VCFRONT_a180_DCDCNotSupportingLVBus";
BA_ "SystemSignalLongSymbol" SG_ 832 VCFRONT_a184_cabinCoolingPerform "VCFRONT_a184_cabinCoolingPerformanceAbnormal";
BA_ "SystemSignalLongSymbol" SG_ 832 VCFRONT_a191_exitDriveLowLVBusVo "VCFRONT_a191_exitDriveLowLVBusVoltage";
BA_ "SystemSignalLongSymbol" SG_ 832 VCFRONT_a195_drveBlckdVltgeTooHg "VCFRONT_a195_drveBlckdVltgeTooHgh";
BA_ "SystemSignalLongSymbol" SG_ 832 VCFRONT_a205_iBoosterSelfTestFai "VCFRONT_a205_iBoosterSelfTestFail";
BA_ "SystemSignalLongSymbol" SG_ 832 VCFRONT_a207_vbatFusdSelfTestFai "VCFRONT_a207_vbatFusdSelfTestFail";
BA_ "SystemSignalLongSymbol" SG_ 832 VCFRONT_a218_socMonitorDetectedT "VCFRONT_a218_socMonitorDetectedThresholdSoc";
BA_ "SystemSignalLongSymbol" SG_ 832 VCFRONT_a225_driveBlckdByShowroo "VCFRONT_a225_driveBlckdByShowroom";
BA_ "SystemSignalLongSymbol" SG_ 832 VCFRONT_a232_lowSideControllerHi "VCFRONT_a232_lowSideControllerHighFdbk";
BA_ "SystemSignalLongSymbol" SG_ 832 VCFRONT_a233_autopilot1EFuseFaul "VCFRONT_a233_autopilot1EFuseFault";
BA_ "SystemSignalLongSymbol" SG_ 832 VCFRONT_a234_autopilot2EFuseFaul "VCFRONT_a234_autopilot2EFuseFault";
BA_ "SystemSignalLongSymbol" SG_ 832 VCFRONT_a236_batTempSnsIrrationa "VCFRONT_a236_batTempSnsIrrational";
BA_ "SystemSignalLongSymbol" SG_ 832 VCFRONT_a242_drveBlckdVltgeTooLo "VCFRONT_a242_drveBlckdVltgeTooLow";
BA_ "SystemSignalLongSymbol" SG_ 832 VCFRONT_a253_maxChrgeSssionTmeou "VCFRONT_a253_maxChrgeSssionTmeout";
BA_ "SystemSignalLongSymbol" SG_ 832 VCFRONT_a258_resistanceEstimatio "VCFRONT_a258_resistanceEstimationRun";
BA_ "SystemSignalLongSymbol" SG_ 832 VCFRONT_a259_LVVoltageDropOnHigh "VCFRONT_a259_LVVoltageDropOnHighLoadCurrent";
BA_ "SystemSignalLongSymbol" SG_ 832 VCFRONT_a261_vcleftVoltageMismat "VCFRONT_a261_vcleftVoltageMismatch";
BA_ "SystemSignalLongSymbol" SG_ 832 VCFRONT_a262_vcrightVoltageMisma "VCFRONT_a262_vcrightVoltageMismatch";
BA_ "SystemSignalLongSymbol" SG_ 832 VCFRONT_a264_iBoosterVoltageMism "VCFRONT_a264_iBoosterVoltageMismatch";
BA_ "SystemSignalLongSymbol" SG_ 832 VCFRONT_a266_EPAS3pVoltageMismat "VCFRONT_a266_EPAS3pVoltageMismatch";
BA_ "SystemSignalLongSymbol" SG_ 832 VCFRONT_a267_EPAS3sVoltageMismat "VCFRONT_a267_EPAS3sVoltageMismatch";
BA_ "SystemSignalLongSymbol" SG_ 832 VCFRONT_a268_vbatFusedVoltageMis "VCFRONT_a268_vbatFusedVoltageMismatch";
BA_ "SystemSignalLongSymbol" SG_ 832 VCFRONT_a269_drveBlckdVltgeTooLo "VCFRONT_a269_drveBlckdVltgeTooLow2";
BA_ "SystemSignalLongSymbol" SG_ 832 VCFRONT_a271_LVBatteryPermSuppor "VCFRONT_a271_LVBatteryPermSupported";
BA_ "SystemSignalLongSymbol" SG_ 832 VCFRONT_a273_wiperFrictionModelF "VCFRONT_a273_wiperFrictionModelFault";
BA_ "SystemSignalLongSymbol" SG_ 832 VCFRONT_a274_failureToPrechargeR "VCFRONT_a274_failureToPrechargeRisk2";
BA_ "SystemSignalLongSymbol" SG_ 832 VCFRONT_a275_TLVBMS_BmbCommunica "VCFRONT_a275_TLVBMS_BmbCommunication";
BA_ "SystemSignalLongSymbol" SG_ 832 VCFRONT_a276_TLVBMS_BmbDataInteg "VCFRONT_a276_TLVBMS_BmbDataIntegrityLoss";
BA_ "SystemSignalLongSymbol" SG_ 832 VCFRONT_a277_TLVBMS_BmbStatusReg "VCFRONT_a277_TLVBMS_BmbStatusRegError";
BA_ "SystemSignalLongSymbol" SG_ 832 VCFRONT_a278_TLVBMS_BmbHwOverCur "VCFRONT_a278_TLVBMS_BmbHwOverCurrentFault";
BA_ "SystemSignalLongSymbol" SG_ 832 VCFRONT_a281_alcoholInterlockBlo "VCFRONT_a281_alcoholInterlockBlockingDrive";
BA_ "SystemSignalLongSymbol" SG_ 832 VCFRONT_a282_coolantLevelSensorF "VCFRONT_a282_coolantLevelSensorFault";
BA_ "SystemSignalLongSymbol" SG_ 832 VCFRONT_a283_thmlFanLimitedByCur "VCFRONT_a283_thmlFanLimitedByCurrent";
BA_ "SystemSignalLongSymbol" SG_ 832 VCFRONT_a292_sideMarkerLightPipe "VCFRONT_a292_sideMarkerLightPipeFault";
BA_ "SystemSignalLongSymbol" SG_ 832 VCFRONT_a293_interiorFrunkLightF "VCFRONT_a293_interiorFrunkLightFault";
BA_ "SystemSignalLongSymbol" SG_ 832 VCFRONT_a294_leftSideRepeaterLig "VCFRONT_a294_leftSideRepeaterLightFault";
BA_ "SystemSignalLongSymbol" SG_ 832 VCFRONT_a295_rightSideRepeaterLi "VCFRONT_a295_rightSideRepeaterLightFault";
BA_ "SystemSignalLongSymbol" SG_ 832 VCFRONT_a297_TLVBMS_BmbHwOverTem "VCFRONT_a297_TLVBMS_BmbHwOverTemperatureFault";
BA_ "SystemSignalLongSymbol" SG_ 832 VCFRONT_a298_radiatorLowAirFlowD "VCFRONT_a298_radiatorLowAirFlowDetected";
BA_ "SystemSignalLongSymbol" SG_ 832 VCFRONT_a299_homelinkConfigurati "VCFRONT_a299_homelinkConfigurationFailed";
BA_ "SystemSignalLongSymbol" SG_ 832 VCFRONT_a300_louverActuatorSwapD "VCFRONT_a300_louverActuatorSwapDetected";
BA_ "SystemSignalLongSymbol" SG_ 832 VCFRONT_a301_wipersFactoryDisabl "VCFRONT_a301_wipersFactoryDisabled";
BA_ "SystemSignalLongSymbol" SG_ 832 VCFRONT_a303_frunkAccessPostActi "VCFRONT_a303_frunkAccessPostActive";
BA_ "SystemSignalLongSymbol" SG_ 832 VCFRONT_a306_frunkPriUnderCurren "VCFRONT_a306_frunkPriUnderCurrent";
BA_ "SystemSignalLongSymbol" SG_ 832 VCFRONT_a308_frunkSecUnderCurren "VCFRONT_a308_frunkSecUnderCurrent";
BA_ "SystemSignalLongSymbol" SG_ 832 VCFRONT_a309_frunkEmergencyRelea "VCFRONT_a309_frunkEmergencyReleasePressed";
BA_ "SystemSignalLongSymbol" SG_ 832 VCFRONT_a311_vcrightOvertempSlop "VCFRONT_a311_vcrightOvertempSlope";
BA_ "SystemSignalLongSymbol" SG_ 832 VCFRONT_a315_iboosterOvertempSlo "VCFRONT_a315_iboosterOvertempSlope";
BA_ "SystemSignalLongSymbol" SG_ 832 VCFRONT_a317_vbatFusedOvertempSl "VCFRONT_a317_vbatFusedOvertempSlope";
BA_ "SystemSignalLongSymbol" SG_ 832 VCFRONT_a325_vbatFusedOvertempMa "VCFRONT_a325_vbatFusedOvertempMax";
BA_ "SystemSignalLongSymbol" SG_ 832 VCFRONT_a335_vcrightFastTripOCMa "VCFRONT_a335_vcrightFastTripOCMax";
BA_ "SystemSignalLongSymbol" SG_ 832 VCFRONT_a339_iboosterFastTripOCM "VCFRONT_a339_iboosterFastTripOCMax";
BA_ "SystemSignalLongSymbol" SG_ 832 VCFRONT_a341_vbatFusedFastTripOC "VCFRONT_a341_vbatFusedFastTripOCMax";
BA_ "SystemSignalLongSymbol" SG_ 832 VCFRONT_a343_vcrightFastTripSlop "VCFRONT_a343_vcrightFastTripSlope";
BA_ "SystemSignalLongSymbol" SG_ 832 VCFRONT_a347_iboosterFastTripSlo "VCFRONT_a347_iboosterFastTripSlope";
BA_ "SystemSignalLongSymbol" SG_ 832 VCFRONT_a349_vbatFusedFastTripSl "VCFRONT_a349_vbatFusedFastTripSlope";
BA_ "SystemSignalLongSymbol" SG_ 832 VCFRONT_a350_espValveCurrentSens "VCFRONT_a350_espValveCurrentSenseSaturated";
BA_ "SystemSignalLongSymbol" SG_ 832 VCFRONT_a351_emergencyFrunkButto "VCFRONT_a351_emergencyFrunkButtonPressIgnored";
BA_ "SystemSignalLongSymbol" SG_ 832 VCFRONT_a352_audioCurrentSpikeDa "VCFRONT_a352_audioCurrentSpikeData";
BA_ "SystemSignalLongSymbol" SG_ 832 VCFRONT_a353_wiperHeaterUndercur "VCFRONT_a353_wiperHeaterUndercurrent";
BA_ "SystemSignalLongSymbol" SG_ 832 VCFRONT_a354_windshieldCameraHea "VCFRONT_a354_windshieldCameraHeaterUndercurrent";
BA_ "SystemSignalLongSymbol" SG_ 832 VCFRONT_a360_ungracefulAccPlusEx "VCFRONT_a360_ungracefulAccPlusExit";
BA_ "SystemSignalLongSymbol" SG_ 832 VCFRONT_a361_washerFluidLowMomen "VCFRONT_a361_washerFluidLowMomentary";
BA_ "SystemSignalLongSymbol" SG_ 832 VCFRONT_a362_TLVBMS_AllSocCorrec "VCFRONT_a362_TLVBMS_AllSocCorrectionTimeout";
BA_ "SystemSignalLongSymbol" SG_ 832 VCFRONT_a363_TLVBMS_BleedBasedWe "VCFRONT_a363_TLVBMS_BleedBasedWeakShort";
BA_ "SystemSignalLongSymbol" SG_ 832 VCFRONT_a364_heaterTypeEstimatio "VCFRONT_a364_heaterTypeEstimationChanged";
BA_ "SystemSignalLongSymbol" SG_ 832 VCFRONT_a365_burnInRoutineEntere "VCFRONT_a365_burnInRoutineEntered";
BA_ "SystemSignalLongSymbol" SG_ 832 VCFRONT_a367_dischargeRoutineEnt "VCFRONT_a367_dischargeRoutineEntered";
BA_ "SystemSignalLongSymbol" SG_ 832 VCFRONT_a368_dischargeRoutineExi "VCFRONT_a368_dischargeRoutineExited";
BA_ "SystemSignalLongSymbol" SG_ 832 VCFRONT_a369_reducedPowerDischar "VCFRONT_a369_reducedPowerDischarge";
BA_ "SystemSignalLongSymbol" SG_ 832 VCFRONT_a370_noLVSupportSocTooLo "VCFRONT_a370_noLVSupportSocTooLow";
BA_ "SystemSignalLongSymbol" SG_ 832 VCFRONT_a371_failureToPrechargeR "VCFRONT_a371_failureToPrechargeRisk";
BA_ "SystemSignalLongSymbol" SG_ 832 VCFRONT_a372_TLVBMS_BmbHwOverVol "VCFRONT_a372_TLVBMS_BmbHwOverVoltageFault";
BA_ "SystemSignalLongSymbol" SG_ 832 VCFRONT_a373_chillerControlFlood "VCFRONT_a373_chillerControlFlooding";
BA_ "SystemSignalLongSymbol" SG_ 832 VCFRONT_a374_lccInletSolenoidFau "VCFRONT_a374_lccInletSolenoidFault";
BA_ "SystemSignalLongSymbol" SG_ 832 VCFRONT_a376_controllerWakeupDeb "VCFRONT_a376_controllerWakeupDebug";
BA_ "SystemSignalLongSymbol" SG_ 832 VCFRONT_a379_shortedCellTestRunD "VCFRONT_a379_shortedCellTestRunDebug";
BA_ "SystemSignalLongSymbol" SG_ 832 VCFRONT_a381_evaporatorExvWarnin "VCFRONT_a381_evaporatorExvWarning";
BA_ "SystemSignalLongSymbol" SG_ 832 VCFRONT_a389_frunkInhibitingRele "VCFRONT_a389_frunkInhibitingReleaseAtSpeed";
BA_ "SystemSignalLongSymbol" SG_ 832 VCFRONT_a390_heatPumpModeConverg "VCFRONT_a390_heatPumpModeConvergence";
BA_ "SystemSignalLongSymbol" SG_ 832 VCFRONT_a391_frunkLatchSwitchFau "VCFRONT_a391_frunkLatchSwitchFault";
BA_ "SystemSignalLongSymbol" SG_ 832 VCFRONT_a392_TLVBMS_BmbHwUnderVo "VCFRONT_a392_TLVBMS_BmbHwUnderVoltageFault";
BA_ "SystemSignalLongSymbol" SG_ 832 VCFRONT_a393_ambientTempNetworkS "VCFRONT_a393_ambientTempNetworkSna";
BA_ "SystemSignalLongSymbol" SG_ 832 VCFRONT_a394_pressureSensorCheck "VCFRONT_a394_pressureSensorCheckFault";
BA_ "SystemSignalLongSymbol" SG_ 832 VCFRONT_a395_pressureSensorCheck "VCFRONT_a395_pressureSensorCheckInconclusive";
BA_ "SystemSignalLongSymbol" SG_ 832 VCFRONT_a396_coolantLevelLowUser "VCFRONT_a396_coolantLevelLowUserFacing";
BA_ "SystemSignalLongSymbol" SG_ 832 VCFRONT_a397_temperatureSensorCh "VCFRONT_a397_temperatureSensorCheckFault";
BA_ "SystemSignalLongSymbol" SG_ 832 VCFRONT_a398_tempSensorCheckInco "VCFRONT_a398_tempSensorCheckInconclusive";
BA_ "SystemSignalLongSymbol" SG_ 832 VCFRONT_a399_frunkNeverReportedO "VCFRONT_a399_frunkNeverReportedOpen";
BA_ "SystemSignalLongSymbol" SG_ 832 VCFRONT_a401_deadLVMinimalAhDisc "VCFRONT_a401_deadLVMinimalAhDischarged";
BA_ "SystemSignalLongSymbol" SG_ 832 VCFRONT_a402_LVBatteryCannotSupp "VCFRONT_a402_LVBatteryCannotSupportVehicle";
BA_ "SystemSignalLongSymbol" SG_ 832 VCFRONT_a403_chargeExitHardCurre "VCFRONT_a403_chargeExitHardCurrentLimit";
BA_ "SystemSignalLongSymbol" SG_ 832 VCFRONT_a404_resistanceEstimatio "VCFRONT_a404_resistanceEstimationHardFailure";
BA_ "SystemSignalLongSymbol" SG_ 832 VCFRONT_a407_dcrMilliOhmsAboveTh "VCFRONT_a407_dcrMilliOhmsAboveThreshold";
BA_ "SystemSignalLongSymbol" SG_ 832 VCFRONT_a408_standbyChargeProfil "VCFRONT_a408_standbyChargeProfileHardExit";
BA_ "SystemSignalLongSymbol" SG_ 832 VCFRONT_a409_invalidConfiguratio "VCFRONT_a409_invalidConfiguration";
BA_ "SystemSignalLongSymbol" SG_ 832 VCFRONT_a410_LVBatteryDataCollec "VCFRONT_a410_LVBatteryDataCollection1";
BA_ "SystemSignalLongSymbol" SG_ 832 VCFRONT_a411_LVBatteryDataCollec "VCFRONT_a411_LVBatteryDataCollection2";
BA_ "SystemSignalLongSymbol" SG_ 832 VCFRONT_a413_TLVBMS_BmbVrefWarni "VCFRONT_a413_TLVBMS_BmbVrefWarning";
BA_ "SystemSignalLongSymbol" SG_ 832 VCFRONT_a414_prechargeLVLoadRedu "VCFRONT_a414_prechargeLVLoadReduction";
BA_ "SystemSignalLongSymbol" SG_ 832 VCFRONT_a415_prechargeLVLoadRedu "VCFRONT_a415_prechargeLVLoadReduction2";
BA_ "SystemSignalLongSymbol" SG_ 832 VCFRONT_a416_TLVBMS_BrickOverDis "VCFRONT_a416_TLVBMS_BrickOverDischarged";
BA_ "SystemSignalLongSymbol" SG_ 832 VCFRONT_a417_TLVBMS_BrickOverVol "VCFRONT_a417_TLVBMS_BrickOverVoltageFault";
BA_ "SystemSignalLongSymbol" SG_ 832 VCFRONT_a418_TLVBMS_BrickOverVol "VCFRONT_a418_TLVBMS_BrickOverVoltageWarning";
BA_ "SystemSignalLongSymbol" SG_ 832 VCFRONT_a421_leftHeadlampUartCon "VCFRONT_a421_leftHeadlampUartCondition";
BA_ "SystemSignalLongSymbol" SG_ 832 VCFRONT_a423_TLVBMS_BrickUnderVo "VCFRONT_a423_TLVBMS_BrickUnderVoltageFault";
BA_ "SystemSignalLongSymbol" SG_ 832 VCFRONT_a424_TLVBMS_BrickUnderVo "VCFRONT_a424_TLVBMS_BrickUnderVoltageOcv";
BA_ "SystemSignalLongSymbol" SG_ 832 VCFRONT_a425_TLVBMS_BusVoltageTo "VCFRONT_a425_TLVBMS_BusVoltageTooHigh";
BA_ "SystemSignalLongSymbol" SG_ 832 VCFRONT_a426_TLVBMS_BusVoltageTo "VCFRONT_a426_TLVBMS_BusVoltageTooLow";
BA_ "SystemSignalLongSymbol" SG_ 832 VCFRONT_a429_TLVBMS_CapacityTest "VCFRONT_a429_TLVBMS_CapacityTestResults";
BA_ "SystemSignalLongSymbol" SG_ 832 VCFRONT_a430_TLVBMS_ChargeCurren "VCFRONT_a430_TLVBMS_ChargeCurrentLimitExceeded";
BA_ "SystemSignalLongSymbol" SG_ 832 VCFRONT_a431_TLVBMS_ChargeOverCu "VCFRONT_a431_TLVBMS_ChargeOverCurrent";
BA_ "SystemSignalLongSymbol" SG_ 832 VCFRONT_a432_TLVBMS_ChargeRegula "VCFRONT_a432_TLVBMS_ChargeRegulationFault";
BA_ "SystemSignalLongSymbol" SG_ 832 VCFRONT_a433_TLVBMS_ConfigFromBm "VCFRONT_a433_TLVBMS_ConfigFromBmbModIdFailed";
BA_ "SystemSignalLongSymbol" SG_ 832 VCFRONT_a434_TLVBMS_ConfigInitFa "VCFRONT_a434_TLVBMS_ConfigInitFailed";
BA_ "SystemSignalLongSymbol" SG_ 832 VCFRONT_a435_TLVBMS_DchgCurrentL "VCFRONT_a435_TLVBMS_DchgCurrentLimitExceeded";
BA_ "SystemSignalLongSymbol" SG_ 832 VCFRONT_a436_TLVBMS_DischargeOve "VCFRONT_a436_TLVBMS_DischargeOverCurrent";
BA_ "SystemSignalLongSymbol" SG_ 832 VCFRONT_a437_TLVBMS_NvmRegistrat "VCFRONT_a437_TLVBMS_NvmRegistrationError";
BA_ "SystemSignalLongSymbol" SG_ 832 VCFRONT_a438_TLVBMS_PackOverTemp "VCFRONT_a438_TLVBMS_PackOverTemperatureFault";
BA_ "SystemSignalLongSymbol" SG_ 832 VCFRONT_a439_TLVBMS_PackOverTemp "VCFRONT_a439_TLVBMS_PackOverTemperatureWarning";
BA_ "SystemSignalLongSymbol" SG_ 832 VCFRONT_a440_TLVBMS_PackSNInvali "VCFRONT_a440_TLVBMS_PackSNInvalidForNvm";
BA_ "SystemSignalLongSymbol" SG_ 832 VCFRONT_a441_TLVBMS_ResetNeededF "VCFRONT_a441_TLVBMS_ResetNeededForNvmPackSwap";
BA_ "SystemSignalLongSymbol" SG_ 832 VCFRONT_a443_TLVBMS_BmbDieOverTe "VCFRONT_a443_TLVBMS_BmbDieOverTemperature";
BA_ "SystemSignalLongSymbol" SG_ 832 VCFRONT_a446_cabinHVACUnavailabl "VCFRONT_a446_cabinHVACUnavailableContext";
BA_ "SystemSignalLongSymbol" SG_ 832 VCFRONT_a447_cabinHVACUnavailabl "VCFRONT_a447_cabinHVACUnavailable";
BA_ "SystemSignalLongSymbol" SG_ 832 VCFRONT_a450_hornSwitchNotPresse "VCFRONT_a450_hornSwitchNotPressedFactory";
BA_ "SystemSignalLongSymbol" SG_ 832 VCFRONT_a451_refrigerantNotCommi "VCFRONT_a451_refrigerantNotCommissioned";
BA_ "SystemSignalLongSymbol" SG_ 832 VCFRONT_a452_dischargePresSensIn "VCFRONT_a452_dischargePresSensIntermittent";
BA_ "SystemSignalLongSymbol" SG_ 832 VCFRONT_a453_dischargeTempSensIn "VCFRONT_a453_dischargeTempSensIntermittent";
BA_ "SystemSignalLongSymbol" SG_ 832 VCFRONT_a454_suctionPresSensInte "VCFRONT_a454_suctionPresSensIntermittent";
BA_ "SystemSignalLongSymbol" SG_ 832 VCFRONT_a455_suctionTempSensInte "VCFRONT_a455_suctionTempSensIntermittent";
BA_ "SystemSignalLongSymbol" SG_ 832 VCFRONT_a456_liquidPresSensInter "VCFRONT_a456_liquidPresSensIntermittent";
BA_ "SystemSignalLongSymbol" SG_ 832 VCFRONT_a457_liquidTempSensInter "VCFRONT_a457_liquidTempSensIntermittent";
BA_ "SystemSignalLongSymbol" SG_ 832 VCFRONT_a458_grosslyLowRefrigera "VCFRONT_a458_grosslyLowRefrigerant";
BA_ "SystemSignalLongSymbol" SG_ 832 VCFRONT_a460_hardIsentropicTdFai "VCFRONT_a460_hardIsentropicTdFailed";
BA_ "SystemSignalLongSymbol" SG_ 832 VCFRONT_a461_TLVBMS_SocHighAhErr "VCFRONT_a461_TLVBMS_SocHighAhError";
BA_ "SystemSignalLongSymbol" SG_ 832 VCFRONT_a464_highFlowIndexHighSu "VCFRONT_a464_highFlowIndexHighSubcoolFlagged";
BA_ "SystemSignalLongSymbol" SG_ 832 VCFRONT_a465_lowFlowIndexHighSub "VCFRONT_a465_lowFlowIndexHighSubcoolFlagged";
BA_ "SystemSignalLongSymbol" SG_ 832 VCFRONT_a466_highFlowIndexLowSub "VCFRONT_a466_highFlowIndexLowSubcoolFlagged";
BA_ "SystemSignalLongSymbol" SG_ 832 VCFRONT_a467_lowPowerIndexFlagge "VCFRONT_a467_lowPowerIndexFlagged";
BA_ "SystemSignalLongSymbol" SG_ 832 VCFRONT_a468_highPowerIndexFlagg "VCFRONT_a468_highPowerIndexFlagged";
BA_ "SystemSignalLongSymbol" SG_ 832 VCFRONT_a470_implausiblePdPlDete "VCFRONT_a470_implausiblePdPlDetected";
BA_ "SystemSignalLongSymbol" SG_ 832 VCFRONT_a472_leftHeadlampRangeUp "VCFRONT_a472_leftHeadlampRangeUpdate";
BA_ "SystemSignalLongSymbol" SG_ 832 VCFRONT_a473_rightHeadlampRangeU "VCFRONT_a473_rightHeadlampRangeUpdate";
BA_ "SystemSignalLongSymbol" SG_ 832 VCFRONT_a474_leftHeadlampInterna "VCFRONT_a474_leftHeadlampInternalError";
BA_ "SystemSignalLongSymbol" SG_ 832 VCFRONT_a475_rightHeadlampIntern "VCFRONT_a475_rightHeadlampInternalError";
BA_ "SystemSignalLongSymbol" SG_ 832 VCFRONT_a477_LVBatteryUnrecovera "VCFRONT_a477_LVBatteryUnrecoverableByVehicle";
BA_ "SystemSignalLongSymbol" SG_ 832 VCFRONT_a479_LVBMS_ECPA_NotClose "VCFRONT_a479_LVBMS_ECPA_NotClosed";
BA_ "SystemSignalLongSymbol" SG_ 832 VCFRONT_a481_vnf1048SelfTestFail "VCFRONT_a481_vnf1048SelfTestFailure";
BA_ "SystemSignalLongSymbol" SG_ 832 VCFRONT_a482_rightHeadlampMigrat "VCFRONT_a482_rightHeadlampMigrationDebug";
BA_ "SystemSignalLongSymbol" SG_ 832 VCFRONT_a483_leftHeadlampStepper "VCFRONT_a483_leftHeadlampStepperMotorFault";
BA_ "SystemSignalLongSymbol" SG_ 832 VCFRONT_a484_headlampLevelingRid "VCFRONT_a484_headlampLevelingRideHeightDebug";
BA_ "SystemSignalLongSymbol" SG_ 832 VCFRONT_a485_leftHeadlampMigrati "VCFRONT_a485_leftHeadlampMigrationDebug";
BA_ "SystemSignalLongSymbol" SG_ 832 VCFRONT_a486_mcuGraphicsEFuseFau "VCFRONT_a486_mcuGraphicsEFuseFault";
BA_ "SystemSignalLongSymbol" SG_ 832 VCFRONT_a487_leftHeadlampLastPos "VCFRONT_a487_leftHeadlampLastPositionUpdate";
BA_ "SystemSignalLongSymbol" SG_ 832 VCFRONT_a488_rightHeadlampSteppe "VCFRONT_a488_rightHeadlampStepperMotorFault";
BA_ "SystemSignalLongSymbol" SG_ 832 VCFRONT_a490_coolantPumpsNotIden "VCFRONT_a490_coolantPumpsNotIdentified";
BA_ "SystemSignalLongSymbol" SG_ 832 VCFRONT_a491_rightHeadlampLastPo "VCFRONT_a491_rightHeadlampLastPositionUpdate";
BA_ "SystemSignalLongSymbol" SG_ 832 VCFRONT_a493_TLVBMS_SocImbalance "VCFRONT_a493_TLVBMS_SocImbalanceWarning";
BA_ "SystemSignalLongSymbol" SG_ 832 VCFRONT_a494_LVBatteryTempBlocki "VCFRONT_a494_LVBatteryTempBlockingOTA";
BA_ "SystemSignalLongSymbol" SG_ 832 VCFRONT_a495_LVBatteryRecoveryBl "VCFRONT_a495_LVBatteryRecoveryBlocked";
BA_ "SystemSignalLongSymbol" SG_ 832 VCFRONT_a496_LVBatteryExitDriveW "VCFRONT_a496_LVBatteryExitDriveWarning";
BA_ "SystemSignalLongSymbol" SG_ 832 VCFRONT_a497_LVBatteryWarnDiscon "VCFRONT_a497_LVBatteryWarnDisconnect";
BA_ "SystemSignalLongSymbol" SG_ 832 VCFRONT_a498_TLVBMS_ImpedanceTes "VCFRONT_a498_TLVBMS_ImpedanceTestResults";
BA_ "SystemSignalLongSymbol" SG_ 832 VCFRONT_a499_loadShedPumpFlowReq "VCFRONT_a499_loadShedPumpFlowRequest";
BA_ "SystemSignalLongSymbol" SG_ 832 VCFRONT_a500_eFuseASICStateMisma "VCFRONT_a500_eFuseASICStateMismatch";
BA_ "SystemSignalLongSymbol" SG_ 832 VCFRONT_a501_vnf1048Configuratio "VCFRONT_a501_vnf1048ConfigurationMismatch";
BA_ "SystemSignalLongSymbol" SG_ 832 VCFRONT_a502_TLVBMS_WeakShortImp "VCFRONT_a502_TLVBMS_WeakShortImpedance";
BA_ "SystemSignalLongSymbol" SG_ 832 VCFRONT_a503_TLVBMS_BrickExtende "VCFRONT_a503_TLVBMS_BrickExtendedOvFault";
BA_ "SystemSignalLongSymbol" SG_ 832 VCFRONT_a504_airInRefrigerantDet "VCFRONT_a504_airInRefrigerantDetected";
BA_ "SystemSignalLongSymbol" SG_ 832 VCFRONT_a505_BLEFrontUnderVoltag "VCFRONT_a505_BLEFrontUnderVoltage";
BA_ "SystemSignalLongSymbol" SG_ 832 VCFRONT_a506_invalidRefrigerantS "VCFRONT_a506_invalidRefrigerantSystemConfig";
BA_ "SystemSignalLongSymbol" SG_ 832 VCFRONT_a507_leftHeadlampAimingF "VCFRONT_a507_leftHeadlampAimingFault";
BA_ "SystemSignalLongSymbol" SG_ 832 VCFRONT_a508_TLVBMS_ImpedanceGro "VCFRONT_a508_TLVBMS_ImpedanceGrowth";
BA_ "SystemSignalLongSymbol" SG_ 832 VCFRONT_a509_vcrightEFuseLoadShe "VCFRONT_a509_vcrightEFuseLoadShed";
BA_ "SystemSignalLongSymbol" SG_ 832 VCFRONT_a510_LVBatteryRecoveryTi "VCFRONT_a510_LVBatteryRecoveryTimeout";
BA_ "SystemSignalLongSymbol" SG_ 832 VCFRONT_a511_DCDCSaturationLoadS "VCFRONT_a511_DCDCSaturationLoadShed";
BA_ "SystemSignalLongSymbol" SG_ 832 VCFRONT_a512_LVBMSFault_MOS_Open "VCFRONT_a512_LVBMSFault_MOS_Open_hardwareOC";
BA_ "SystemSignalLongSymbol" SG_ 832 VCFRONT_a513_LVBMSFault_MOS_Open "VCFRONT_a513_LVBMSFault_MOS_Open_chgOC";
BA_ "SystemSignalLongSymbol" SG_ 832 VCFRONT_a514_LVBMSFault_MOS_Open "VCFRONT_a514_LVBMSFault_MOS_Open_cellUV";
BA_ "SystemSignalLongSymbol" SG_ 832 VCFRONT_a515_LVBMSFault_MOS_Open "VCFRONT_a515_LVBMSFault_MOS_Open_cellOV";
BA_ "SystemSignalLongSymbol" SG_ 832 VCFRONT_a518_LVBMSFault_MOS_Open "VCFRONT_a518_LVBMSFault_MOS_Open_packOV";
BA_ "SystemSignalLongSymbol" SG_ 832 VCFRONT_a519_leftHeadlampInterna "VCFRONT_a519_leftHeadlampInternalErrorV2";
BA_ "SystemSignalLongSymbol" SG_ 832 VCFRONT_a520_rightHeadlampIntern "VCFRONT_a520_rightHeadlampInternalErrorV2";
BA_ "SystemSignalLongSymbol" SG_ 832 VCFRONT_a522_hibernationActiveLo "VCFRONT_a522_hibernationActiveLogCapture";
BA_ "SystemSignalLongSymbol" SG_ 832 VCFRONT_a523_eFuseThresholdsInco "VCFRONT_a523_eFuseThresholdsIncorrect";
BA_ "SystemSignalLongSymbol" SG_ 832 VCFRONT_a524_rightHeadlampAiming "VCFRONT_a524_rightHeadlampAimingFault";
BA_ "SystemSignalLongSymbol" SG_ 832 VCFRONT_a525_LVBatterySWMisconfi "VCFRONT_a525_LVBatterySWMisconfiguration";
BA_ "SystemSignalLongSymbol" SG_ 832 VCFRONT_a527_LVBatteryCellImbala "VCFRONT_a527_LVBatteryCellImbalance";
BA_ "SystemSignalLongSymbol" SG_ 832 VCFRONT_a528_LVBatteryCommsDiscn "VCFRONT_a528_LVBatteryCommsDiscnctd";
BA_ "SystemSignalLongSymbol" SG_ 832 VCFRONT_a529_discnctdBatteryStat "VCFRONT_a529_discnctdBatteryStateUnknown";
BA_ "SystemSignalLongSymbol" SG_ 832 VCFRONT_a531_lowPowerIndexFlagge "VCFRONT_a531_lowPowerIndexFlaggedUserFacing";
BA_ "SystemSignalLongSymbol" SG_ 832 VCFRONT_a533_TLVBMS_MosfetOverTe "VCFRONT_a533_TLVBMS_MosfetOverTemperatureFault";
BA_ "SystemSignalLongSymbol" SG_ 832 VCFRONT_a534_chillerExvCalibInit "VCFRONT_a534_chillerExvCalibInitDebug";
BA_ "SystemSignalLongSymbol" SG_ 832 VCFRONT_a535_evapExvCalibInitDeb "VCFRONT_a535_evapExvCalibInitDebug";
BA_ "SystemSignalLongSymbol" SG_ 832 VCFRONT_a536_recircExvCalibInitD "VCFRONT_a536_recircExvCalibInitDebug";
BA_ "SystemSignalLongSymbol" SG_ 832 VCFRONT_a537_lccExvCalibInitDebu "VCFRONT_a537_lccExvCalibInitDebug";
BA_ "SystemSignalLongSymbol" SG_ 832 VCFRONT_a538_cclExvCalibInitDebu "VCFRONT_a538_cclExvCalibInitDebug";
BA_ "SystemSignalLongSymbol" SG_ 832 VCFRONT_a539_ccrExvCalibInitDebu "VCFRONT_a539_ccrExvCalibInitDebug";
BA_ "SystemSignalLongSymbol" SG_ 832 VCFRONT_a540_radiatorSteamDetect "VCFRONT_a540_radiatorSteamDetected";
BA_ "SystemSignalLongSymbol" SG_ 832 VCFRONT_a541_LVBatteryChargeOCLe "VCFRONT_a541_LVBatteryChargeOCLevel1";
BA_ "SystemSignalLongSymbol" SG_ 832 VCFRONT_a543_compressorLowFlowDe "VCFRONT_a543_compressorLowFlowDeliveryDetected";
BA_ "SystemSignalLongSymbol" SG_ 832 VCFRONT_a544_LVBatteryCommsBusTu "VCFRONT_a544_LVBatteryCommsBusTurnedOff";
BA_ "SystemSignalLongSymbol" SG_ 832 VCFRONT_a545_LVBatteryTypeUnknow "VCFRONT_a545_LVBatteryTypeUnknown";
BA_ "SystemSignalLongSymbol" SG_ 832 VCFRONT_a546_leftLowOrHighBeamLi "VCFRONT_a546_leftLowOrHighBeamLightCondition";
BA_ "SystemSignalLongSymbol" SG_ 832 VCFRONT_a549_leftHeadlampInterna "VCFRONT_a549_leftHeadlampInternalErrorV3";
BA_ "SystemSignalLongSymbol" SG_ 832 VCFRONT_a551_leftHeadlampSoftSho "VCFRONT_a551_leftHeadlampSoftShort";
BA_ "SystemSignalLongSymbol" SG_ 832 VCFRONT_a552_eFuseSelfTestFailur "VCFRONT_a552_eFuseSelfTestFailure";
BA_ "SystemSignalLongSymbol" SG_ 832 VCFRONT_a553_rightHeadlampSoftSh "VCFRONT_a553_rightHeadlampSoftShort";
BA_ "SystemSignalLongSymbol" SG_ 832 VCFRONT_a555_LVBatteryCellRebala "VCFRONT_a555_LVBatteryCellRebalancing";
BA_ "SystemSignalLongSymbol" SG_ 832 VCFRONT_a556_falseTriggerOfDiscn "VCFRONT_a556_falseTriggerOfDiscnctdBatteryTest";
BA_ "SystemSignalLongSymbol" SG_ 832 VCFRONT_a557_rightHeadlampIntern "VCFRONT_a557_rightHeadlampInternalErrorV3";
BA_ "SystemSignalLongSymbol" SG_ 832 VCFRONT_a558_rightHeadlampAiming "VCFRONT_a558_rightHeadlampAimingDebug";
BA_ "SystemSignalLongSymbol" SG_ 832 VCFRONT_a560_compressorHighSuper "VCFRONT_a560_compressorHighSuperheat";
BA_ "SystemSignalLongSymbol" SG_ 832 VCFRONT_a561_LVBMSEFuseOvertempe "VCFRONT_a561_LVBMSEFuseOvertemperature";
BA_ "SystemSignalLongSymbol" SG_ 832 VCFRONT_a562_LVBMSModuleOvertemp "VCFRONT_a562_LVBMSModuleOvertemperature";
BA_ "SystemSignalLongSymbol" SG_ 832 VCFRONT_a563_chargePortDoorOpenB "VCFRONT_a563_chargePortDoorOpenBlockedByBrake";
BA_ "SystemSignalLongSymbol" SG_ 832 VCFRONT_a564_leftHeadlampAimingD "VCFRONT_a564_leftHeadlampAimingDebug";
BA_ "SystemSignalLongSymbol" SG_ 832 VCFRONT_a565_userPresenceDisplay "VCFRONT_a565_userPresenceDisplayStateMismatch";
BA_ "SystemSignalLongSymbol" SG_ 832 VCFRONT_a566_leftFrontTurnLightF "VCFRONT_a566_leftFrontTurnLightFault";
BA_ "SystemSignalLongSymbol" SG_ 832 VCFRONT_a567_rightFrontTurnLight "VCFRONT_a567_rightFrontTurnLightFault";
BA_ "SystemSignalLongSymbol" SG_ 832 VCFRONT_a568_leftDaytimeRunningL "VCFRONT_a568_leftDaytimeRunningLightFault";
BA_ "SystemSignalLongSymbol" SG_ 832 VCFRONT_a569_rightDaytimeRunning "VCFRONT_a569_rightDaytimeRunningLightFault";
BA_ "SystemSignalLongSymbol" SG_ 832 VCFRONT_a570_headlampsAdaptedToL "VCFRONT_a570_headlampsAdaptedToLeftHandTraffic";
BA_ "SystemSignalLongSymbol" SG_ 832 VCFRONT_a571_headlampsAdaptedToR "VCFRONT_a571_headlampsAdaptedToRightHandTraffic";
BA_ "SystemSignalLongSymbol" SG_ 832 VCFRONT_a572_hvacCompressorEFuse "VCFRONT_a572_hvacCompressorEFuseTrip";
BA_ "SystemSignalLongSymbol" SG_ 832 VCFRONT_a574_frontDriveInverterE "VCFRONT_a574_frontDriveInverterEFuseTrip";
BA_ "SystemSignalLongSymbol" SG_ 832 VCFRONT_a575_frontOilPumpEFuseTr "VCFRONT_a575_frontOilPumpEFuseTrip";
BA_ "SystemSignalLongSymbol" SG_ 832 VCFRONT_a578_vbatFusedLowCurrent "VCFRONT_a578_vbatFusedLowCurrentFeedEFuseTrip";
BA_ "SystemSignalLongSymbol" SG_ 832 VCFRONT_a579_leftHeadlightEFuseT "VCFRONT_a579_leftHeadlightEFuseTrip";
BA_ "SystemSignalLongSymbol" SG_ 832 VCFRONT_a580_rightHeadlightEFuse "VCFRONT_a580_rightHeadlightEFuseTrip";
BA_ "SystemSignalLongSymbol" SG_ 832 VCFRONT_a581_windshieldWiperEFus "VCFRONT_a581_windshieldWiperEFuseTrip";
BA_ "SystemSignalLongSymbol" SG_ 832 VCFRONT_a582_goodForPCSPowerCycl "VCFRONT_a582_goodForPCSPowerCycle";
BA_ "SystemSignalLongSymbol" SG_ 832 VCFRONT_a583_frunkSwitchGroupDis "VCFRONT_a583_frunkSwitchGroupDisagreementDebug";
BA_ "SystemSignalLongSymbol" SG_ 832 VCFRONT_a584_frunkSwitchGroupDeb "VCFRONT_a584_frunkSwitchGroupDebug";
BA_ "SystemSignalLongSymbol" SG_ 832 VCFRONT_a585_bothHeadlampsIntern "VCFRONT_a585_bothHeadlampsInternalError";
BA_ "SystemSignalLongSymbol" SG_ 832 VCFRONT_a586_rightLowOrHighBeamL "VCFRONT_a586_rightLowOrHighBeamLightCondition";
BA_ "SystemSignalLongSymbol" SG_ 832 VCFRONT_a587_externalLVPowerSupp "VCFRONT_a587_externalLVPowerSupply";
BA_ "SystemSignalLongSymbol" SG_ 832 VCFRONT_a588_vcleftPwrRationalit "VCFRONT_a588_vcleftPwrRationalityCurve";
BA_ "SystemSignalLongSymbol" SG_ 832 VCFRONT_a589_vcleftFastBlowDetec "VCFRONT_a589_vcleftFastBlowDetection";
BA_ "SystemSignalLongSymbol" SG_ 832 VCFRONT_a590_vcrightPwrRationali "VCFRONT_a590_vcrightPwrRationalityCurve";
BA_ "SystemSignalLongSymbol" SG_ 832 VCFRONT_a591_vcrightFastBlowDete "VCFRONT_a591_vcrightFastBlowDetection";
BA_ "SystemSignalLongSymbol" SG_ 832 VCFRONT_a592_vcleftCurvePowerCut "VCFRONT_a592_vcleftCurvePowerCutoff";
BA_ "SystemSignalLongSymbol" SG_ 832 VCFRONT_a593_vcleftFastBlowPower "VCFRONT_a593_vcleftFastBlowPowerCutoff";
BA_ "SystemSignalLongSymbol" SG_ 832 VCFRONT_a594_virtualPitchConvers "VCFRONT_a594_virtualPitchConversionDebug";
BA_ "SystemSignalLongSymbol" SG_ 832 VCFRONT_a595_voltageSensorMismat "VCFRONT_a595_voltageSensorMismatch";
BA_ "SystemSignalLongSymbol" SG_ 832 VCFRONT_a596_vcrightCurvePowerCu "VCFRONT_a596_vcrightCurvePowerCutoff";
BA_ "SystemSignalLongSymbol" SG_ 832 VCFRONT_a597_vcrightFastBlowPowe "VCFRONT_a597_vcrightFastBlowPowerCutoff";
BA_ "SystemSignalLongSymbol" SG_ 832 VCFRONT_a598_eFuseSelfTestFailur "VCFRONT_a598_eFuseSelfTestFailureService";
BA_ "SystemSignalLongSymbol" SG_ 832 VCFRONT_a599_LVBatteryTypeUnsupp "VCFRONT_a599_LVBatteryTypeUnsupported";
BA_ "SystemSignalLongSymbol" SG_ 832 VCFRONT_a600_currentSensorMismat "VCFRONT_a600_currentSensorMismatch";
BA_ "SystemSignalLongSymbol" SG_ 832 VCFRONT_a601_autopilotAirPurgeLi "VCFRONT_a601_autopilotAirPurgeLimitReached";
BA_ "SystemSignalLongSymbol" SG_ 832 VCFRONT_a602_unknownTurnIndicato "VCFRONT_a602_unknownTurnIndicatorConfig";
BA_ "SystemSignalLongSymbol" SG_ 832 VCFRONT_a603_unexpectedTurnIndic "VCFRONT_a603_unexpectedTurnIndicatorConfigChange";
BA_ "SystemSignalLongSymbol" SG_ 832 VCFRONT_a604_turnIndicatorConfig "VCFRONT_a604_turnIndicatorConfigInputMismatch";
BA_ "SystemSignalLongSymbol" SG_ 832 VCFRONT_a606_chillerBattHeatingE "VCFRONT_a606_chillerBattHeatingExit";
BA_ "SystemSignalLongSymbol" SG_ 832 VCFRONT_a608_TLVBMS_BleedFetFail "VCFRONT_a608_TLVBMS_BleedFetFailure";
BA_ "SystemSignalLongSymbol" SG_ 832 VCFRONT_a609_autopilotDriveNotAu "VCFRONT_a609_autopilotDriveNotAuthed";
BA_ "SystemSignalLongSymbol" SG_ 832 VCFRONT_a610_frunkOpenFailureMet "VCFRONT_a610_frunkOpenFailureMetricSet";
BA_ "SystemSignalLongSymbol" SG_ 832 VCFRONT_a611_poorRadiatorHeatRej "VCFRONT_a611_poorRadiatorHeatRejection";
BA_ "SystemSignalLongSymbol" SG_ 832 VCFRONT_a613_selfTestsBlockingDr "VCFRONT_a613_selfTestsBlockingDrive";
BA_ "SystemSignalLongSymbol" SG_ 832 VCFRONT_a614_coolantSysDriverles "VCFRONT_a614_coolantSysDriverlessSelfTest";
BA_ "SystemSignalLongSymbol" SG_ 832 VCFRONT_a615_TLVBMS_BatteryHeate "VCFRONT_a615_TLVBMS_BatteryHeaterFault";
BA_ "SystemSignalLongSymbol" SG_ 832 VCFRONT_a618_cabinCoolingCapacit "VCFRONT_a618_cabinCoolingCapacityLimited";
BA_ "SystemSignalLongSymbol" SG_ 832 VCFRONT_a619_frunkSwitchReleaseT "VCFRONT_a619_frunkSwitchReleaseTimeDBG";
BA_ "SystemSignalLongSymbol" SG_ 832 VCFRONT_a621_coolantAirPurgeInco "VCFRONT_a621_coolantAirPurgeIncomplete";
BA_ "SystemSignalLongSymbol" SG_ 832 VCFRONT_a622_pumpDetectsLowCoola "VCFRONT_a622_pumpDetectsLowCoolantFlow";
BA_ "SystemSignalLongSymbol" SG_ 832 VCFRONT_a624_rightHeadlampIntern "VCFRONT_a624_rightHeadlampInternalErrorV4";
BA_ "SystemSignalLongSymbol" SG_ 832 VCFRONT_a625_leftHeadlampInterna "VCFRONT_a625_leftHeadlampInternalErrorV4";
BA_ "SystemSignalLongSymbol" SG_ 832 VCFRONT_a626_LVBatteryResistance "VCFRONT_a626_LVBatteryResistanceIncrease";
BA_ "SystemSignalLongSymbol" SG_ 832 VCFRONT_a627_LVBatteryUnrecovera "VCFRONT_a627_LVBatteryUnrecoverableByAnyDevice";
BA_ "SystemSignalLongSymbol" SG_ 832 VCFRONT_a628_TLVBMS_BmbThermisto "VCFRONT_a628_TLVBMS_BmbThermistorFault";
BA_ "SystemSignalLongSymbol" SG_ 832 VCFRONT_a629_TLVBMS_PackTemperat "VCFRONT_a629_TLVBMS_PackTemperatureIrrational";
BA_ "SystemSignalLongSymbol" SG_ 832 VCFRONT_a630_leftHeadlampFactory "VCFRONT_a630_leftHeadlampFactoryFault";
BA_ "SystemSignalLongSymbol" SG_ 832 VCFRONT_a631_rightHeadlampFactor "VCFRONT_a631_rightHeadlampFactoryFault";
BA_ "SystemSignalLongSymbol" SG_ 832 VCFRONT_a634_indeterminateSwitch "VCFRONT_a634_indeterminateSwitchTransitionDetectedDbg";
BA_ "SystemSignalLongSymbol" SG_ 832 VCFRONT_d636_ptCoolantPumpDetect "VCFRONT_d636_ptCoolantPumpDetectsAirInSystem";
BA_ "SystemSignalLongSymbol" SG_ 832 VCFRONT_d637_battCoolantPumpDete "VCFRONT_d637_battCoolantPumpDetectsAirInSystem";
BA_ "SystemSignalLongSymbol" SG_ 832 VCFRONT_d638_ptCoolantTempSensor "VCFRONT_d638_ptCoolantTempSensorIssue";
BA_ "SystemSignalLongSymbol" SG_ 832 VCFRONT_d639_batteryCoolantTempS "VCFRONT_d639_batteryCoolantTempSensorIssue";
BA_ "SystemSignalLongSymbol" SG_ 832 VCFRONT_d640_firmwareVersionMism "VCFRONT_d640_firmwareVersionMismatch";
BA_ "SystemSignalLongSymbol" SG_ 832 VCFRONT_d641_ptCoolantPumpCircui "VCFRONT_d641_ptCoolantPumpCircuitOpen";
BA_ "SystemSignalLongSymbol" SG_ 832 VCFRONT_d642_batteryCoolantPumpC "VCFRONT_d642_batteryCoolantPumpCircuitOpen";
BA_ "SystemSignalLongSymbol" SG_ 832 VCFRONT_a643_rightHeadlampUartCo "VCFRONT_a643_rightHeadlampUartCondition";
BA_ "SystemSignalLongSymbol" SG_ 832 VCFRONT_a644_washPumpHealthCalcu "VCFRONT_a644_washPumpHealthCalculationDbg0";
BA_ "SystemSignalLongSymbol" SG_ 832 VCFRONT_a645_washPumpHealthCalcu "VCFRONT_a645_washPumpHealthCalculationDbg1";
BA_ "SystemSignalLongSymbol" SG_ 832 VCFRONT_a646_washPumpHealthCalcu "VCFRONT_a646_washPumpHealthCalculationDbg2";
BA_ "SystemSignalLongSymbol" SG_ 832 VCFRONT_a649_persistAccPortPower "VCFRONT_a649_persistAccPortPowerReqOverridden";
BA_ "SystemSignalLongSymbol" SG_ 832 VCFRONT_d652_ptCoolantPumpCircui "VCFRONT_d652_ptCoolantPumpCircuitIssue";
BA_ "SystemSignalLongSymbol" SG_ 832 VCFRONT_d653_ptCoolantPumpCommLo "VCFRONT_d653_ptCoolantPumpCommLost";
BA_ "SystemSignalLongSymbol" SG_ 832 VCFRONT_d654_batteryCoolantPumpS "VCFRONT_d654_batteryCoolantPumpStall";
BA_ "SystemSignalLongSymbol" SG_ 832 VCFRONT_d655_batteryCoolantPumpC "VCFRONT_d655_batteryCoolantPumpCircuitIssue";
BA_ "SystemSignalLongSymbol" SG_ 832 VCFRONT_d656_batteryCoolantPumpC "VCFRONT_d656_batteryCoolantPumpCommLost";
BA_ "SystemSignalLongSymbol" SG_ 832 VCFRONT_d657_radiatorFanOperatio "VCFRONT_d657_radiatorFanOperationIssue";
BA_ "SystemSignalLongSymbol" SG_ 832 VCFRONT_d658_radiatorFanCircuitI "VCFRONT_d658_radiatorFanCircuitIssue";
BA_ "SystemSignalLongSymbol" SG_ 832 VCFRONT_d660_coolantValveCircuit "VCFRONT_d660_coolantValveCircuitIssue";
BA_ "SystemSignalLongSymbol" SG_ 832 VCFRONT_a661_mculessLeftHeadlamp "VCFRONT_a661_mculessLeftHeadlampCurrentAlertDbg";
BA_ "SystemSignalLongSymbol" SG_ 832 VCFRONT_a662_mculessRightHeadlam "VCFRONT_a662_mculessRightHeadlampCurrentAlertDbg";
BA_ "SystemSignalLongSymbol" SG_ 832 VCFRONT_a663_leftHeadlampUartWat "VCFRONT_a663_leftHeadlampUartWaterMarkWarning";
BA_ "SystemSignalLongSymbol" SG_ 832 VCFRONT_a664_rightHeadlampUartWa "VCFRONT_a664_rightHeadlampUartWaterMarkWarning";
BA_ "SystemSignalLongSymbol" SG_ 832 VCFRONT_a665_leftHeadlampRetryIn "VCFRONT_a665_leftHeadlampRetryInfo";
BA_ "SystemSignalLongSymbol" SG_ 832 VCFRONT_a666_rightHeadlampRetryI "VCFRONT_a666_rightHeadlampRetryInfo";
BA_ "SystemSignalLongSymbol" SG_ 832 VCFRONT_a667_leftHeadlampRegionO "VCFRONT_a667_leftHeadlampRegionOrSideMismatch";
BA_ "SystemSignalLongSymbol" SG_ 832 VCFRONT_a668_rightHeadlampRegion "VCFRONT_a668_rightHeadlampRegionOrSideMismatch";
BA_ "SystemSignalLongSymbol" SG_ 832 VCFRONT_a669_thermalHVPowerBudge "VCFRONT_a669_thermalHVPowerBudgetActive";
BA_ "SystemSignalLongSymbol" SG_ 832 VCFRONT_a670_TLVBMS_EfuseStateIr "VCFRONT_a670_TLVBMS_EfuseStateIrrational";
BA_ "SystemSignalLongSymbol" SG_ 832 VCFRONT_a671_powerConsumptionInf "VCFRONT_a671_powerConsumptionInfo";
BA_ "SystemSignalLongSymbol" SG_ 832 VCFRONT_d674_portExpanderService "VCFRONT_d674_portExpanderServiceRequired";
BA_ "SystemSignalLongSymbol" SG_ 832 VCFRONT_a697_leftHeadlampNotAime "VCFRONT_a697_leftHeadlampNotAimed";
BA_ "SystemSignalLongSymbol" SG_ 832 VCFRONT_a698_rightHeadlampNotAim "VCFRONT_a698_rightHeadlampNotAimed";
BA_ "SystemSignalLongSymbol" SG_ 832 VCFRONT_a702_dynamicHeadlightLev "VCFRONT_a702_dynamicHeadlightLevelingUnavailable";
BA_ "Confidence" SG_ 577 VCFRONT_coolantFlowBatActual 1;
BA_ "Confidence" SG_ 577 VCFRONT_coolantFlowBatTarget 1;
BA_ "Confidence" SG_ 577 VCFRONT_coolantFlowBatReason 1;
BA_ "Confidence" SG_ 577 VCFRONT_coolantFlowPTActual 1;
BA_ "Confidence" SG_ 577 VCFRONT_coolantFlowPTTarget 1;
BA_ "Confidence" SG_ 577 VCFRONT_coolantFlowPTReason 1;
BA_ "Confidence" SG_ 577 VCFRONT_wasteHeatRequestType 1;
BA_ "Confidence" SG_ 577 VCFRONT_radiatorIneffective 1;
BA_ "Confidence" SG_ 577 VCFRONT_coolantAirPurgeBatState 1;
BA_ "Confidence" SG_ 577 VCFRONT_coolantFlowTableConfig 1;
BA_ "SystemSignalLongSymbol" SG_ 577 VCFRONT_coolantLevelContinuously "VCFRONT_coolantLevelContinuouslyLow";
BA_ "Confidence" SG_ 753 VCFRONT_leftControllerState 1;
BA_ "Confidence" SG_ 753 VCFRONT_vcleftSelfTestResult 1;
BA_ "Confidence" SG_ 753 VCFRONT_leftControllerTemp 1;
BA_ "Confidence" SG_ 753 VCFRONT_leftControllerEFuseVNFSt 1;
BA_ "SystemSignalLongSymbol" SG_ 753 VCFRONT_leftControllerEFuseVNFSt "VCFRONT_leftControllerEFuseVNFState";
BA_ "Confidence" SG_ 753 VCFRONT_leftControllerEFuseOutpu 1;
BA_ "SystemSignalLongSymbol" SG_ 753 VCFRONT_leftControllerEFuseOutpu "VCFRONT_leftControllerEFuseOutput";
BA_ "Confidence" SG_ 753 VCFRONT_leftControllerEFuse_0002 1;
BA_ "SystemSignalLongSymbol" SG_ 753 VCFRONT_leftControllerEFuse_0002 "VCFRONT_leftControllerEFuseOutputDesired";
BA_ "Confidence" SG_ 753 VCFRONT_leftControllerVoltage 1;
BA_ "Confidence" SG_ 753 VCFRONT_leftControllerEFuseBypas 1;
BA_ "SystemSignalLongSymbol" SG_ 753 VCFRONT_leftControllerEFuseBypas "VCFRONT_leftControllerEFuseBypass";
BA_ "Confidence" SG_ 753 VCFRONT_leftControllerEFuse_0001 1;
BA_ "SystemSignalLongSymbol" SG_ 753 VCFRONT_leftControllerEFuse_0001 "VCFRONT_leftControllerEFuseBypassDesired";
BA_ "Confidence" SG_ 753 VCFRONT_leftControllerCurrent 1;
BA_ "Confidence" SG_ 753 VCFRONT_leftControllerEFuseVNFSe 1;
BA_ "SystemSignalLongSymbol" SG_ 753 VCFRONT_leftControllerEFuseVNFSe "VCFRONT_leftControllerEFuseVNFSelfTestStatus";
BA_ "Confidence" SG_ 753 VCFRONT_PCSState 1;
BA_ "Confidence" SG_ 753 VCFRONT_pcsSelfTestResult 1;
BA_ "Confidence" SG_ 753 VCFRONT_PCSTemp 1;
BA_ "Confidence" SG_ 753 VCFRONT_PCSEFuseVNFState 1;
BA_ "Confidence" SG_ 753 VCFRONT_PCSEFuseOutput 1;
BA_ "Confidence" SG_ 753 VCFRONT_PCSEFuseOutputDesired 1;
BA_ "Confidence" SG_ 753 VCFRONT_PCSVoltage 1;
BA_ "Confidence" SG_ 753 VCFRONT_PCSEFuseBypass 1;
BA_ "Confidence" SG_ 753 VCFRONT_PCSEFuseBypassDesired 1;
BA_ "Confidence" SG_ 753 VCFRONT_PCSEFuseVNFSelfTestStatu 1;
BA_ "SystemSignalLongSymbol" SG_ 753 VCFRONT_PCSEFuseVNFSelfTestStatu "VCFRONT_PCSEFuseVNFSelfTestStatus";
BA_ "Confidence" SG_ 753 VCFRONT_iBoosterState 1;
BA_ "Confidence" SG_ 753 VCFRONT_iBoosterSelfTestResult 1;
BA_ "Confidence" SG_ 753 VCFRONT_iBoosterTemp 1;
BA_ "Confidence" SG_ 753 VCFRONT_iBoosterEFuseVNFState 1;
BA_ "Confidence" SG_ 753 VCFRONT_iBoosterEFuseOutput 1;
BA_ "Confidence" SG_ 753 VCFRONT_iBoosterEFuseOutputDesir 1;
BA_ "SystemSignalLongSymbol" SG_ 753 VCFRONT_iBoosterEFuseOutputDesir "VCFRONT_iBoosterEFuseOutputDesired";
BA_ "Confidence" SG_ 753 VCFRONT_iBoosterVoltage 1;
BA_ "Confidence" SG_ 753 VCFRONT_iBoosterHardshortThresho 1;
BA_ "SystemSignalLongSymbol" SG_ 753 VCFRONT_iBoosterHardshortThresho "VCFRONT_iBoosterHardshortThresholdDbg";
BA_ "Confidence" SG_ 753 VCFRONT_iBoosterEFuseBypass 1;
BA_ "Confidence" SG_ 753 VCFRONT_iBoosterEFuseBypassDesir 1;
BA_ "SystemSignalLongSymbol" SG_ 753 VCFRONT_iBoosterEFuseBypassDesir "VCFRONT_iBoosterEFuseBypassDesired";
BA_ "Confidence" SG_ 753 VCFRONT_iBoosterCurrent 1;
BA_ "Confidence" SG_ 753 VCFRONT_iBoosterEFuseVNFSelfTest 1;
BA_ "SystemSignalLongSymbol" SG_ 753 VCFRONT_iBoosterEFuseVNFSelfTest "VCFRONT_iBoosterEFuseVNFSelfTestStatus";
BA_ "Confidence" SG_ 753 VCFRONT_EPAS3PState 1;
BA_ "Confidence" SG_ 753 VCFRONT_EPAS3PSelfTestResult 1;
BA_ "Confidence" SG_ 753 VCFRONT_EPAS3PTemp 1;
BA_ "Confidence" SG_ 753 VCFRONT_EPAS3PEFuseVNFState 1;
BA_ "Confidence" SG_ 753 VCFRONT_EPAS3PEFuseOutput 1;
BA_ "Confidence" SG_ 753 VCFRONT_EPAS3PEFuseOutputDesired 1;
BA_ "Confidence" SG_ 753 VCFRONT_EPAS3PVoltage 1;
BA_ "Confidence" SG_ 753 VCFRONT_EPAS3PEFuseHardshortThre 1;
BA_ "SystemSignalLongSymbol" SG_ 753 VCFRONT_EPAS3PEFuseHardshortThre "VCFRONT_EPAS3PEFuseHardshortThresholdDbg";
BA_ "Confidence" SG_ 753 VCFRONT_EPAS3PEFuseBypass 1;
BA_ "Confidence" SG_ 753 VCFRONT_EPAS3PEFuseBypassDesired 1;
BA_ "Confidence" SG_ 753 VCFRONT_EPAS3PCurrent 1;
BA_ "Confidence" SG_ 753 VCFRONT_EPAS3PEFuseVNFSelfTestSt 1;
BA_ "SystemSignalLongSymbol" SG_ 753 VCFRONT_EPAS3PEFuseVNFSelfTestSt "VCFRONT_EPAS3PEFuseVNFSelfTestStatus";
BA_ "Confidence" SG_ 753 VCFRONT_EPAS3SState 1;
BA_ "Confidence" SG_ 753 VCFRONT_EPAS3SSelfTestResult 1;
BA_ "Confidence" SG_ 753 VCFRONT_EPAS3STemp 1;
BA_ "Confidence" SG_ 753 VCFRONT_EPAS3SEFuseVNFState 1;
BA_ "Confidence" SG_ 753 VCFRONT_EPAS3SEFuseOutput 1;
BA_ "Confidence" SG_ 753 VCFRONT_EPAS3SEFuseOutputDesired 1;
BA_ "Confidence" SG_ 753 VCFRONT_EPAS3SVoltage 1;
BA_ "Confidence" SG_ 753 VCFRONT_EPAS3SEFuseBypass 1;
BA_ "Confidence" SG_ 753 VCFRONT_EPAS3SEFuseBypassDesired 1;
BA_ "Confidence" SG_ 753 VCFRONT_EPAS3SCurrent 1;
BA_ "Confidence" SG_ 753 VCFRONT_EPAS3SEFuseVNFSelfTestSt 1;
BA_ "SystemSignalLongSymbol" SG_ 753 VCFRONT_EPAS3SEFuseVNFSelfTestSt "VCFRONT_EPAS3SEFuseVNFSelfTestStatus";
BA_ "Confidence" SG_ 753 VCFRONT_ESPMotorState 1;
BA_ "Confidence" SG_ 753 VCFRONT_ESPMotorSelfTestResult 1;
BA_ "Confidence" SG_ 753 VCFRONT_ESPMotorTemp 1;
BA_ "Confidence" SG_ 753 VCFRONT_ESPMotorEFuseVNFState 1;
BA_ "Confidence" SG_ 753 VCFRONT_ESPMotorEFuseOutput 1;
BA_ "Confidence" SG_ 753 VCFRONT_ESPMotorEFuseOutputDesir 1;
BA_ "SystemSignalLongSymbol" SG_ 753 VCFRONT_ESPMotorEFuseOutputDesir "VCFRONT_ESPMotorEFuseOutputDesired";
BA_ "Confidence" SG_ 753 VCFRONT_ESPMotorVoltage 1;
BA_ "Confidence" SG_ 753 VCFRONT_ESPMotorEFuseBypass 1;
BA_ "Confidence" SG_ 753 VCFRONT_ESPMotorEFuseBypassDesir 1;
BA_ "SystemSignalLongSymbol" SG_ 753 VCFRONT_ESPMotorEFuseBypassDesir "VCFRONT_ESPMotorEFuseBypassDesired";
BA_ "Confidence" SG_ 753 VCFRONT_ESPMotorCurrent 1;
BA_ "Confidence" SG_ 753 VCFRONT_ESPMotorEFuseVNFSelfTest 1;
BA_ "SystemSignalLongSymbol" SG_ 753 VCFRONT_ESPMotorEFuseVNFSelfTest "VCFRONT_ESPMotorEFuseVNFSelfTestStatus";
BA_ "Confidence" SG_ 753 VCFRONT_ESPValveState 1;
BA_ "Confidence" SG_ 753 VCFRONT_ESPValveTemp 1;
BA_ "Confidence" SG_ 753 VCFRONT_ESPValveVoltage 1;
BA_ "Confidence" SG_ 753 VCFRONT_ESPValveCurrent 1;
BA_ "Confidence" SG_ 753 VCFRONT_autopilot2State 1;
BA_ "Confidence" SG_ 753 VCFRONT_autopilot2Temp 1;
BA_ "Confidence" SG_ 753 VCFRONT_autopilot2Voltage 1;
BA_ "Confidence" SG_ 753 VCFRONT_autopilot2Current 1;
BA_ "Confidence" SG_ 753 VCFRONT_sleepBypassState 1;
BA_ "Confidence" SG_ 753 VCFRONT_sleepBypassVoltage 1;
BA_ "Confidence" SG_ 753 VCFRONT_sleepBypassCurrent 1;
BA_ "Confidence" SG_ 753 VCFRONT_vbatFusedSelfTestResult 1;
BA_ "Confidence" SG_ 753 VCFRONT_vbatFusedHighTemp 1;
BA_ "Confidence" SG_ 753 VCFRONT_vbatFusedHighVoltage 1;
BA_ "Confidence" SG_ 753 VCFRONT_vbatFusedHighCurrent 1;
BA_ "Confidence" SG_ 753 VCFRONT_chargedIBSAmpHours 1;
BA_ "Confidence" SG_ 753 VCFRONT_dischargedIBSAmpHours 1;
BA_ "Confidence" SG_ 753 VCFRONT_IBSUnfilteredTemperature 1;
BA_ "Confidence" SG_ 2016 VCFRONT_homelinkCommStatus 1;
BA_ "Confidence" SG_ 769 VCFRONT_infoBuildType 1;
BA_ "Confidence" SG_ 1014 VCFRONT_lowBeamLeftStatus 1;
BA_ "Confidence" SG_ 1014 VCFRONT_lowBeamRightStatus 1;
BA_ "Confidence" SG_ 1014 VCFRONT_highBeamLeftStatus 1;
BA_ "Confidence" SG_ 1014 VCFRONT_highBeamRightStatus 1;
BA_ "Confidence" SG_ 1014 VCFRONT_DRLLeftStatus 1;
BA_ "Confidence" SG_ 1014 VCFRONT_DRLRightStatus 1;
BA_ "Confidence" SG_ 1014 VCFRONT_fogLeftStatus 1;
BA_ "Confidence" SG_ 1014 VCFRONT_fogRightStatus 1;
BA_ "Confidence" SG_ 1014 VCFRONT_sideMarkersStatus 1;
BA_ "Confidence" SG_ 1014 VCFRONT_sideRepeaterLeftStatus 1;
BA_ "Confidence" SG_ 1014 VCFRONT_sideRepeaterRightStatus 1;
BA_ "Confidence" SG_ 1014 VCFRONT_turnSignalLeftStatus 1;
BA_ "Confidence" SG_ 1014 VCFRONT_turnSignalRightStatus 1;
BA_ "Confidence" SG_ 1014 VCFRONT_parkLeftStatus 1;
BA_ "Confidence" SG_ 1014 VCFRONT_parkRightStatus 1;
BA_ "SystemSignalLongSymbol" SG_ 1014 VCFRONT_lowBeamLeftReadyForAimin "VCFRONT_lowBeamLeftReadyForAiming";
BA_ "SystemSignalLongSymbol" SG_ 1014 VCFRONT_lowBeamRightReadyForAimi "VCFRONT_lowBeamRightReadyForAiming";
BA_ "Confidence" SG_ 1014 VCFRONT_lowBeamsOnForDRL 1;
BA_ "Confidence" SG_ 1014 VC_rightHeadlampHealth 1;
BA_ "Confidence" SG_ 1014 VC_leftHeadlampHealth 1;
BA_ "Confidence" SG_ 1014 VCFRONT_isAdaptiveHighBeamAvaila 1;
BA_ "SystemSignalLongSymbol" SG_ 1014 VCFRONT_isAdaptiveHighBeamAvaila "VCFRONT_isAdaptiveHighBeamAvailable";
BA_ "Confidence" SG_ 1014 VCFRONT_isAdaptiveHighBeamFaulte 1;
BA_ "SystemSignalLongSymbol" SG_ 1014 VCFRONT_isAdaptiveHighBeamFaulte "VCFRONT_isAdaptiveHighBeamFaulted";
BA_ "Confidence" SG_ 1014 VCFRONT_isBendLightingAvailable 1;
BA_ "Confidence" SG_ 1014 VCFRONT_advancedDrivingBeamStatu 1;
BA_ "SystemSignalLongSymbol" SG_ 1014 VCFRONT_advancedDrivingBeamStatu "VCFRONT_advancedDrivingBeamStatus";
BA_ "Confidence" SG_ 1014 VCFRONT_headlampBendAngle 1;
BA_ "Confidence" SG_ 1014 VCFRONT_headlampRoadClass 1;
VAL_ 577 VCFRONT_coolantFlowBatReason 21 "AP_AIR_PURGE" 20 "DRIVERLESS_SELF_TEST" 19 "BATTERY_DISCHARGE_FLOW_REQ" 18 "DI_BURN_IN_FLOW_REQ" 17 "UI_FLOW_REQ" 16 "DI_PPR_FLOW_REQ" 15 "BMS_PPR_FLOW_REQ" 14 "HP_FLOW_REQ" 13 "DIS_FLOW_REQ" 12 "DI_FLOW_REQ" 11 "PCS_FLOW_REQ" 10 "PASSIVE_MANAGER_PT" 9 "ACTIVE_MANAGER_PT" 8 "OVERRIDE_PT" 7 "DAS_FLOW_REQ" 6 "BMS_FLOW_REQ" 5 "PASSIVE_MANAGER_BATT" 4 "ACTIVE_MANAGER_BATT" 3 "OVERRIDE_BATT" 2 "NO_FLOW_REQ" 1 "COOLANT_AIR_PURGE" 0 "NONE" ;
VAL_ 577 VCFRONT_coolantFlowPTReason 21 "AP_AIR_PURGE" 20 "DRIVERLESS_SELF_TEST" 19 "BATTERY_DISCHARGE_FLOW_REQ" 18 "DI_BURN_IN_FLOW_REQ" 17 "UI_FLOW_REQ" 16 "DI_PPR_FLOW_REQ" 15 "BMS_PPR_FLOW_REQ" 14 "HP_FLOW_REQ" 13 "DIS_FLOW_REQ" 12 "DI_FLOW_REQ" 11 "PCS_FLOW_REQ" 10 "PASSIVE_MANAGER_PT" 9 "ACTIVE_MANAGER_PT" 8 "OVERRIDE_PT" 7 "DAS_FLOW_REQ" 6 "BMS_FLOW_REQ" 5 "PASSIVE_MANAGER_BATT" 4 "ACTIVE_MANAGER_BATT" 3 "OVERRIDE_BATT" 2 "NO_FLOW_REQ" 1 "COOLANT_AIR_PURGE" 0 "NONE" ;
VAL_ 577 VCFRONT_wasteHeatRequestType 3 "WASTE_TYPE_BURN_IN" 2 "WASTE_TYPE_FULL" 1 "WASTE_TYPE_PARTIAL" 0 "WASTE_TYPE_NONE" ;
VAL_ 577 VCFRONT_coolantAirPurgeBatState 4 "AIR_PURGE_STATE_PENDING" 3 "AIR_PURGE_STATE_INTERRUPTED" 2 "AIR_PURGE_STATE_COMPLETE" 1 "AIR_PURGE_STATE_ACTIVE" 0 "AIR_PURGE_STATE_INACTIVE" ;
VAL_ 577 VCFRONT_coolantFlowTableConfig 1 "FLOW_TABLE_CONFIG_BMS_TYPE_5" 0 "FLOW_TABLE_CONFIG_DEFAULT" ;
VAL_ 753 VCFRONT_leftControllerState 3 "EFUSE_STATE_SNA" 2 "EFUSE_STATE_LOCKED_OUT" 1 "EFUSE_STATE_ON" 0 "EFUSE_STATE_OFF" ;
VAL_ 753 VCFRONT_vcleftSelfTestResult 12 "EFUSE_SELF_TEST_EFUSE_RESULT_SNA" 11 "EFUSE_SELF_TEST_EFUSE_RESULT_SKIPPED" 10 "EFUSE_SELF_TEST_EFUSE_RESULT_FAILED_NOT_LATCHED" 9 "EFUSE_SELF_TEST_EFUSE_RESULT_FAILED_TURN_OFF_PATH_TOO_SLOW" 8 "EFUSE_SELF_TEST_EFUSE_RESULT_FAILED_ENABLE_HIGH_MALFUNCTION" 7 "EFUSE_SELF_TEST_EFUSE_RESULT_FAILED_POWER_FET_CHANNEL_OPEN" 6 "EFUSE_SELF_TEST_EFUSE_RESULT_FAILED_ENABLE_LOW_MALFUNCTION" 5 "EFUSE_SELF_TEST_EFUSE_RESULT_FAILED_POWER_FET_STUCK_ON" 4 "EFUSE_SELF_TEST_EFUSE_RESULT_FAILED_EFUSE_OUTPUT_SHORT" 3 "EFUSE_SELF_TEST_EFUSE_RESULT_FAILED_RAILS_UNSTABLE" 2 "EFUSE_SELF_TEST_EFUSE_RESULT_PASSED" 1 "EFUSE_SELF_TEST_EFUSE_RESULT_RUNNING" 0 "EFUSE_SELF_TEST_EFUSE_RESULT_NOT_RUN" ;
VAL_ 753 VCFRONT_leftControllerEFuseVNFSt 7 "EFUSE_ASIC_STATE_SELF_TEST" 6 "EFUSE_ASIC_STATE_SELF_TEST_PREP" 5 "EFUSE_ASIC_STATE_LOCKED" 4 "EFUSE_ASIC_STATE_UNLOCKED" 3 "EFUSE_ASIC_STATE_CONFIGURATION" 2 "EFUSE_ASIC_STATE_WAKEUP" 1 "EFUSE_ASIC_STATE_STANDBY" 0 "EFUSE_ASIC_STATE_UNKNOWN" ;
VAL_ 753 VCFRONT_leftControllerEFuseVNFSe 3 "EFUSE_SELF_TEST_SKIPPED" 2 "EFUSE_SELF_TEST_COMPLETE" 1 "EFUSE_SELF_TEST_ACTIVE" 0 "EFUSE_SELF_TEST_NOT_COMPLETE" ;
VAL_ 753 VCFRONT_PCSState 3 "EFUSE_STATE_SNA" 2 "EFUSE_STATE_LOCKED_OUT" 1 "EFUSE_STATE_ON" 0 "EFUSE_STATE_OFF" ;
VAL_ 753 VCFRONT_pcsSelfTestResult 12 "EFUSE_SELF_TEST_EFUSE_RESULT_SNA" 11 "EFUSE_SELF_TEST_EFUSE_RESULT_SKIPPED" 10 "EFUSE_SELF_TEST_EFUSE_RESULT_FAILED_NOT_LATCHED" 9 "EFUSE_SELF_TEST_EFUSE_RESULT_FAILED_TURN_OFF_PATH_TOO_SLOW" 8 "EFUSE_SELF_TEST_EFUSE_RESULT_FAILED_ENABLE_HIGH_MALFUNCTION" 7 "EFUSE_SELF_TEST_EFUSE_RESULT_FAILED_POWER_FET_CHANNEL_OPEN" 6 "EFUSE_SELF_TEST_EFUSE_RESULT_FAILED_ENABLE_LOW_MALFUNCTION" 5 "EFUSE_SELF_TEST_EFUSE_RESULT_FAILED_POWER_FET_STUCK_ON" 4 "EFUSE_SELF_TEST_EFUSE_RESULT_FAILED_EFUSE_OUTPUT_SHORT" 3 "EFUSE_SELF_TEST_EFUSE_RESULT_FAILED_RAILS_UNSTABLE" 2 "EFUSE_SELF_TEST_EFUSE_RESULT_PASSED" 1 "EFUSE_SELF_TEST_EFUSE_RESULT_RUNNING" 0 "EFUSE_SELF_TEST_EFUSE_RESULT_NOT_RUN" ;
VAL_ 753 VCFRONT_PCSEFuseVNFState 7 "EFUSE_ASIC_STATE_SELF_TEST" 6 "EFUSE_ASIC_STATE_SELF_TEST_PREP" 5 "EFUSE_ASIC_STATE_LOCKED" 4 "EFUSE_ASIC_STATE_UNLOCKED" 3 "EFUSE_ASIC_STATE_CONFIGURATION" 2 "EFUSE_ASIC_STATE_WAKEUP" 1 "EFUSE_ASIC_STATE_STANDBY" 0 "EFUSE_ASIC_STATE_UNKNOWN" ;
VAL_ 753 VCFRONT_PCSEFuseVNFSelfTestStatu 3 "EFUSE_SELF_TEST_SKIPPED" 2 "EFUSE_SELF_TEST_COMPLETE" 1 "EFUSE_SELF_TEST_ACTIVE" 0 "EFUSE_SELF_TEST_NOT_COMPLETE" ;
VAL_ 753 VCFRONT_iBoosterState 3 "EFUSE_STATE_SNA" 2 "EFUSE_STATE_LOCKED_OUT" 1 "EFUSE_STATE_ON" 0 "EFUSE_STATE_OFF" ;
VAL_ 753 VCFRONT_iBoosterSelfTestResult 12 "EFUSE_SELF_TEST_EFUSE_RESULT_SNA" 11 "EFUSE_SELF_TEST_EFUSE_RESULT_SKIPPED" 10 "EFUSE_SELF_TEST_EFUSE_RESULT_FAILED_NOT_LATCHED" 9 "EFUSE_SELF_TEST_EFUSE_RESULT_FAILED_TURN_OFF_PATH_TOO_SLOW" 8 "EFUSE_SELF_TEST_EFUSE_RESULT_FAILED_ENABLE_HIGH_MALFUNCTION" 7 "EFUSE_SELF_TEST_EFUSE_RESULT_FAILED_POWER_FET_CHANNEL_OPEN" 6 "EFUSE_SELF_TEST_EFUSE_RESULT_FAILED_ENABLE_LOW_MALFUNCTION" 5 "EFUSE_SELF_TEST_EFUSE_RESULT_FAILED_POWER_FET_STUCK_ON" 4 "EFUSE_SELF_TEST_EFUSE_RESULT_FAILED_EFUSE_OUTPUT_SHORT" 3 "EFUSE_SELF_TEST_EFUSE_RESULT_FAILED_RAILS_UNSTABLE" 2 "EFUSE_SELF_TEST_EFUSE_RESULT_PASSED" 1 "EFUSE_SELF_TEST_EFUSE_RESULT_RUNNING" 0 "EFUSE_SELF_TEST_EFUSE_RESULT_NOT_RUN" ;
VAL_ 753 VCFRONT_iBoosterEFuseVNFState 7 "EFUSE_ASIC_STATE_SELF_TEST" 6 "EFUSE_ASIC_STATE_SELF_TEST_PREP" 5 "EFUSE_ASIC_STATE_LOCKED" 4 "EFUSE_ASIC_STATE_UNLOCKED" 3 "EFUSE_ASIC_STATE_CONFIGURATION" 2 "EFUSE_ASIC_STATE_WAKEUP" 1 "EFUSE_ASIC_STATE_STANDBY" 0 "EFUSE_ASIC_STATE_UNKNOWN" ;
VAL_ 753 VCFRONT_iBoosterHardshortThresho 15 "VNF1048_HSHT_160_MV" 14 "VNF1048_HSHT_139_3_MV" 13 "VNF1048_HSHT_121_3_MV" 12 "VNF1048_HSHT_105_6_MV" 11 "VNF1048_HSHT_91_9_MV" 10 "VNF1048_HSHT_80_MV" 9 "VNF1048_HSHT_69_6_MV" 8 "VNF1048_HSHT_60_6_MV" 7 "VNF1048_HSHT_52_8_MV" 6 "VNF1048_HSHT_45_9_MV" 5 "VNF1048_HSHT_40_MV" 4 "VNF1048_HSHT_34_8_MV" 3 "VNF1048_HSHT_30_3_MV" 2 "VNF1048_HSHT_26_4_MV" 1 "VNF1048_HSHT_23_MV" 0 "VNF1048_HSHT_20_MV" ;
VAL_ 753 VCFRONT_iBoosterEFuseVNFSelfTest 3 "EFUSE_SELF_TEST_SKIPPED" 2 "EFUSE_SELF_TEST_COMPLETE" 1 "EFUSE_SELF_TEST_ACTIVE" 0 "EFUSE_SELF_TEST_NOT_COMPLETE" ;
VAL_ 753 VCFRONT_EPAS3PState 3 "EFUSE_STATE_SNA" 2 "EFUSE_STATE_LOCKED_OUT" 1 "EFUSE_STATE_ON" 0 "EFUSE_STATE_OFF" ;
VAL_ 753 VCFRONT_EPAS3PSelfTestResult 12 "EFUSE_SELF_TEST_EFUSE_RESULT_SNA" 11 "EFUSE_SELF_TEST_EFUSE_RESULT_SKIPPED" 10 "EFUSE_SELF_TEST_EFUSE_RESULT_FAILED_NOT_LATCHED" 9 "EFUSE_SELF_TEST_EFUSE_RESULT_FAILED_TURN_OFF_PATH_TOO_SLOW" 8 "EFUSE_SELF_TEST_EFUSE_RESULT_FAILED_ENABLE_HIGH_MALFUNCTION" 7 "EFUSE_SELF_TEST_EFUSE_RESULT_FAILED_POWER_FET_CHANNEL_OPEN" 6 "EFUSE_SELF_TEST_EFUSE_RESULT_FAILED_ENABLE_LOW_MALFUNCTION" 5 "EFUSE_SELF_TEST_EFUSE_RESULT_FAILED_POWER_FET_STUCK_ON" 4 "EFUSE_SELF_TEST_EFUSE_RESULT_FAILED_EFUSE_OUTPUT_SHORT" 3 "EFUSE_SELF_TEST_EFUSE_RESULT_FAILED_RAILS_UNSTABLE" 2 "EFUSE_SELF_TEST_EFUSE_RESULT_PASSED" 1 "EFUSE_SELF_TEST_EFUSE_RESULT_RUNNING" 0 "EFUSE_SELF_TEST_EFUSE_RESULT_NOT_RUN" ;
VAL_ 753 VCFRONT_EPAS3PEFuseVNFState 7 "EFUSE_ASIC_STATE_SELF_TEST" 6 "EFUSE_ASIC_STATE_SELF_TEST_PREP" 5 "EFUSE_ASIC_STATE_LOCKED" 4 "EFUSE_ASIC_STATE_UNLOCKED" 3 "EFUSE_ASIC_STATE_CONFIGURATION" 2 "EFUSE_ASIC_STATE_WAKEUP" 1 "EFUSE_ASIC_STATE_STANDBY" 0 "EFUSE_ASIC_STATE_UNKNOWN" ;
VAL_ 753 VCFRONT_EPAS3PEFuseHardshortThre 15 "VNF1048_HSHT_160_MV" 14 "VNF1048_HSHT_139_3_MV" 13 "VNF1048_HSHT_121_3_MV" 12 "VNF1048_HSHT_105_6_MV" 11 "VNF1048_HSHT_91_9_MV" 10 "VNF1048_HSHT_80_MV" 9 "VNF1048_HSHT_69_6_MV" 8 "VNF1048_HSHT_60_6_MV" 7 "VNF1048_HSHT_52_8_MV" 6 "VNF1048_HSHT_45_9_MV" 5 "VNF1048_HSHT_40_MV" 4 "VNF1048_HSHT_34_8_MV" 3 "VNF1048_HSHT_30_3_MV" 2 "VNF1048_HSHT_26_4_MV" 1 "VNF1048_HSHT_23_MV" 0 "VNF1048_HSHT_20_MV" ;
VAL_ 753 VCFRONT_EPAS3PEFuseVNFSelfTestSt 3 "EFUSE_SELF_TEST_SKIPPED" 2 "EFUSE_SELF_TEST_COMPLETE" 1 "EFUSE_SELF_TEST_ACTIVE" 0 "EFUSE_SELF_TEST_NOT_COMPLETE" ;
VAL_ 753 VCFRONT_EPAS3SState 3 "EFUSE_STATE_SNA" 2 "EFUSE_STATE_LOCKED_OUT" 1 "EFUSE_STATE_ON" 0 "EFUSE_STATE_OFF" ;
VAL_ 753 VCFRONT_EPAS3SSelfTestResult 12 "EFUSE_SELF_TEST_EFUSE_RESULT_SNA" 11 "EFUSE_SELF_TEST_EFUSE_RESULT_SKIPPED" 10 "EFUSE_SELF_TEST_EFUSE_RESULT_FAILED_NOT_LATCHED" 9 "EFUSE_SELF_TEST_EFUSE_RESULT_FAILED_TURN_OFF_PATH_TOO_SLOW" 8 "EFUSE_SELF_TEST_EFUSE_RESULT_FAILED_ENABLE_HIGH_MALFUNCTION" 7 "EFUSE_SELF_TEST_EFUSE_RESULT_FAILED_POWER_FET_CHANNEL_OPEN" 6 "EFUSE_SELF_TEST_EFUSE_RESULT_FAILED_ENABLE_LOW_MALFUNCTION" 5 "EFUSE_SELF_TEST_EFUSE_RESULT_FAILED_POWER_FET_STUCK_ON" 4 "EFUSE_SELF_TEST_EFUSE_RESULT_FAILED_EFUSE_OUTPUT_SHORT" 3 "EFUSE_SELF_TEST_EFUSE_RESULT_FAILED_RAILS_UNSTABLE" 2 "EFUSE_SELF_TEST_EFUSE_RESULT_PASSED" 1 "EFUSE_SELF_TEST_EFUSE_RESULT_RUNNING" 0 "EFUSE_SELF_TEST_EFUSE_RESULT_NOT_RUN" ;
VAL_ 753 VCFRONT_EPAS3SEFuseVNFState 7 "EFUSE_ASIC_STATE_SELF_TEST" 6 "EFUSE_ASIC_STATE_SELF_TEST_PREP" 5 "EFUSE_ASIC_STATE_LOCKED" 4 "EFUSE_ASIC_STATE_UNLOCKED" 3 "EFUSE_ASIC_STATE_CONFIGURATION" 2 "EFUSE_ASIC_STATE_WAKEUP" 1 "EFUSE_ASIC_STATE_STANDBY" 0 "EFUSE_ASIC_STATE_UNKNOWN" ;
VAL_ 753 VCFRONT_EPAS3SEFuseVNFSelfTestSt 3 "EFUSE_SELF_TEST_SKIPPED" 2 "EFUSE_SELF_TEST_COMPLETE" 1 "EFUSE_SELF_TEST_ACTIVE" 0 "EFUSE_SELF_TEST_NOT_COMPLETE" ;
VAL_ 753 VCFRONT_ESPMotorState 3 "EFUSE_STATE_SNA" 2 "EFUSE_STATE_LOCKED_OUT" 1 "EFUSE_STATE_ON" 0 "EFUSE_STATE_OFF" ;
VAL_ 753 VCFRONT_ESPMotorSelfTestResult 12 "EFUSE_SELF_TEST_EFUSE_RESULT_SNA" 11 "EFUSE_SELF_TEST_EFUSE_RESULT_SKIPPED" 10 "EFUSE_SELF_TEST_EFUSE_RESULT_FAILED_NOT_LATCHED" 9 "EFUSE_SELF_TEST_EFUSE_RESULT_FAILED_TURN_OFF_PATH_TOO_SLOW" 8 "EFUSE_SELF_TEST_EFUSE_RESULT_FAILED_ENABLE_HIGH_MALFUNCTION" 7 "EFUSE_SELF_TEST_EFUSE_RESULT_FAILED_POWER_FET_CHANNEL_OPEN" 6 "EFUSE_SELF_TEST_EFUSE_RESULT_FAILED_ENABLE_LOW_MALFUNCTION" 5 "EFUSE_SELF_TEST_EFUSE_RESULT_FAILED_POWER_FET_STUCK_ON" 4 "EFUSE_SELF_TEST_EFUSE_RESULT_FAILED_EFUSE_OUTPUT_SHORT" 3 "EFUSE_SELF_TEST_EFUSE_RESULT_FAILED_RAILS_UNSTABLE" 2 "EFUSE_SELF_TEST_EFUSE_RESULT_PASSED" 1 "EFUSE_SELF_TEST_EFUSE_RESULT_RUNNING" 0 "EFUSE_SELF_TEST_EFUSE_RESULT_NOT_RUN" ;
VAL_ 753 VCFRONT_ESPMotorEFuseVNFState 7 "EFUSE_ASIC_STATE_SELF_TEST" 6 "EFUSE_ASIC_STATE_SELF_TEST_PREP" 5 "EFUSE_ASIC_STATE_LOCKED" 4 "EFUSE_ASIC_STATE_UNLOCKED" 3 "EFUSE_ASIC_STATE_CONFIGURATION" 2 "EFUSE_ASIC_STATE_WAKEUP" 1 "EFUSE_ASIC_STATE_STANDBY" 0 "EFUSE_ASIC_STATE_UNKNOWN" ;
VAL_ 753 VCFRONT_ESPMotorEFuseVNFSelfTest 3 "EFUSE_SELF_TEST_SKIPPED" 2 "EFUSE_SELF_TEST_COMPLETE" 1 "EFUSE_SELF_TEST_ACTIVE" 0 "EFUSE_SELF_TEST_NOT_COMPLETE" ;
VAL_ 753 VCFRONT_ESPValveState 3 "EFUSE_STATE_SNA" 2 "EFUSE_STATE_LOCKED_OUT" 1 "EFUSE_STATE_ON" 0 "EFUSE_STATE_OFF" ;
VAL_ 753 VCFRONT_autopilot2State 3 "EFUSE_STATE_SNA" 2 "EFUSE_STATE_LOCKED_OUT" 1 "EFUSE_STATE_ON" 0 "EFUSE_STATE_OFF" ;
VAL_ 753 VCFRONT_vbatFusedSelfTestResult 12 "EFUSE_SELF_TEST_EFUSE_RESULT_SNA" 11 "EFUSE_SELF_TEST_EFUSE_RESULT_SKIPPED" 10 "EFUSE_SELF_TEST_EFUSE_RESULT_FAILED_NOT_LATCHED" 9 "EFUSE_SELF_TEST_EFUSE_RESULT_FAILED_TURN_OFF_PATH_TOO_SLOW" 8 "EFUSE_SELF_TEST_EFUSE_RESULT_FAILED_ENABLE_HIGH_MALFUNCTION" 7 "EFUSE_SELF_TEST_EFUSE_RESULT_FAILED_POWER_FET_CHANNEL_OPEN" 6 "EFUSE_SELF_TEST_EFUSE_RESULT_FAILED_ENABLE_LOW_MALFUNCTION" 5 "EFUSE_SELF_TEST_EFUSE_RESULT_FAILED_POWER_FET_STUCK_ON" 4 "EFUSE_SELF_TEST_EFUSE_RESULT_FAILED_EFUSE_OUTPUT_SHORT" 3 "EFUSE_SELF_TEST_EFUSE_RESULT_FAILED_RAILS_UNSTABLE" 2 "EFUSE_SELF_TEST_EFUSE_RESULT_PASSED" 1 "EFUSE_SELF_TEST_EFUSE_RESULT_RUNNING" 0 "EFUSE_SELF_TEST_EFUSE_RESULT_NOT_RUN" ;
VAL_ 2016 VCFRONT_homelinkCommStatus 3 "HOMELINK_COMM_STATUS_FAULT" 2 "HOMELINK_COMM_STATUS_ON" 1 "HOMELINK_COMM_STATUS_OFF" 0 "HOMELINK_COMM_STATUS_SNA" ;
VAL_ 769 VCFRONT_infoBuildType 4 "INFO_MFG_BUILD" 3 "INFO_TRACEABLE_CI_BUILD" 2 "INFO_LOCAL_BUILD" 1 "INFO_PLATFORM_BUILD" 0 "INFO_UNKNOWN_BUILD" ;
VAL_ 1014 VCFRONT_lowBeamLeftStatus 3 "LIGHT_SNA" 2 "LIGHT_FAULT" 1 "LIGHT_ON" 0 "LIGHT_OFF" ;
VAL_ 1014 VCFRONT_lowBeamRightStatus 3 "LIGHT_SNA" 2 "LIGHT_FAULT" 1 "LIGHT_ON" 0 "LIGHT_OFF" ;
VAL_ 1014 VCFRONT_highBeamLeftStatus 3 "LIGHT_SNA" 2 "LIGHT_FAULT" 1 "LIGHT_ON" 0 "LIGHT_OFF" ;
VAL_ 1014 VCFRONT_highBeamRightStatus 3 "LIGHT_SNA" 2 "LIGHT_FAULT" 1 "LIGHT_ON" 0 "LIGHT_OFF" ;
VAL_ 1014 VCFRONT_DRLLeftStatus 3 "LIGHT_SNA" 2 "LIGHT_FAULT" 1 "LIGHT_ON" 0 "LIGHT_OFF" ;
VAL_ 1014 VCFRONT_DRLRightStatus 3 "LIGHT_SNA" 2 "LIGHT_FAULT" 1 "LIGHT_ON" 0 "LIGHT_OFF" ;
VAL_ 1014 VCFRONT_fogLeftStatus 3 "LIGHT_SNA" 2 "LIGHT_FAULT" 1 "LIGHT_ON" 0 "LIGHT_OFF" ;
VAL_ 1014 VCFRONT_fogRightStatus 3 "LIGHT_SNA" 2 "LIGHT_FAULT" 1 "LIGHT_ON" 0 "LIGHT_OFF" ;
VAL_ 1014 VCFRONT_sideMarkersStatus 3 "LIGHT_SNA" 2 "LIGHT_FAULT" 1 "LIGHT_ON" 0 "LIGHT_OFF" ;
VAL_ 1014 VCFRONT_sideRepeaterLeftStatus 3 "LIGHT_SNA" 2 "LIGHT_FAULT" 1 "LIGHT_ON" 0 "LIGHT_OFF" ;
VAL_ 1014 VCFRONT_sideRepeaterRightStatus 3 "LIGHT_SNA" 2 "LIGHT_FAULT" 1 "LIGHT_ON" 0 "LIGHT_OFF" ;
VAL_ 1014 VCFRONT_turnSignalLeftStatus 3 "LIGHT_SNA" 2 "LIGHT_FAULT" 1 "LIGHT_ON" 0 "LIGHT_OFF" ;
VAL_ 1014 VCFRONT_turnSignalRightStatus 3 "LIGHT_SNA" 2 "LIGHT_FAULT" 1 "LIGHT_ON" 0 "LIGHT_OFF" ;
VAL_ 1014 VCFRONT_parkLeftStatus 3 "LIGHT_SNA" 2 "LIGHT_FAULT" 1 "LIGHT_ON" 0 "LIGHT_OFF" ;
VAL_ 1014 VCFRONT_parkRightStatus 3 "LIGHT_SNA" 2 "LIGHT_FAULT" 1 "LIGHT_ON" 0 "LIGHT_OFF" ;
VAL_ 1014 VC_rightHeadlampHealth 7 "SMART_LIGHT_HEALTH_RESERVED" 6 "SMART_LIGHT_HEALTH_UPDATING" 5 "SMART_LIGHT_HEALTH_NOT_CONFIGURED" 4 "SMART_LIGHT_HEALTH_COMMS_OK_NO_LIGHT" 3 "SMART_LIGHT_HEALTH_OK" 2 "SMART_LIGHT_HEALTH_TIMEOUT" 1 "SMART_LIGHT_HEALTH_WAIT" 0 "SMART_LIGHT_HEALTH_OFF" ;
VAL_ 1014 VC_leftHeadlampHealth 7 "SMART_LIGHT_HEALTH_RESERVED" 6 "SMART_LIGHT_HEALTH_UPDATING" 5 "SMART_LIGHT_HEALTH_NOT_CONFIGURED" 4 "SMART_LIGHT_HEALTH_COMMS_OK_NO_LIGHT" 3 "SMART_LIGHT_HEALTH_OK" 2 "SMART_LIGHT_HEALTH_TIMEOUT" 1 "SMART_LIGHT_HEALTH_WAIT" 0 "SMART_LIGHT_HEALTH_OFF" ;
VAL_ 1014 VCFRONT_advancedDrivingBeamStatu 3 "ACTIVE_NO_COLUMNS_EXTINGUISHED" 2 "ACTIVE_SOME_COLUMNS_EXTINGUISHED" 1 "ENABLED_AND_INACTIVE" 0 "NOT_SUPPORTED_OR_DISABLED" ;
VAL_ 1014 VCFRONT_headlampRoadClass 3 "WET" 2 "MOTORWAY" 1 "TOWNLIGHT" 0 "NOMINAL" ;
